VERSION ""

NS_ :

BS_:

BU_: PC PUMPOT DC_DC2 DC_DC1 TTC_30 IMU CANoeSpy MBMS VCU VCVCCU CBCU TMS

BO_ 3221225472 VECTOR__INDEPENDENT_SIG_MSG: 0 Vector__XXX
 SG_ VCVCCU_ChargeUnit_Mode : 0|3@1+ (1,0) [0|0] "" Vector__XXX
 SG_ VCVCCU_Vehicle_ChargeSelection : 0|2@1+ (1,0) [0|3] "" Vector__XXX
 SG_ Year : 0|8@1+ (1,1985) [1985|2235] "Years" Vector__XXX
 SG_ Seconds : 0|8@1+ (0.25,0) [0|59.75] "s" Vector__XXX
 SG_ Month : 0|8@1+ (1,0) [1|12] "months" Vector__XXX
 SG_ Minutes : 0|32@1- (1,0) [0|59] "min" Vector__XXX
 SG_ LocalMinuteOffset : 0|8@1+ (1,-125) [-59|59] "min" Vector__XXX
 SG_ LocalHourOffset : 0|8@1+ (1,-125) [-23|23] "h" Vector__XXX
 SG_ Hours : 0|8@1+ (1,0) [0|23] "h" Vector__XXX
 SG_ Day : 0|8@1+ (0.25,0) [0.25|31.75] "" Vector__XXX
 SG_ SAE_J1587 : 0|2@1+ (1,0) [0|3] "" Vector__XXX
 SG_ DIAG_REQ_VCCU : 0|64@1+ (1,0) [0|1.84467440737096E+019] "" Vector__XXX
 SG_ VCVCCU_data_resp : 0|64@1+ (1,0) [0|0] "" Vector__XXX
 SG_ VCVCCU_data_cmd : 0|64@1+ (1,0) [0|0] "" Vector__XXX
 SG_ tx_error_count_Copy_1 : 0|8@1+ (1,0) [0|0] "" Vector__XXX
 SG_ motor_state : 0|3@1+ (1,0) [0|0] "" Vector__XXX
 SG_ inv_state : 0|3@1+ (1,0) [0|0] "" Vector__XXX
 SG_ spal_control_motor : 0|5@1+ (1,0) [0|0] "" Vector__XXX
 SG_ conclusion_state : 0|3@1+ (1,0) [0|0] "" Vector__XXX
 SG_ ATM_DAT7 : 0|8@1+ (1,0) [255|255] "" Vector__XXX
 SG_ ATM_DAT6 : 0|8@1+ (1,0) [255|255] "" Vector__XXX
 SG_ NewSignal_0018 : 0|8@1+ (1,0) [0|0] "" Vector__XXX
 SG_ Dashboard_Chart7 : 0|2@1+ (1,0) [0|3] "" Vector__XXX
 SG_ Dashboard_Chart6 : 0|2@1+ (1,0) [0|3] "" Vector__XXX
 SG_ Dashboard_Chart5 : 0|2@1+ (1,0) [0|3] "" Vector__XXX
 SG_ Dashboard_Chart4 : 0|2@1+ (1,0) [0|3] "" Vector__XXX
 SG_ Dashboard_Chart3 : 0|2@1+ (1,0) [0|3] "" Vector__XXX
 SG_ Dashboard_Chart2 : 0|2@1+ (1,0) [0|3] "" Vector__XXX
 SG_ Acc_Pedal_Chart2 : 0|3@1+ (1,0) [0|7] "" Vector__XXX
 SG_ Acc_Pedal_Chart3 : 0|2@1+ (1,0) [0|3] "" Vector__XXX
 SG_ Acc_Pedal_Chart1 : 0|2@1+ (1,0) [0|3] "" Vector__XXX
 SG_ TireLocation : 0|8@1+ (1,0) [0|0] "" Vector__XXX
 SG_ DataDictionaryRow : 0|4@1+ (1,0) [0|0] "" Vector__XXX
 SG_ DataDictionaryColumn : 0|4@1+ (1,0) [0|0] "" Vector__XXX
 SG_ ImplementPos : 0|4@1+ (1,0) [0|0] "" Vector__XXX
 SG_ DataFormat_ErrorCondition : 0|2@1+ (1,0) [0|0] "" Vector__XXX
 SG_ ProcessDataType : 0|2@1+ (1,0) [0|0] "" Vector__XXX
 SG_ ProcessDataModifier : 0|3@1+ (1,0) [0|0] "" Vector__XXX
 SG_ VehicleSystemInstanceQualifierFl : 0|1@1+ (1,0) [0|1] "" Vector__XXX
 SG_ VehicleRoll : 0|16@1+ (0.0078125,-200) [-90|90] "deg" Vector__XXX
 SG_ VehicleRetarderCtrlActive : 0|2@1+ (1,0) [0|3] "" Vector__XXX
 SG_ NOxConvertingCatalystAdsorberCom : 0|1@1+ (1,0) [0|1] "" Vector__XXX
 SG_ NOxConvertingCatalystAdsorberEna : 0|1@1+ (1,0) [0|1] "" Vector__XXX
 SG_ BoostPressureControlSystemComple : 0|1@1+ (1,0) [0|1] "" Vector__XXX
 SG_ BoostPressureControlSystemEnable : 0|1@1- (1,0) [0|0] "" Vector__XXX
 SG_ ExtlAccelerationDemand : 0|16@1+ (0.00048828125,-15.687) [-10|10] "m/s²" Vector__XXX
 SG_ IndustryGroup : 0|3@1+ (1,0) [0|7] "" Vector__XXX
 SG_ TestIdentifier : 0|8@1+ (1,0) [0|255] "" Vector__XXX
 SG_ NOxConvertingCatalystAdsorberSta : 0|1@1- (1,0) [0|0] "" Vector__XXX
 SG_ BoostPressureControlSystemSuppor : 0|1@1- (1,0) [0|0] "" Vector__XXX
 SG_ NOxConvertingCatalystAdsorberSup : 0|1@1- (1,0) [0|0] "" Vector__XXX
 SG_ AddressBusy : 0|8@1+ (1,0) [0|255] "" Vector__XXX
 SG_ ParameterGroupNumber : 0|24@1+ (1,0) [0|16777215] "" Vector__XXX
 SG_ GroupFunctionValue : 0|8@1+ (1,0) [0|255] "" Vector__XXX
 SG_ AddressAccessDenied : 0|8@1+ (1,0) [0|255] "" Vector__XXX
 SG_ AddressNegativeAcknowledgement : 0|8@1+ (1,0) [0|255] "" Vector__XXX
 SG_ AddressAcknowledged : 0|8@1+ (1,0) [0|255] "" Vector__XXX
 SG_ ControlByte : 0|8@1+ (1,0) [0|255] "" Vector__XXX
 SG_ AZG_RX_Byte_7 : 0|8@1+ (1,0) [0|0] "" Vector__XXX
 SG_ AZG_RX_Byte_6 : 0|8@1+ (1,0) [0|0] "" Vector__XXX
 SG_ AZG_RX_Byte_5 : 0|8@1+ (1,0) [0|0] "" Vector__XXX
 SG_ AZG_RX_Byte_4 : 0|8@1+ (1,0) [0|0] "" Vector__XXX
 SG_ AZG_RX_Byte_3 : 0|8@1+ (1,0) [0|0] "" Vector__XXX
 SG_ AZG_RX_Byte_2 : 0|8@1+ (1,0) [0|0] "" Vector__XXX
 SG_ AZG_RX_Byte_1 : 0|8@1+ (1,0) [0|0] "" Vector__XXX
 SG_ AZG_RX_Byte_0 : 0|8@1+ (1,0) [0|0] "" Vector__XXX
 SG_ AZG_TX_Byte_7 : 0|8@1+ (1,0) [0|0] "" Vector__XXX
 SG_ AZG_TX_Byte_6 : 0|8@1+ (1,0) [0|0] "" Vector__XXX
 SG_ AZG_TX_Byte_5 : 0|8@1+ (1,0) [0|0] "" Vector__XXX
 SG_ AZG_TX_Byte_4 : 0|8@1+ (1,0) [0|0] "" Vector__XXX
 SG_ AZG_TX_Byte_3 : 0|8@1+ (1,0) [0|0] "" Vector__XXX
 SG_ AZG_TX_Byte_2 : 0|8@1+ (1,0) [0|0] "" Vector__XXX
 SG_ AZG_TX_Byte_1 : 0|8@1+ (1,0) [0|0] "" Vector__XXX
 SG_ AZG_TX_Byte_0 : 0|8@1+ (1,0) [0|0] "" Vector__XXX
 SG_ EcuMeas_3_Byte_7 : 0|8@1+ (1,0) [0|0] "" Vector__XXX
 SG_ EcuMeas_3_Byte_6 : 0|8@1+ (1,0) [0|0] "" Vector__XXX
 SG_ EcuMeas_3_Byte_5 : 0|8@1+ (1,0) [0|0] "" Vector__XXX
 SG_ EcuMeas_3_Byte_4 : 0|8@1+ (1,0) [0|0] "" Vector__XXX
 SG_ EcuMeas_3_Byte_3 : 0|8@1+ (1,0) [0|0] "" Vector__XXX
 SG_ EcuMeas_3_Byte_2 : 0|8@1+ (1,0) [0|0] "" Vector__XXX
 SG_ EcuMeas_3_Byte_1 : 0|8@1+ (1,0) [0|0] "" Vector__XXX
 SG_ EcuMeas_3_Byte_0 : 0|8@1+ (1,0) [0|0] "" Vector__XXX
 SG_ EcuMeas_2_Byte_7 : 0|8@1+ (1,0) [0|0] "" Vector__XXX
 SG_ EcuMeas_2_Byte_6 : 0|8@1+ (1,0) [0|0] "" Vector__XXX
 SG_ EcuMeas_2_Byte_5 : 0|8@1+ (1,0) [0|0] "" Vector__XXX
 SG_ EcuMeas_2_Byte_4 : 0|8@1+ (1,0) [0|0] "" Vector__XXX
 SG_ EcuMeas_2_Byte_3 : 0|8@1+ (1,0) [0|0] "" Vector__XXX
 SG_ EcuMeas_2_Byte_2 : 0|8@1+ (1,0) [0|0] "" Vector__XXX
 SG_ EcuMeas_2_Byte_1 : 0|8@1+ (1,0) [0|0] "" Vector__XXX
 SG_ EcuMeas_2_Byte_0 : 0|8@1+ (1,0) [0|0] "" Vector__XXX
 SG_ EcuMeas_1_Byte_7 : 0|8@1+ (1,0) [0|0] "" Vector__XXX
 SG_ EcuMeas_1_Byte_6 : 0|8@1+ (1,0) [0|0] "" Vector__XXX
 SG_ EcuMeas_1_Byte_5 : 0|8@1+ (1,0) [0|0] "" Vector__XXX
 SG_ EcuMeas_1_Byte_4 : 0|8@1+ (1,0) [0|0] "" Vector__XXX
 SG_ EcuMeas_1_Byte_3 : 0|8@1+ (1,0) [0|0] "" Vector__XXX
 SG_ EcuMeas_1_Byte_2 : 0|8@1+ (1,0) [0|0] "" Vector__XXX
 SG_ EcuMeas_1_Byte_1 : 0|8@1+ (1,0) [0|0] "" Vector__XXX
 SG_ EcuMeas_1_Byte_0 : 0|8@1+ (1,0) [0|0] "" Vector__XXX
 SG_ EcuMeas_0_Byte_7 : 0|8@1+ (1,0) [0|0] "" Vector__XXX
 SG_ EcuMeas_0_Byte_6 : 0|8@1+ (1,0) [0|0] "" Vector__XXX
 SG_ EcuMeas_0_Byte_5 : 0|8@1+ (1,0) [0|0] "" Vector__XXX
 SG_ EcuMeas_0_Byte_4 : 0|8@1+ (1,0) [0|0] "" Vector__XXX
 SG_ EcuMeas_0_Byte_3 : 0|8@1+ (1,0) [0|0] "" Vector__XXX
 SG_ EcuMeas_0_Byte_2 : 0|8@1+ (1,0) [0|0] "" Vector__XXX
 SG_ EcuMeas_0_Byte_1 : 0|8@1+ (1,0) [0|0] "" Vector__XXX
 SG_ EcuMeas_0_Byte_0 : 0|8@1+ (1,0) [0|0] "" Vector__XXX
 SG_ CCP_TX_Byte_7 : 0|8@1+ (1,0) [0|0] "" Vector__XXX
 SG_ CCP_TX_Byte_6 : 0|8@1+ (1,0) [0|0] "" Vector__XXX
 SG_ CCP_TX_Byte_5 : 0|8@1+ (1,0) [0|0] "" Vector__XXX
 SG_ CCP_TX_Byte_4 : 0|8@1+ (1,0) [0|0] "" Vector__XXX
 SG_ CCP_TX_Byte_3 : 0|8@1+ (1,0) [0|0] "" Vector__XXX
 SG_ CCP_TX_Byte_2 : 0|8@1+ (1,0) [0|0] "" Vector__XXX
 SG_ CCP_TX_Byte_1 : 0|8@1+ (1,0) [0|0] "" Vector__XXX
 SG_ CCP_TX_Byte_0 : 0|8@1+ (1,0) [0|0] "" Vector__XXX
 SG_ CCP_RX_Byte_7 : 0|8@1+ (1,0) [0|0] "" Vector__XXX
 SG_ CCP_RX_Byte_6 : 0|8@1+ (1,0) [0|0] "" Vector__XXX
 SG_ CCP_RX_Byte_5 : 0|8@1+ (1,0) [0|0] "" Vector__XXX
 SG_ CCP_RX_Byte_4 : 0|8@1+ (1,0) [0|0] "" Vector__XXX
 SG_ CCP_RX_Byte_3 : 0|8@1+ (1,0) [0|0] "" Vector__XXX
 SG_ CCP_RX_Byte_2 : 0|8@1+ (1,0) [0|0] "" Vector__XXX
 SG_ CCP_RX_Byte_1 : 0|8@1+ (1,0) [0|0] "" Vector__XXX
 SG_ CCP_RX_Byte_0 : 0|8@1+ (1,0) [0|0] "" Vector__XXX
 SG_ YawRate_ISig_3 : 0|16@1+ (0.000122,-3.92) [-3.92|4.07527] "Rad_per_s" Vector__XXX
 SG_ LateralAcceleration_ISig_3 : 0|16@1+ (0.00048828125,-15.687) [-15.687|16.312511719] "m_per_s_squared" Vector__XXX
 SG_ SteeringWheelTurnCounter_ISig_3 : 0|6@1+ (1,-32) [-32|31] "turns" Vector__XXX
 SG_ SteeringWheelAngleSensorType : 0|2@1+ (1,0) [0|0] "" Vector__XXX
 SG_ SteeringWheelAngle_ISig_3 : 0|16@1+ (0.0009765625,-31.374) [-31.374|32.625023437] "rad" Vector__XXX
 SG_ MessageChecksum : 0|4@1+ (1,0) [0|15] "" Vector__XXX
 SG_ MessageCounter : 0|4@1+ (1,0) [0|15] "" Vector__XXX
 SG_ SteerAngleSensorCalibrated : 0|2@1+ (1,0) [0|3] "" Vector__XXX
 SG_ SteerAngleSensorActiveMode : 0|2@1+ (1,0) [0|3] "" Vector__XXX
 SG_ SteerWheelAngleRange : 0|16@1+ (0.0009765625,-31.374) [0|31.374] "rad" Vector__XXX
 SG_ SteerWheelAngleRangeCounterType : 0|2@1+ (1,0) [0|3] "" Vector__XXX
 SG_ SteerWheelAngleRangeCounter : 0|6@1+ (1,-32) [-32|29] "ranges" Vector__XXX
 SG_ SteerWheelAngle : 0|16@1+ (0.0009765625,-31.374) [-31.374|31.374] "rad" Vector__XXX
 SG_ EHPS_DesPumpSpeed : 0|16@1+ (1,0) [0|8000] "rpm" Vector__XXX
 SG_ TachographVehicleSpeed : 0|16@1+ (0.00390625,0) [0|250.996] "km/h" Vector__XXX
 SG_ TachographOutputShaftSpeed : 0|16@1+ (0.125,0) [0|8031.875] "rpm" Vector__XXX
 SG_ DirectionIndicator : 0|2@1+ (1,0) [0|3] "" Vector__XXX
 SG_ TachographPerformance : 0|2@1+ (1,0) [0|3] "" Vector__XXX
 SG_ HandlingInformation : 0|2@1+ (1,0) [0|3] "" Vector__XXX
 SG_ SystemEvent : 0|2@1+ (1,0) [0|3] "" Vector__XXX
 SG_ DriverCardDriver2 : 0|2@1+ (1,0) [0|3] "" Vector__XXX
 SG_ Driver2TimeRelatedStates : 0|4@1+ (1,0) [0|15] "" Vector__XXX
 SG_ VehicleOverspeed : 0|2@1+ (1,0) [0|3] "" Vector__XXX
 SG_ DriverCardDriver1 : 0|2@1+ (1,0) [0|3] "" Vector__XXX
 SG_ Driver1TimeRelatedStates : 0|4@1+ (1,0) [0|15] "" Vector__XXX
 SG_ Driver1WorkingState : 0|3@1+ (1,0) [0|7] "" Vector__XXX
 SG_ VehicleMotion : 0|2@1+ (1,0) [0|3] "" Vector__XXX
 SG_ Driver2WorkingState : 0|3@1+ (1,0) [0|7] "" Vector__XXX
 SG_ RelativeSpeedRearAxle2RightWhel : 0|8@1+ (0.06025,-7.8125) [-7.8125|7.8125] "km/h" Vector__XXX
 SG_ RelativeSpeedRearAxle2LeftWhel : 0|8@1+ (0.0625,-7.8125) [-7.8125|7.8125] "km/h" Vector__XXX
 SG_ RelativeSpeedRearAxle1LeftWhel : 0|8@1+ (0.0625,-7.8125) [-7.8125|7.8125] "km/h" Vector__XXX
 SG_ RelativeSpeedRearAxle1RightWhel : 0|8@1+ (0.0625,-7.8125) [-7.8125|7.8125] "km/h" Vector__XXX
 SG_ RelativeSpeedFrontAxleRightWheel : 0|8@1+ (0.0625,-7.8125) [-7.8125|7.8125] "km/h" Vector__XXX
 SG_ RelativeSpeedFrontAxleLeftWheel : 0|8@1+ (0.0625,-7.8125) [-7.8125|7.8125] "km/h" Vector__XXX
 SG_ FrontAxleSpeed : 0|16@1+ (0.00390625,0) [0|250.996] "km/h" Vector__XXX
 SG_ MotorTorque : 0|16@1+ (1,-31.374) [-31.374|31.374] "Nm" Vector__XXX
 SG_ HandsOffProbability : 0|8@1+ (1,0) [0|100] "%" Vector__XXX
 SG_ ExtControlMode : 0|4@1+ (1,0) [0|0] "" Vector__XXX
 SG_ DriverTorque : 0|16@1+ (0.0009765625,-31.374) [-31.374|31.374] "Nm" Vector__XXX
 SG_ CRC : 0|8@1+ (1,0) [0|0] "" Vector__XXX
 SG_ MC : 0|4@1+ (1,0) [0|0] "" Vector__XXX
 SG_ SysState : 0|4@1+ (1,0) [0|0] "" Vector__XXX
 SG_ SteeringAngleSpeed : 0|16@1+ (0.1,-3212.7) [-3212.7|3212.8] "°/s" Vector__XXX
 SG_ SteeringAngle : 0|16@1+ (0.1,-3212.7) [-3212.7|3212.8] "°" Vector__XXX
 SG_ EngDemandPercentTorque : 0|8@1+ (1,-125) [-125|125] "%" Vector__XXX
 SG_ SrcAddrssOfCntrllngDvcForEngCtrl : 0|8@1+ (1,0) [0|253] "" Vector__XXX
 SG_ ActlEngPrcntTorqueHighResolution : 0|4@1+ (0.125,0) [0|1.875] "%" Vector__XXX
 SG_ EngStarterMode : 0|4@1+ (1,0) [0|15] "" Vector__XXX
 SG_ EngSpeed : 0|16@1+ (0.125,0) [0|8031.875] "rpm" Vector__XXX
 SG_ ActualEngPercentTorque : 0|8@1+ (1,-125) [0|125] "%" Vector__XXX
 SG_ DriversDemandEngPercentTorque : 0|8@1+ (1,-125) [0|125] "%" Vector__XXX
 SG_ EngTorqueMode : 0|4@1+ (1,0) [0|15] "" Vector__XXX
 SG_ Ph_H : 0|8@1+ (100,0) [0|201326492] "Wh" Vector__XXX
 SG_ Ph_HM : 0|8@1+ (100,0) [0|201326492] "Wh" Vector__XXX
 SG_ Ph_LM : 0|8@1+ (100,0) [0|201326492] "Wh" Vector__XXX
 SG_ Ph_L : 0|8@1+ (100,0) [0|201326492] "Wh" Vector__XXX
 SG_ Ih_H : 0|8@1+ (100,0) [0|201326492] "Ah" Vector__XXX
 SG_ Ih_HM : 0|8@1+ (100,0) [0|201326492] "Ah" Vector__XXX
 SG_ ACDC_Temperature : 0|8@1+ (1,-40) [-40|210] "°C" Vector__XXX
 SG_ SG_StatusFeedBack : 0|1@1+ (1,0) [0|71] "" Vector__XXX
 SG_ DTC5 : 0|32@1+ (1,0) [-1|0] "" Vector__XXX
 SG_ DTC4 : 0|32@1+ (1,0) [-1|0] "" Vector__XXX
 SG_ DTC3 : 0|32@1+ (1,0) [-1|0] "" Vector__XXX
 SG_ DTC2 : 0|32@1+ (1,0) [-1|0] "" Vector__XXX
 SG_ DTC1 : 0|32@1+ (1,0) [-1|0] "" Vector__XXX
 SG_ AnswerMode2 : 0|8@1+ (1,0) [0|0] "" Vector__XXX
 SG_ VersionSoftRequest : 0|8@1+ (1,0) [0|255] "" Vector__XXX
 SG_ FlashRedStoplamp : 0|8@1+ (1,0) [0|0] "" Vector__XXX
 SG_ Irbis_TurnOff : 0|1@1+ (1,0) [0|0] "" Vector__XXX
 SG_ BTMDemandPowerHighLowBytes_Copy_ : 0|16@1+ (0.1,0) [0|6553.5] "kW" Vector__XXX
 SG_ Datchick_toka : 0|16@1+ (1,0) [0|65535] "" Vector__XXX
 SG_ PropulsionSystemActive : 0|2@1+ (1,0) [0|0] "" Vector__XXX
 SG_ HybridSystemWarningIndicator : 0|2@1+ (1,0) [0|0] "" Vector__XXX
 SG_ HybridSystemStopIndicator : 0|2@1+ (1,0) [0|0] "" Vector__XXX
 SG_ HybridSystemServiceIndicator : 0|2@1+ (1,0) [0|0] "" Vector__XXX
 SG_ HybridSystemRegenerativeBrakingI : 0|2@1+ (1,0) [0|0] "" Vector__XXX
 SG_ HybridSystemOverheatIndicator : 0|2@1+ (1,0) [0|0] "" Vector__XXX
 SG_ HybridSystemOBDRelatedDTCStatus : 0|2@1+ (1,0) [0|0] "" Vector__XXX
 SG_ HybridSystemMotorOverspeedIndica : 0|2@1+ (1,0) [0|0] "" Vector__XXX
 SG_ HybridSystemMotorOverspeedAlarm : 0|2@1+ (1,0) [0|0] "" Vector__XXX
 SG_ HybridSystemInitialisationIndica : 0|2@1+ (1,0) [0|0] "" Vector__XXX
 SG_ HybridSystemHighVoltageExposureI : 0|2@1+ (1,0) [0|0] "" Vector__XXX
 SG_ HybridSystemEngineAssistStatus : 0|2@1+ (1,0) [0|0] "" Vector__XXX
 SG_ HybridSystemElectricAlternatorIn : 0|2@1+ (1,0) [0|0] "" Vector__XXX
 SG_ HybridPropulsionModeTransitionSt : 0|4@1+ (1,0) [0|0] "" Vector__XXX
 SG_ HybridPropulsionModeStatus : 0|4@1+ (1,0) [0|0] "" Vector__XXX
 SG_ ExternalEnergySourceConnectionSt : 0|4@1+ (1,0) [0|0] "" Vector__XXX
 SG_ StoredEnergyLevel : 0|8@1+ (1,0) [0|100] "%" Vector__XXX
 SG_ PowerOnSignal : 0|2@1+ (1,0) [0|0] "" Vector__XXX
 SG_ DestinationMode : 0|3@1+ (1,0) [0|0] "" Vector__XXX
 SG_ CurrentVehicleMode : 0|3@1+ (1,0) [0|0] "" Vector__XXX
 SG_ SIM100_vb : 0|16@1+ (1,0) [0|0] "" Vector__XXX
 SG_ var6_Copy_1 : 0|24@1+ (1,0) [0|0] "" Vector__XXX
 SG_ saturation2_min_variable_Copy_1 : 0|8@1+ (1,0) [0|0] "" Vector__XXX
 SG_ saturation2_max_variable_Copy_1 : 0|8@1+ (1,0) [0|0] "" Vector__XXX
 SG_ saturation1_min_variable_Copy_1 : 0|8@1+ (1,0) [0|0] "" Vector__XXX
 SG_ saturation1_max_variable_Copy_1 : 0|8@1+ (1,0) [0|0] "" Vector__XXX
 SG_ IBS_looses_recalibration_SOC : 0|2@1+ (1,0) [0|0] "" Vector__XXX
 SG_ Battery_Defect_Detected : 0|2@1+ (1,0) [0|0] "" Vector__XXX
 SG_ Battery_Acid_Stratification : 0|2@1+ (1,0) [0|0] "" Vector__XXX
 SG_ Battery_Sulfation : 0|2@1+ (1,0) [0|0] "" Vector__XXX
 SG_ CentreTapDifference : 0|8@1+ (1,0) [0|0] "" Vector__XXX
 SG_ SOH_CCA : 0|8@1+ (0.5,0) [0|100] "" Vector__XXX
 SG_ CapacityLossBottom : 0|8@1+ (0.5,0) [0|0] "" Vector__XXX
 SG_ CapacityLossTop : 0|8@1+ (0.5,0) [0|0] "" Vector__XXX
 SG_ SOH : 0|8@1+ (0.5,0) [0|100] "" Vector__XXX
 SG_ NumberOfMembersInWorkingSet : 0|8@1+ (1,0) [0|0] "" Vector__XXX
 SG_ SourceAddress : 0|8@1+ (1,0) [0|0] "" Vector__XXX
 SG_ NncntnuslyMonitoredSystemsStatus : 0|16@1+ (1,0) [0|0] "" Vector__XXX
 SG_ NncntnslyMonitoredSystemsSupport : 0|16@1+ (1,0) [0|0] "" Vector__XXX
 SG_ CntnslyMntrdSystmsSupport_Status : 0|8@1+ (1,0) [0|0] "" Vector__XXX
 SG_ AETCTorqueValue : 0|16@1+ (1,0) [0|64255] "Nm" Vector__XXX
 SG_ TrailerWeight : 0|16@1+ (2,0) [0|128510] "kg" Vector__XXX
 SG_ ReferenceTirePressSetting : 0|8@1+ (8,0) [0|2000] "kPa" Vector__XXX
 SG_ ReferenceTirePress : 0|8@1+ (8,0) [0|2000] "kPa" Vector__XXX
 SG_ TirePressThresholdDetection : 0|3@1+ (1,0) [0|7] "" Vector__XXX
 SG_ TireAirLeakageRate : 0|16@1+ (0.1,0) [0|6425.5] "Pa/s" Vector__XXX
 SG_ CTIWheelEndElectricalFault : 0|2@1+ (1,0) [0|3] "" Vector__XXX
 SG_ CTITireStatus : 0|2@1+ (1,0) [0|3] "" Vector__XXX
 SG_ CTIWheelSensorStatus : 0|2@1+ (1,0) [0|3] "" Vector__XXX
 SG_ TireTemp : 0|16@1+ (0.03125,-273) [-273|1734.96875] "deg C" Vector__XXX
 SG_ TirePress : 0|8@1+ (4,0) [0|1000] "kPa" Vector__XXX
 SG_ EngTurningGearEngaged : 0|2@1+ (1,0) [0|3] "" Vector__XXX
 SG_ AETCSpeedValue : 0|16@1+ (0.125,0) [0|8031.875] "rpm" Vector__XXX
 SG_ SWfirst_B : 0|8@0+ (1,0) [0|255] "" Vector__XXX
 SG_ SWsecond_B : 0|8@0+ (1,0) [0|255] "" Vector__XXX
 SG_ SWThird_B : 0|8@0+ (1,0) [0|1] "" Vector__XXX
 SG_ SWFourth_B : 0|8@0+ (1,0) [0|255] "" Vector__XXX
 SG_ SWFifth_B : 0|8@0+ (1,0) [0|255] "" Vector__XXX
 SG_ SWsixth_B : 0|8@0+ (1,0) [0|1] "" Vector__XXX
 SG_ SWseventh_B : 0|8@0+ (1,0) [0|1] "" Vector__XXX
 SG_ SWeight_B : 0|8@0+ (1,0) [0|1] "" Vector__XXX
 SG_ SWfirst_C : 0|8@0+ (1,0) [0|255] "" Vector__XXX
 SG_ SWsecond_C : 0|8@0+ (1,0) [0|255] "" Vector__XXX
 SG_ SWThird_C : 0|8@0+ (1,0) [0|1] "" Vector__XXX
 SG_ SWFourth_C : 0|8@0+ (1,0) [0|255] "" Vector__XXX
 SG_ SWFifth_C : 0|8@0+ (1,0) [0|255] "" Vector__XXX
 SG_ SWsixth_C : 0|8@0+ (1,0) [0|1] "" Vector__XXX
 SG_ SWseventh_C : 0|8@0+ (1,0) [0|1] "" Vector__XXX
 SG_ SWeight_C : 0|8@0+ (1,0) [0|1] "" Vector__XXX
 SG_ SWfirst_D : 0|8@0+ (1,0) [0|255] "" Vector__XXX
 SG_ SWsecond_D : 0|8@0+ (1,0) [0|255] "" Vector__XXX
 SG_ SWThird_D : 0|8@0+ (1,0) [0|1] "" Vector__XXX
 SG_ SWFourth_D : 0|8@0+ (1,0) [0|255] "" Vector__XXX
 SG_ SWFifth_D : 0|8@0+ (1,0) [0|255] "" Vector__XXX
 SG_ SWsixth_D : 0|8@0+ (1,0) [0|1] "" Vector__XXX
 SG_ SWseventh_D : 0|8@0+ (1,0) [0|1] "" Vector__XXX
 SG_ SWeight_D : 0|8@0+ (1,0) [0|1] "" Vector__XXX
 SG_ SWfirst_E : 0|8@0+ (1,0) [0|255] "" Vector__XXX
 SG_ SWsecond_E : 0|8@0+ (1,0) [0|255] "" Vector__XXX
 SG_ SWThird_E : 0|8@0+ (1,0) [0|1] "" Vector__XXX
 SG_ SWFourth_E : 0|8@0+ (1,0) [0|255] "" Vector__XXX
 SG_ SWFifth_E : 0|8@0+ (1,0) [0|255] "" Vector__XXX
 SG_ SWsixth_E : 0|8@0+ (1,0) [0|1] "" Vector__XXX
 SG_ SWseventh_E : 0|8@0+ (1,0) [0|1] "" Vector__XXX
 SG_ SWeight_E : 0|8@0+ (1,0) [0|1] "" Vector__XXX
 SG_ SWfirst_F : 0|8@0+ (1,0) [0|255] "" Vector__XXX
 SG_ SWsecond_F : 0|8@0+ (1,0) [0|255] "" Vector__XXX
 SG_ SWThird_F : 0|8@0+ (1,0) [0|1] "" Vector__XXX
 SG_ SWFourth_F : 0|8@0+ (1,0) [0|255] "" Vector__XXX
 SG_ SWFifth_F : 0|8@0+ (1,0) [0|255] "" Vector__XXX
 SG_ SWsixth_F : 0|8@0+ (1,0) [0|1] "" Vector__XXX
 SG_ SWseventh_F : 0|8@0+ (1,0) [0|1] "" Vector__XXX
 SG_ SWeight_F : 0|8@0+ (1,0) [0|1] "" Vector__XXX
 SG_ SWfirst_G : 0|8@0+ (1,0) [0|255] "" Vector__XXX
 SG_ SWsecond_G : 0|8@0+ (1,0) [0|255] "" Vector__XXX
 SG_ SWThird_G : 0|8@0+ (1,0) [0|1] "" Vector__XXX
 SG_ SWFourth_G : 0|8@0+ (1,0) [0|255] "" Vector__XXX
 SG_ SWFifth_G : 0|8@0+ (1,0) [0|255] "" Vector__XXX
 SG_ SWsixth_G : 0|8@0+ (1,0) [0|1] "" Vector__XXX
 SG_ SWseventh_G : 0|8@0+ (1,0) [0|1] "" Vector__XXX
 SG_ SWeight_G : 0|8@0+ (1,0) [0|1] "" Vector__XXX
 SG_ SWfirst_H : 0|8@0+ (1,0) [0|255] "" Vector__XXX
 SG_ SWsecond_H : 0|8@0+ (1,0) [0|255] "" Vector__XXX
 SG_ SWThird_H : 0|8@0+ (1,0) [0|1] "" Vector__XXX
 SG_ SWFourth_H : 0|8@0+ (1,0) [0|255] "" Vector__XXX
 SG_ SWFifth_H : 0|8@0+ (1,0) [0|255] "" Vector__XXX
 SG_ SWsixth_H : 0|8@0+ (1,0) [0|1] "" Vector__XXX
 SG_ SWseventh_H : 0|8@0+ (1,0) [0|1] "" Vector__XXX
 SG_ SWeight_H : 0|8@0+ (1,0) [0|1] "" Vector__XXX
 SG_ SWfirst_I : 0|8@0+ (1,0) [0|255] "" Vector__XXX
 SG_ SWsecond_I : 0|8@0+ (1,0) [0|255] "" Vector__XXX
 SG_ SWThird_I : 0|8@0+ (1,0) [0|1] "" Vector__XXX
 SG_ SWFourth_I : 0|8@0+ (1,0) [0|255] "" Vector__XXX
 SG_ SWFifth_I : 0|8@0+ (1,0) [0|255] "" Vector__XXX
 SG_ SWsixth_I : 0|8@0+ (1,0) [0|1] "" Vector__XXX
 SG_ SWseventh_I : 0|8@0+ (1,0) [0|1] "" Vector__XXX
 SG_ SWeight_I : 0|8@0+ (1,0) [0|1] "" Vector__XXX
 SG_ SWfirst_L : 0|8@0+ (1,0) [0|255] "" Vector__XXX
 SG_ SWsecond_L : 0|8@0+ (1,0) [0|255] "" Vector__XXX
 SG_ SWThird_L : 0|8@0+ (1,0) [0|1] "" Vector__XXX
 SG_ SWFourth_L : 0|8@0+ (1,0) [0|255] "" Vector__XXX
 SG_ SWFifth_L : 0|8@0+ (1,0) [0|255] "" Vector__XXX
 SG_ SWsixth_L : 0|8@0+ (1,0) [0|1] "" Vector__XXX
 SG_ SWseventh_L : 0|8@0+ (1,0) [0|1] "" Vector__XXX
 SG_ SWeight_L : 0|8@0+ (1,0) [0|1] "" Vector__XXX
 SG_ SWfirst_M : 0|8@0+ (1,0) [0|255] "" Vector__XXX
 SG_ SWsecond_M : 0|8@0+ (1,0) [0|255] "" Vector__XXX
 SG_ SWThird_M : 0|8@0+ (1,0) [0|1] "" Vector__XXX
 SG_ SWFourth_M : 0|8@0+ (1,0) [0|255] "" Vector__XXX
 SG_ SWFifth_M : 0|8@0+ (1,0) [0|255] "" Vector__XXX
 SG_ SWsixth_M : 0|8@0+ (1,0) [0|1] "" Vector__XXX
 SG_ SWseventh_M : 0|8@0+ (1,0) [0|1] "" Vector__XXX
 SG_ SWeight_M : 0|8@0+ (1,0) [0|1] "" Vector__XXX
 SG_ SWfirst_N : 0|8@0+ (1,0) [0|255] "" Vector__XXX
 SG_ SWsecond_N : 0|8@0+ (1,0) [0|255] "" Vector__XXX
 SG_ SWThird_N : 0|8@0+ (1,0) [0|1] "" Vector__XXX
 SG_ SWFourth_N : 0|8@0+ (1,0) [0|255] "" Vector__XXX
 SG_ SWFifth_N : 0|8@0+ (1,0) [0|255] "" Vector__XXX
 SG_ SWsixth_N : 0|8@0+ (1,0) [0|1] "" Vector__XXX
 SG_ SWseventh_N : 0|8@0+ (1,0) [0|1] "" Vector__XXX
 SG_ SWeight_N : 0|8@0+ (1,0) [0|1] "" Vector__XXX
 SG_ SWfirst_Q : 0|8@0+ (1,0) [0|255] "" Vector__XXX
 SG_ SWsecond_Q : 0|8@0+ (1,0) [0|255] "" Vector__XXX
 SG_ SWThird_Q : 0|8@0+ (1,0) [0|1] "" Vector__XXX
 SG_ SWFourth_Q : 0|8@0+ (1,0) [0|255] "" Vector__XXX
 SG_ SWFifth_Q : 0|8@0+ (1,0) [0|255] "" Vector__XXX
 SG_ SWsixth_Q : 0|8@0+ (1,0) [0|1] "" Vector__XXX
 SG_ SWseventh_Q : 0|8@0+ (1,0) [0|1] "" Vector__XXX
 SG_ SWeight_Q : 0|8@0+ (1,0) [0|1] "" Vector__XXX
 SG_ SWfirst_R : 0|8@0+ (1,0) [0|255] "" Vector__XXX
 SG_ SWsecond_R : 0|8@0+ (1,0) [0|255] "" Vector__XXX
 SG_ SWThird_R : 0|8@0+ (1,0) [0|1] "" Vector__XXX
 SG_ SWFourth_R : 0|8@0+ (1,0) [0|255] "" Vector__XXX
 SG_ SWFifth_R : 0|8@0+ (1,0) [0|255] "" Vector__XXX
 SG_ SWsixth_R : 0|8@0+ (1,0) [0|1] "" Vector__XXX
 SG_ SWseventh_R : 0|8@0+ (1,0) [0|1] "" Vector__XXX
 SG_ SWeight_R : 0|8@0+ (1,0) [0|1] "" Vector__XXX
 SG_ Tst2_3Pconfig_C : 0|1@0+ (1,0) [0|1] "" Vector__XXX
 SG_ Tst2Slave_C : 0|1@1+ (1,0) [0|1] "" Vector__XXX
 SG_ IMU_Check : 0|1@1+ (1,0) [0|0] "" Vector__XXX
 SG_ Reserved2 : 0|8@1+ (1,0) [0|0] "" Vector__XXX
 SG_ Reserved1 : 0|2@1+ (1,0) [0|0] "" Vector__XXX
 SG_ Reserved : 0|2@1+ (1,0) [0|0] "" Vector__XXX
 SG_ BMSCurrentVoltageLowByte : 0|8@1+ (1,0) [0|1000] "" Vector__XXX
 SG_ BMSHighVoltageRelayStatus : 0|2@1+ (1,0) [0|3] "" Vector__XXX
 SG_ Isolation_measur_req_by_vcvccu : 0|2@1+ (1,0) [0|0] "" Vector__XXX
 SG_ Voltage_sensor_PDU1 : 0|16@1+ (1,0) [0|65535] "" Vector__XXX
 SG_ Voltage_sensor_PDU2 : 0|16@1+ (1,0) [0|65535] "" Vector__XXX
 SG_ VCUSendsBusVoltHighLowBytes : 0|16@0+ (1,0) [0|1000] "V" Vector__XXX
 SG_ BTMDemandPowerHighLowBytes : 0|16@1+ (0.1,0) [0|6553.5] "kW" Vector__XXX
 SG_ L_byte_offset : 0|8@1+ (1,0) [0|255] "" Vector__XXX
 SG_ H_bye_Offset : 0|8@1+ (1,0) [0|255] "" Vector__XXX
 SG_ VCVCCU_seconds_variable : 0|8@1+ (1,0) [0|0] "" Vector__XXX
 SG_ EVErrorCode : 0|8@1+ (1,0) [0|0] "" Vector__XXX
 SG_ Link_voltage : 0|16@1+ (1,0) [0|0] "" Vector__XXX
 SG_ EVRSSSOC : 0|8@1+ (1,0) [0|0] "" Vector__XXX
 SG_ EVTargetVoltage_Multiplier : 0|8@1+ (1,0) [0|0] "" Vector__XXX
 SG_ EVTargetCurrent_Multiplier : 0|8@1+ (1,0) [0|0] "" Vector__XXX
 SG_ EVMaximumVoltageLimit_Multiplier : 0|8@1+ (1,0) [0|0] "" Vector__XXX
 SG_ HL_byte : 0|16@0+ (1,0) [0|65535] "" Vector__XXX
 SG_ Pantograph_heating : 0|1@1+ (1,0) [0|0] "" Vector__XXX
 SG_ MainContactorState : 0|2@1+ (1,0) [0|0] "" Vector__XXX
 SG_ ActualBatterySystemVoltage : 0|8@1+ (3.4,0) [0|867] "V" Vector__XXX
 SG_ ActualBatterySystemCurrent : 0|8@1- (4,0) [-512|508] "A" Vector__XXX
 SG_ MaximumBatterySystemVoltage : 0|8@1+ (3.4,0) [0|850] "V" Vector__XXX
 SG_ MaximumBatterySystemChargeCurren : 0|8@1+ (2,0) [0|510] "A" Vector__XXX
 SG_ Byte2 : 0|8@1+ (1,0) [0|0] "" Vector__XXX
 SG_ Byte1 : 0|8@1+ (1,0) [0|0] "" Vector__XXX
 SG_ diag_state : 0|16@1+ (1,0) [0|0] "" Vector__XXX
 SG_ k15_status : 0|1@1+ (1,0) [0|0] "" Vector__XXX
 SG_ usability_check : 0|1@1+ (1,0) [0|0] "" Vector__XXX
 SG_ unsuccessful_session : 0|8@1+ (1,0) [0|0] "" Vector__XXX
 SG_ aborted_session : 0|8@1+ (1,0) [0|0] "" Vector__XXX
 SG_ success_session : 0|8@1+ (1,0) [0|0] "" Vector__XXX

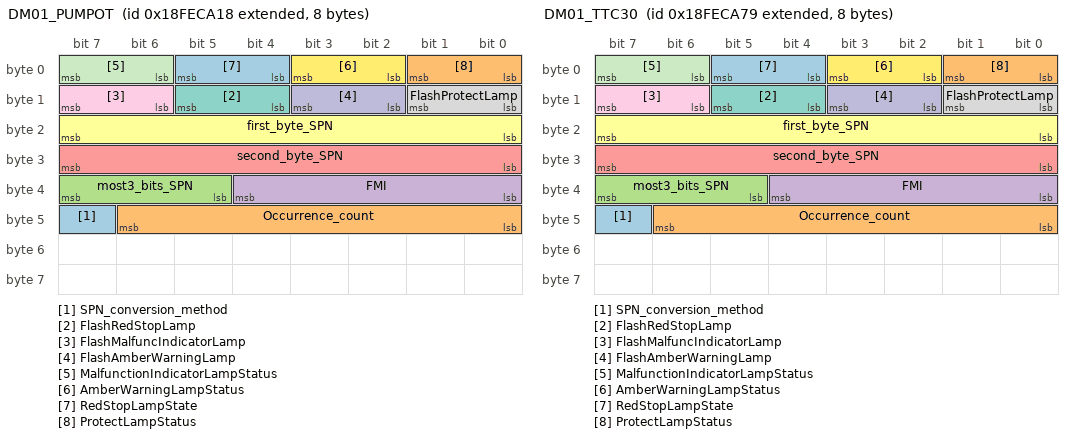
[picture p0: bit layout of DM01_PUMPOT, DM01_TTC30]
BO_ 2566834712 DM01_PUMPOT: 8 Vector__XXX
 SG_ SPN_conversion_method : 47|1@1+ (1,0) [0|0] "" Vector__XXX
 SG_ Occurrence_count : 40|7@1+ (1,0) [0|0] "" Vector__XXX
 SG_ most3_bits_SPN : 37|3@1+ (1,0) [0|0] "" Vector__XXX
 SG_ FMI : 32|5@1+ (1,0) [0|31] "" Vector__XXX
 SG_ second_byte_SPN : 24|8@1+ (1,0) [0|0] "" Vector__XXX
 SG_ first_byte_SPN : 16|8@1+ (1,0) [0|255] "" Vector__XXX
 SG_ FlashRedStopLamp : 12|2@1+ (1,0) [0|3] "" Vector__XXX
 SG_ FlashProtectLamp : 8|2@1+ (1,0) [0|3] "" Vector__XXX
 SG_ FlashMalfuncIndicatorLamp : 14|2@1+ (1,0) [0|3] "" Vector__XXX
 SG_ FlashAmberWarningLamp : 10|2@1+ (1,0) [0|3] "" Vector__XXX
 SG_ MalfunctionIndicatorLampStatus : 6|2@1+ (1,0) [0|3] "" Vector__XXX
 SG_ AmberWarningLampStatus : 2|2@1+ (1,0) [0|3] "" Vector__XXX
 SG_ RedStopLampState : 4|2@1+ (1,0) [0|3] "" Vector__XXX
 SG_ ProtectLampStatus : 0|2@1+ (1,0) [0|3] "" Vector__XXX

BO_ 2566834809 DM01_TTC30: 8 Vector__XXX
 SG_ SPN_conversion_method : 47|1@1+ (1,0) [0|0] "" Vector__XXX
 SG_ Occurrence_count : 40|7@1+ (1,0) [0|0] "" Vector__XXX
 SG_ most3_bits_SPN : 37|3@1+ (1,0) [0|0] "" Vector__XXX
 SG_ FMI : 32|5@1+ (1,0) [0|31] "" Vector__XXX
 SG_ second_byte_SPN : 24|8@1+ (1,0) [0|0] "" Vector__XXX
 SG_ first_byte_SPN : 16|8@1+ (1,0) [0|255] "" Vector__XXX
 SG_ FlashRedStopLamp : 12|2@1+ (1,0) [0|3] "" Vector__XXX
 SG_ FlashProtectLamp : 8|2@1+ (1,0) [0|3] "" Vector__XXX
 SG_ FlashMalfuncIndicatorLamp : 14|2@1+ (1,0) [0|3] "" Vector__XXX
 SG_ FlashAmberWarningLamp : 10|2@1+ (1,0) [0|3] "" Vector__XXX
 SG_ MalfunctionIndicatorLampStatus : 6|2@1+ (1,0) [0|3] "" Vector__XXX
 SG_ AmberWarningLampStatus : 2|2@1+ (1,0) [0|3] "" Vector__XXX
 SG_ RedStopLampState : 4|2@1+ (1,0) [0|3] "" Vector__XXX
 SG_ ProtectLampStatus : 0|2@1+ (1,0) [0|3] "" Vector__XXX

BO_ 2566891047 TTC540_MSG_3: 8 Vector__XXX
 SG_ Act1Vout_C : 23|16@0+ (0.1,0) [0|65535] "" Vector__XXX
 SG_ SG_DCSideV : 0|16@1+ (0.05,0) [0|3276.75] "" Vector__XXX
 SG_ Average_DC_voltage : 32|12@1+ (0.25,0) [0|1023.75] "" Vector__XXX

BO_ 2566890791 TTC540_MSG_2: 8 Vector__XXX
 SG_ KL15_MAIN : 1|1@1+ (1,0) [0|0] ""  VCU
 SG_ BTM_Current : 32|16@1+ (1,0) [0|0] "" Vector__XXX
 SG_ Atmos_Current : 24|8@1+ (1,0) [0|0] "" Vector__XXX
 SG_ TK_Current : 8|16@1+ (1,0) [0|0] "" Vector__XXX
 SG_ no_need_resistor_turn_on : 0|1@1+ (1,0) [0|1] "" Vector__XXX

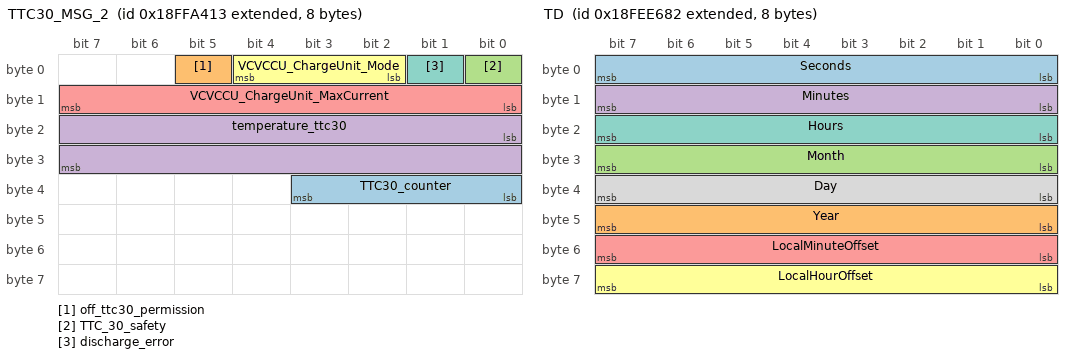
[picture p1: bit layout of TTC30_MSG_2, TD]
BO_ 2566890515 TTC30_MSG_2: 8 Vector__XXX
 SG_ TTC30_counter : 32|4@1+ (1,0) [0|15] "" Vector__XXX
 SG_ off_ttc30_permission : 5|1@1+ (1,0) [0|1] "" Vector__XXX
 SG_ TTC_30_safety : 0|1@1+ (1,0) [0|1] "" Vector__XXX
 SG_ temperature_ttc30 : 16|16@1- (1,0) [-32768|32767] "" Vector__XXX
 SG_ VCVCCU_ChargeUnit_MaxCurrent : 8|8@1+ (1,0) [0|255] "A" Vector__XXX
 SG_ VCVCCU_ChargeUnit_Mode : 2|3@1+ (1,0) [0|7] "" Vector__XXX
 SG_ discharge_error : 1|1@1+ (1,0) [0|1] "" Vector__XXX

BO_ 2566840450 VD: 8 Vector__XXX
 SG_ TripDistance : 0|32@1+ (0.125,0) [0|536870911.875] "km"  VCVCCU
 SG_ TotalVehicleDistance : 32|32@1+ (0.125,0) [0|536870911.875] "km"  VCVCCU

BO_ 2566857346 VCVCCU_V2ICP_VehicleToBackend: 8 Vector__XXX
 SG_ VCVCCU_V2ICP_RequDurationToBatt : 0|8@1+ (1,0) [0|250] "min"  VCVCCU
 SG_ VCVCCU_VICP_ReqToPrecondVeh : 8|8@1+ (1,0) [0|250] "min"  VCVCCU
 SG_ VCVCCU_VICP_ReqEnergyToPrecVeh : 32|16@1+ (1,0) [0|1000] "kWh"  VCVCCU
 SG_ VCVCCU_VICP_ReqEnergyToChargeBat : 16|16@1+ (1,0) [0|1000] "kWh"  VCVCCU

BO_ 2566841986 TD: 8 Vector__XXX
 SG_ Seconds : 0|8@1+ (0.25,0) [0|63.75] "s" Vector__XXX
 SG_ Year : 40|8@1+ (1,1985) [1985|2240] "years"  VCVCCU
 SG_ Month : 24|8@1+ (1,0) [0|255] "months"  VCVCCU
 SG_ Minutes : 8|8@1+ (1,0) [0|255] "min"  VCVCCU
 SG_ LocalMinuteOffset : 48|8@1- (1,0) [-128|127] "min"  VCVCCU
 SG_ LocalHourOffset : 56|8@1- (1,0) [-128|127] "h"  VCVCCU
 SG_ Hours : 16|8@1+ (1,0) [0|255] "h"  VCVCCU
 SG_ Day : 32|8@1+ (0.25,0) [0|63.75] "days"  VCVCCU

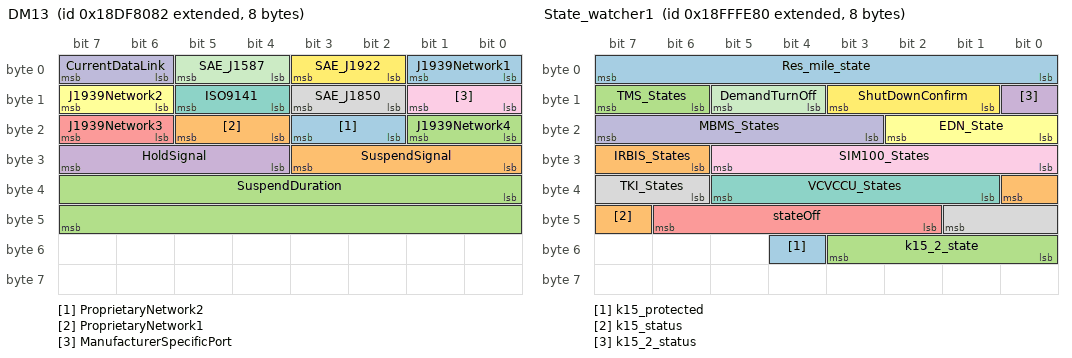
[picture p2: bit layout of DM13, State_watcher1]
BO_ 2564784258 DM13: 8 Vector__XXX
 SG_ ProprietaryNetwork2 : 18|2@1+ (1,0) [0|3] ""  VCVCCU
 SG_ ProprietaryNetwork1 : 20|2@1+ (1,0) [0|3] ""  VCVCCU
 SG_ J1939Network4 : 16|2@1+ (1,0) [0|3] ""  VCVCCU
 SG_ HoldSignal : 28|4@1+ (1,0) [0|15] ""  VCVCCU
 SG_ J1939Network3 : 22|2@1+ (1,0) [0|3] ""  VCVCCU
 SG_ J1939Network2 : 14|2@1+ (1,0) [0|3] ""  VCVCCU
 SG_ ISO9141 : 12|2@1+ (1,0) [0|3] ""  VCVCCU
 SG_ SAE_J1850 : 10|2@1+ (1,0) [0|3] ""  VCVCCU
 SG_ ManufacturerSpecificPort : 8|2@1+ (1,0) [0|3] ""  VCVCCU
 SG_ CurrentDataLink : 6|2@1+ (1,0) [0|3] ""  VCVCCU
 SG_ SAE_J1587 : 4|2@1+ (1,0) [0|3] ""  VCVCCU
 SG_ SAE_J1922 : 2|2@1+ (1,0) [0|3] ""  VCVCCU
 SG_ J1939Network1 : 0|2@1+ (1,0) [0|3] ""  VCVCCU
 SG_ SuspendSignal : 24|4@1+ (1,0) [0|15] ""  VCVCCU
 SG_ SuspendDuration : 32|16@1+ (1,0) [0|64255] "s"  VCVCCU

BO_ 2363129986 DIAG_REQ_VCVCCU: 8 Vector__XXX
 SG_ DIAG_RESP_VCCU : 0|64@1+ (1,0) [0|0] ""  VCVCCU

BO_ 2147485202 VCVCCU_Config_resp: 8 VCVCCU
 SG_ Byte0 : 0|8@1+ (1,0) [0|0] "" Vector__XXX
 SG_ Byte7 : 56|8@1+ (1,0) [0|0] "" Vector__XXX
 SG_ Byte1 : 8|8@1+ (1,0) [0|0] "" Vector__XXX
 SG_ Byte6 : 48|8@1+ (1,0) [0|0] "" Vector__XXX
 SG_ Byte5 : 40|8@1+ (1,0) [0|0] "" Vector__XXX
 SG_ Byte4 : 32|8@1+ (1,0) [0|0] "" Vector__XXX
 SG_ Byte3 : 24|8@1+ (1,0) [0|0] "" Vector__XXX
 SG_ Byte2 : 16|8@1+ (1,0) [0|0] "" Vector__XXX

BO_ 2147485200 VCVCCU_Config_cmd: 8 VCU
 SG_ Byte7 : 56|8@1+ (1,0) [0|0] "" Vector__XXX
 SG_ Byte6 : 48|8@1+ (1,0) [0|0] "" Vector__XXX
 SG_ Byte5 : 40|8@1+ (1,0) [0|0] "" Vector__XXX
 SG_ Byte4 : 32|8@1+ (1,0) [0|0] "" Vector__XXX
 SG_ Byte3 : 24|8@1+ (1,0) [0|0] "" Vector__XXX
 SG_ Byte2 : 16|8@1+ (1,0) [0|0] "" Vector__XXX
 SG_ Byte1 : 8|8@1+ (1,0) [0|0] "" Vector__XXX
 SG_ Byte0 : 0|8@1+ (1,0) [0|0] "" Vector__XXX

BO_ 2566872615 Get_Diagnostic_540_4: 8 VCU
 SG_ error_value : 16|8@1+ (1,0) [0|0] "" Vector__XXX
 SG_ tx_error_count : 8|8@1+ (1,0) [0|0] "" Vector__XXX
 SG_ rx_error_count : 0|8@1+ (1,0) [0|0] "" Vector__XXX

BO_ 2566872871 Get_Diagnostic_540_3: 8 VCU
 SG_ watchdog_state : 56|8@1+ (1,0) [0|0] "" Vector__XXX
 SG_ error_count : 48|8@1+ (1,0) [0|0] "" Vector__XXX
 SG_ diag_state : 32|16@1+ (1,0) [0|0] "" Vector__XXX
 SG_ diag_error_code : 16|16@1+ (1,0) [0|0] "" Vector__XXX
 SG_ diag_device_num : 0|16@1+ (1,0) [0|0] "" Vector__XXX

BO_ 2566913665 State_watcher2: 8 VCU
 SG_ DemandPowerBytes : 25|20@1+ (1,0) [0|0] "" Vector__XXX
 SG_ KL15_2_state : 24|1@1+ (1,0) [0|0] "" Vector__XXX
 SG_ Res_mile : 16|8@1+ (0.1,0) [0|0] "" Vector__XXX
 SG_ Spal_control_main : 8|8@1+ (1,0) [0|0] "" Vector__XXX
 SG_ Spal_control_reserve : 0|8@1+ (1,0) [0|0] "" Vector__XXX

BO_ 2566913664 State_watcher1: 8 VCU
 SG_ k15_protected : 52|1@1+ (1,0) [0|0] "" Vector__XXX
 SG_ k15_status : 47|1@1+ (1,0) [0|0] "" Vector__XXX
 SG_ k15_2_state : 48|4@1+ (1,0) [0|0] "" Vector__XXX
 SG_ k15_2_status : 8|1@1+ (1,0) [0|0] "" Vector__XXX
 SG_ stateOff : 42|5@1+ (1,0) [0|0] "" Vector__XXX
 SG_ EDN_State : 16|3@1+ (1,0) [0|0] "" Vector__XXX
 SG_ VCVCCU_States : 33|5@1+ (1,0) [0|31] "" Vector__XXX
 SG_ TKI_States : 38|4@1+ (1,0) [0|15] "" Vector__XXX
 SG_ SIM100_States : 24|6@1+ (1,0) [0|63] "" Vector__XXX
 SG_ MBMS_States : 19|5@1+ (1,0) [0|31] "" Vector__XXX
 SG_ DemandTurnOff : 12|2@1+ (1,0) [0|3] "" Vector__XXX
 SG_ ShutDownConfirm : 9|3@1+ (1,0) [0|7] "" Vector__XXX
 SG_ Res_mile_state : 0|8@1+ (1,0) [0|255] "" Vector__XXX
 SG_ IRBIS_States : 30|3@1+ (1,0) [0|6] "" Vector__XXX
 SG_ TMS_States : 14|2@1+ (1,0) [0|0] "" Vector__XXX

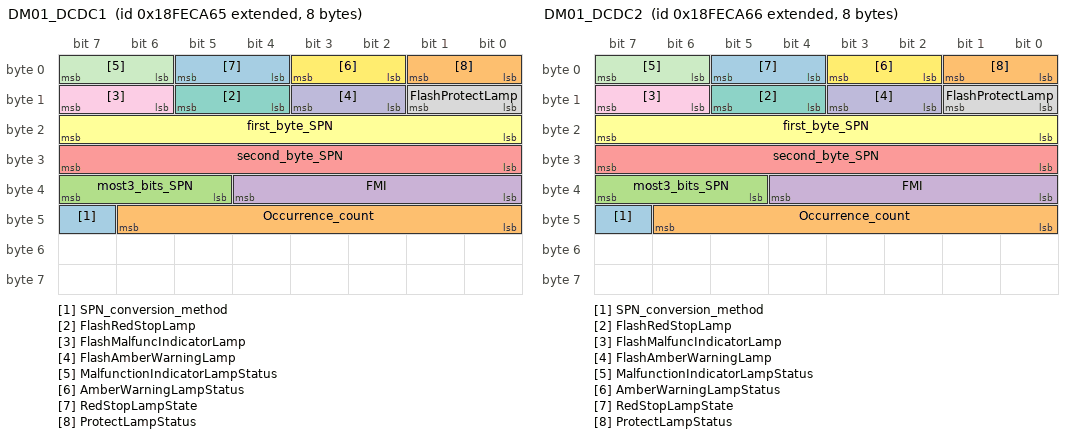
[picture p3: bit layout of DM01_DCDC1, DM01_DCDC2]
BO_ 2566834789 DM01_DCDC1: 8 DC_DC1
 SG_ SPN_conversion_method : 47|1@1+ (1,0) [0|0] "" Vector__XXX
 SG_ Occurrence_count : 40|7@1+ (1,0) [0|0] "" Vector__XXX
 SG_ most3_bits_SPN : 37|3@1+ (1,0) [0|0] "" Vector__XXX
 SG_ FMI : 32|5@1+ (1,0) [0|31] "" Vector__XXX
 SG_ second_byte_SPN : 24|8@1+ (1,0) [0|0] "" Vector__XXX
 SG_ first_byte_SPN : 16|8@1+ (1,0) [0|255] "" Vector__XXX
 SG_ FlashRedStopLamp : 12|2@1+ (1,0) [0|3] "" Vector__XXX
 SG_ FlashProtectLamp : 8|2@1+ (1,0) [0|3] "" Vector__XXX
 SG_ FlashMalfuncIndicatorLamp : 14|2@1+ (1,0) [0|3] "" Vector__XXX
 SG_ FlashAmberWarningLamp : 10|2@1+ (1,0) [0|3] "" Vector__XXX
 SG_ MalfunctionIndicatorLampStatus : 6|2@1+ (1,0) [0|3] "" Vector__XXX
 SG_ AmberWarningLampStatus : 2|2@1+ (1,0) [0|3] "" Vector__XXX
 SG_ RedStopLampState : 4|2@1+ (1,0) [0|3] "" Vector__XXX
 SG_ ProtectLampStatus : 0|2@1+ (1,0) [0|3] "" Vector__XXX

BO_ 2566834790 DM01_DCDC2: 8 DC_DC2
 SG_ SPN_conversion_method : 47|1@1+ (1,0) [0|0] "" Vector__XXX
 SG_ Occurrence_count : 40|7@1+ (1,0) [0|0] "" Vector__XXX
 SG_ most3_bits_SPN : 37|3@1+ (1,0) [0|0] "" Vector__XXX
 SG_ FMI : 32|5@1+ (1,0) [0|31] "" Vector__XXX
 SG_ second_byte_SPN : 24|8@1+ (1,0) [0|0] "" Vector__XXX
 SG_ first_byte_SPN : 16|8@1+ (1,0) [0|255] "" Vector__XXX
 SG_ FlashRedStopLamp : 12|2@1+ (1,0) [0|3] "" Vector__XXX
 SG_ FlashProtectLamp : 8|2@1+ (1,0) [0|3] "" Vector__XXX
 SG_ FlashMalfuncIndicatorLamp : 14|2@1+ (1,0) [0|3] "" Vector__XXX
 SG_ FlashAmberWarningLamp : 10|2@1+ (1,0) [0|3] "" Vector__XXX
 SG_ MalfunctionIndicatorLampStatus : 6|2@1+ (1,0) [0|3] "" Vector__XXX
 SG_ AmberWarningLampStatus : 2|2@1+ (1,0) [0|3] "" Vector__XXX
 SG_ RedStopLampState : 4|2@1+ (1,0) [0|3] "" Vector__XXX
 SG_ ProtectLampStatus : 0|2@1+ (1,0) [0|3] "" Vector__XXX

BO_ 2566871096 Get_Diagnostic_32: 8 TTC_30
 SG_ diag_device_num : 32|16@1+ (1,0) [0|0] "" Vector__XXX
 SG_ diag_error_code : 16|16@1+ (1,0) [0|0] "" Vector__XXX
 SG_ diag_state : 0|16@1+ (1,0) [0|0] "" Vector__XXX

BO_ 2566871591 Get_Diagnostic_540_2: 8 VCU
 SG_ watchdog_device_num : 16|16@1+ (1,0) [0|0] "" Vector__XXX
 SG_ watchdog_error_code : 0|16@1+ (1,0) [0|0] "" Vector__XXX

BO_ 2566871079 Get_Diagnostic_540_1: 8 VCU
 SG_ diag_252_pin : 16|16@1+ (1,0) [0|0] "" Vector__XXX
 SG_ diag_173_pin : 0|16@1+ (1,0) [0|0] "" Vector__XXX

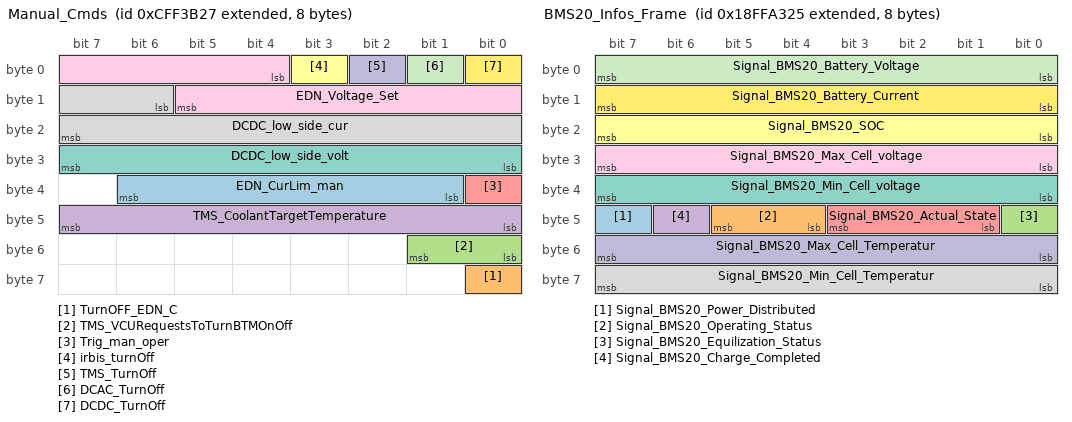
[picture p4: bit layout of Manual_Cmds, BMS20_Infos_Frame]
BO_ 2365537063 Manual_Cmds: 8 Vector__XXX
 SG_ EDN_CurLim_man : 33|6@1+ (1,0) [0|0] "" Vector__XXX
 SG_ TurnOFF_EDN_C : 56|1@1+ (1,0) [0|0] "" Vector__XXX
 SG_ TMS_VCURequestsToTurnBTMOnOff : 48|2@1+ (1,0) [0|3] "" Vector__XXX
 SG_ TMS_CoolantTargetTemperature : 40|8@1+ (1,0) [0|0] "" Vector__XXX
 SG_ Trig_man_oper : 32|1@1+ (1,0) [0|0] "" Vector__XXX
 SG_ irbis_turnOff : 3|1@1+ (1,0) [0|0] "" Vector__XXX
 SG_ DCDC_low_side_volt : 24|8@1+ (1,0) [0|100] "" Vector__XXX
 SG_ DCDC_low_side_cur : 14|10@1+ (1,0) [0|200] "" Vector__XXX
 SG_ EDN_Voltage_Set : 4|10@1+ (1,0) [0|750] "" Vector__XXX
 SG_ TMS_TurnOff : 2|1@1+ (1,0) [0|0] "" Vector__XXX
 SG_ DCAC_TurnOff : 1|1@1+ (1,0) [0|0] "" Vector__XXX
 SG_ DCDC_TurnOff : 0|1@1+ (1,0) [0|0] "" Vector__XXX

BO_ 2566874489 E_Write_CMD_TTC30: 8 PC
 SG_ cmd_2write_value : 16|16@1+ (1,0) [0|65535] "" Vector__XXX
 SG_ cmd_2write_offset : 0|16@1+ (1,0) [0|65535] "" Vector__XXX

BO_ 2349006590 New_Message_146: 8 Vector__XXX
 SG_ New_Signal_1222 : 8|8@1+ (1,0) [0|0] "" Vector__XXX

BO_ 2566851111 Request_speed: 8 Vector__XXX
 SG_ RequestSpeed : 0|8@1- (1,-127) [-128|127] "%"  PUMPOT

BO_ 2566850840 Status: 8 PUMPOT
 SG_ InputVoltage : 24|16@1+ (0.1,0) [0|6425.5] "V" Vector__XXX
 SG_ DriveMotor_Voltage : 8|16@1+ (0.1,0) [0|6425.5] "V" Vector__XXX
 SG_ DriveMotor_Cur : 0|8@1+ (0.1,0) [0|250] "A" Vector__XXX

BO_ 2566858881 Custom_signal_uint16: 2 Vector__XXX
 SG_ Custom_signal_uint16 : 0|16@1+ (1,0) [0|65535] "" Vector__XXX

BO_ 2566870567 States_VCVCCU: 8 Vector__XXX
 SG_ DIB3_Error : 16|16@1+ (1,0) [0|65535] "" Vector__XXX
 SG_ States_VCVCCU : 0|16@1+ (1,0) [0|65535] "" Vector__XXX

BO_ 2566834725 MBMS_DTC: 6 Vector__XXX
 SG_ Signal_MBMS_DM1_OccurCount : 40|7@1+ (1,0) [0|127] "" Vector__XXX
 SG_ Signal_MBMS_DM1_LampStatus : 0|8@1+ (1,0) [0|255] "" Vector__XXX
 SG_ Signal_MBMS_DM1_FlashStatus : 8|8@1+ (1,0) [0|255] "" Vector__XXX
 SG_ Signal_MBMS_DM1_DTCValue : 16|24@1+ (1,0) [0|16777215] "" Vector__XXX
 SG_ Signal_MBMS_DM1_CM : 47|1@1+ (1,0) [0|1] "" Vector__XXX

BO_ 2566890277 BMS20_Infos_Frame: 8 Vector__XXX
 SG_ Signal_BMS20_Power_Distributed : 47|1@1+ (1,0) [0|1] "" Vector__XXX
 SG_ Signal_BMS20_Operating_Status : 44|2@1+ (1,0) [0|0] "" Vector__XXX
 SG_ Signal_BMS20_Equilization_Status : 40|1@1+ (1,0) [0|1] "" Vector__XXX
 SG_ Signal_BMS20_Charge_Completed : 46|1@1+ (1,0) [0|1] "" Vector__XXX
 SG_ Signal_BMS20_Actual_State : 41|3@1+ (1,0) [0|0] "" Vector__XXX
 SG_ Signal_BMS20_SOC : 16|8@1+ (0.4,0) [0|100] "%" Vector__XXX
 SG_ Signal_BMS20_Min_Cell_voltage : 32|8@1+ (20,0) [0|5000] "mV" Vector__XXX
 SG_ Signal_BMS20_Min_Cell_Temperatur : 56|8@1+ (1,-40) [-40|210] "°C" Vector__XXX
 SG_ Signal_BMS20_Max_Cell_voltage : 24|8@1+ (20,0) [0|5000] "mV" Vector__XXX
 SG_ Signal_BMS20_Max_Cell_Temperatur : 48|8@1+ (1,-40) [-40|210] "°C" Vector__XXX
 SG_ Signal_BMS20_Battery_Voltage : 0|8@1+ (3.4,0) [0|850] "V" Vector__XXX
 SG_ Signal_BMS20_Battery_Current : 8|8@1+ (4,-500) [-500|500] "A" Vector__XXX

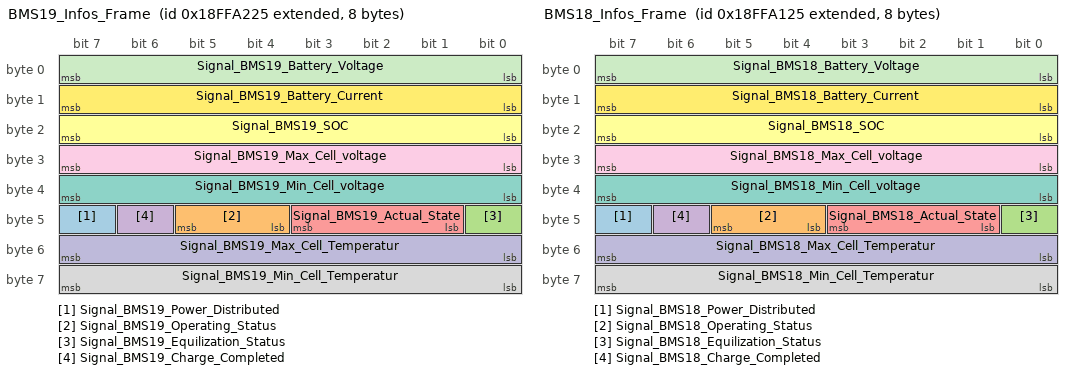
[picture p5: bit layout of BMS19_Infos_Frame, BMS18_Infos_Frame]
BO_ 2566890021 BMS19_Infos_Frame: 8 Vector__XXX
 SG_ Signal_BMS19_Power_Distributed : 47|1@1+ (1,0) [0|1] "" Vector__XXX
 SG_ Signal_BMS19_Operating_Status : 44|2@1+ (1,0) [0|0] "" Vector__XXX
 SG_ Signal_BMS19_Equilization_Status : 40|1@1+ (1,0) [0|1] "" Vector__XXX
 SG_ Signal_BMS19_Charge_Completed : 46|1@1+ (1,0) [0|1] "" Vector__XXX
 SG_ Signal_BMS19_Actual_State : 41|3@1+ (1,0) [0|0] "" Vector__XXX
 SG_ Signal_BMS19_SOC : 16|8@1+ (0.4,0) [0|100] "%" Vector__XXX
 SG_ Signal_BMS19_Min_Cell_voltage : 32|8@1+ (20,0) [0|5000] "mV" Vector__XXX
 SG_ Signal_BMS19_Min_Cell_Temperatur : 56|8@1+ (1,-40) [-40|210] "°C" Vector__XXX
 SG_ Signal_BMS19_Max_Cell_voltage : 24|8@1+ (20,0) [0|5000] "mV" Vector__XXX
 SG_ Signal_BMS19_Max_Cell_Temperatur : 48|8@1+ (1,-40) [-40|210] "°C" Vector__XXX
 SG_ Signal_BMS19_Battery_Voltage : 0|8@1+ (3.4,0) [0|850] "V" Vector__XXX
 SG_ Signal_BMS19_Battery_Current : 8|8@1+ (4,-500) [-500|500] "A" Vector__XXX

BO_ 2566889765 BMS18_Infos_Frame: 8 Vector__XXX
 SG_ Signal_BMS18_Power_Distributed : 47|1@1+ (1,0) [0|1] "" Vector__XXX
 SG_ Signal_BMS18_Operating_Status : 44|2@1+ (1,0) [0|0] "" Vector__XXX
 SG_ Signal_BMS18_Equilization_Status : 40|1@1+ (1,0) [0|1] "" Vector__XXX
 SG_ Signal_BMS18_Charge_Completed : 46|1@1+ (1,0) [0|1] "" Vector__XXX
 SG_ Signal_BMS18_Actual_State : 41|3@1+ (1,0) [0|0] "" Vector__XXX
 SG_ Signal_BMS18_SOC : 16|8@1+ (0.4,0) [0|100] "%" Vector__XXX
 SG_ Signal_BMS18_Min_Cell_voltage : 32|8@1+ (20,0) [0|5000] "mV" Vector__XXX
 SG_ Signal_BMS18_Min_Cell_Temperatur : 56|8@1+ (1,-40) [-40|210] "°C" Vector__XXX
 SG_ Signal_BMS18_Max_Cell_voltage : 24|8@1+ (20,0) [0|5000] "mV" Vector__XXX
 SG_ Signal_BMS18_Max_Cell_Temperatur : 48|8@1+ (1,-40) [-40|210] "°C" Vector__XXX
 SG_ Signal_BMS18_Battery_Voltage : 0|8@1+ (3.4,0) [0|850] "V" Vector__XXX
 SG_ Signal_BMS18_Battery_Current : 8|8@1+ (4,-500) [-500|500] "A" Vector__XXX

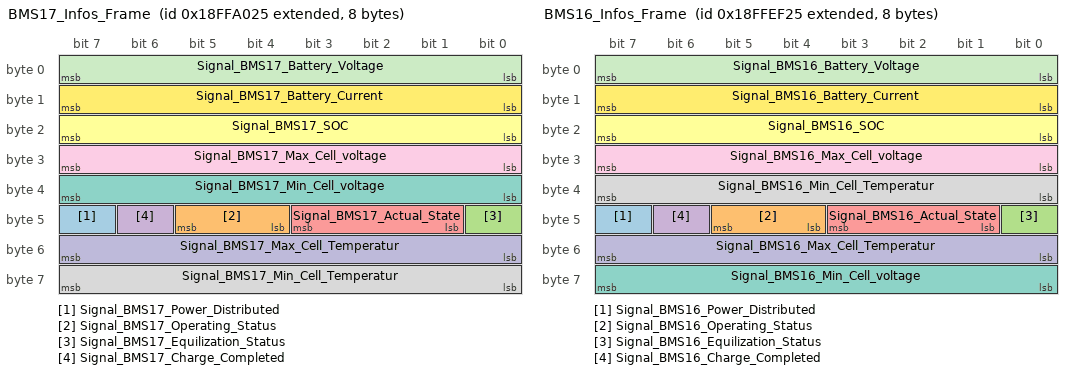
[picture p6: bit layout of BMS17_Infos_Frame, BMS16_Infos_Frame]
BO_ 2566889509 BMS17_Infos_Frame: 8 Vector__XXX
 SG_ Signal_BMS17_Power_Distributed : 47|1@1+ (1,0) [0|1] "" Vector__XXX
 SG_ Signal_BMS17_Operating_Status : 44|2@1+ (1,0) [0|0] "" Vector__XXX
 SG_ Signal_BMS17_Equilization_Status : 40|1@1+ (1,0) [0|1] "" Vector__XXX
 SG_ Signal_BMS17_Charge_Completed : 46|1@1+ (1,0) [0|1] "" Vector__XXX
 SG_ Signal_BMS17_Actual_State : 41|3@1+ (1,0) [0|0] "" Vector__XXX
 SG_ Signal_BMS17_SOC : 16|8@1+ (0.4,0) [0|100] "%" Vector__XXX
 SG_ Signal_BMS17_Min_Cell_voltage : 32|8@1+ (20,0) [0|5000] "mV" Vector__XXX
 SG_ Signal_BMS17_Min_Cell_Temperatur : 56|8@1+ (1,-40) [-40|210] "°C" Vector__XXX
 SG_ Signal_BMS17_Max_Cell_voltage : 24|8@1+ (20,0) [0|5000] "mV" Vector__XXX
 SG_ Signal_BMS17_Max_Cell_Temperatur : 48|8@1+ (1,-40) [-40|210] "°C" Vector__XXX
 SG_ Signal_BMS17_Battery_Voltage : 0|8@1+ (3.4,0) [0|850] "V" Vector__XXX
 SG_ Signal_BMS17_Battery_Current : 8|8@1+ (4,-500) [-500|500] "A" Vector__XXX

BO_ 2566909733 BMS16_Infos_Frame: 8 Vector__XXX
 SG_ Signal_BMS16_Power_Distributed : 47|1@1+ (1,0) [0|1] "" Vector__XXX
 SG_ Signal_BMS16_Operating_Status : 44|2@1+ (1,0) [0|0] "" Vector__XXX
 SG_ Signal_BMS16_Equilization_Status : 40|1@1+ (1,0) [0|1] "" Vector__XXX
 SG_ Signal_BMS16_Charge_Completed : 46|1@1+ (1,0) [0|1] "" Vector__XXX
 SG_ Signal_BMS16_Actual_State : 41|3@1+ (1,0) [0|0] "" Vector__XXX
 SG_ Signal_BMS16_SOC : 16|8@1+ (0.4,0) [0|100] "%" Vector__XXX
 SG_ Signal_BMS16_Min_Cell_voltage : 56|8@1+ (20,0) [0|5000] "mV" Vector__XXX
 SG_ Signal_BMS16_Min_Cell_Temperatur : 32|8@1+ (1,-40) [-40|210] "°C" Vector__XXX
 SG_ Signal_BMS16_Max_Cell_voltage : 24|8@1+ (20,0) [0|5000] "mV" Vector__XXX
 SG_ Signal_BMS16_Max_Cell_Temperatur : 48|8@1+ (1,-40) [-40|210] "°C" Vector__XXX
 SG_ Signal_BMS16_Battery_Voltage : 0|8@1+ (3.4,0) [0|850] "V" Vector__XXX
 SG_ Signal_BMS16_Battery_Current : 8|8@1+ (4,-500) [-500|520] "A" Vector__XXX

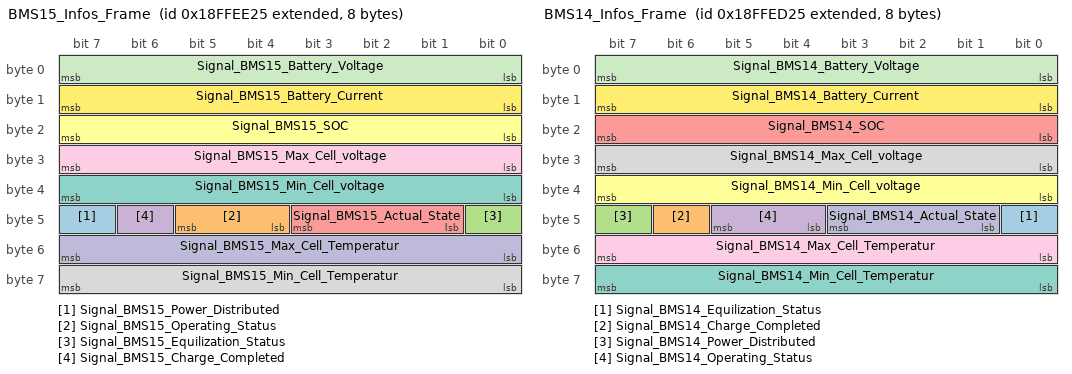
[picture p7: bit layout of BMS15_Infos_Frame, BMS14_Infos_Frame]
BO_ 2566909477 BMS15_Infos_Frame: 8 Vector__XXX
 SG_ Signal_BMS15_Power_Distributed : 47|1@1+ (1,0) [0|1] "" Vector__XXX
 SG_ Signal_BMS15_Operating_Status : 44|2@1+ (1,0) [0|0] "" Vector__XXX
 SG_ Signal_BMS15_Equilization_Status : 40|1@1+ (1,0) [0|1] "" Vector__XXX
 SG_ Signal_BMS15_Charge_Completed : 46|1@1+ (1,0) [0|1] "" Vector__XXX
 SG_ Signal_BMS15_Actual_State : 41|3@1+ (1,0) [0|0] "" Vector__XXX
 SG_ Signal_BMS15_SOC : 16|8@1+ (0.4,0) [0|100] "%" Vector__XXX
 SG_ Signal_BMS15_Min_Cell_voltage : 32|8@1+ (20,0) [0|5000] "mV" Vector__XXX
 SG_ Signal_BMS15_Min_Cell_Temperatur : 56|8@1+ (1,-40) [-40|210] "°C" Vector__XXX
 SG_ Signal_BMS15_Max_Cell_voltage : 24|8@1+ (20,0) [0|5000] "mV" Vector__XXX
 SG_ Signal_BMS15_Max_Cell_Temperatur : 48|8@1+ (1,-40) [-40|210] "°C" Vector__XXX
 SG_ Signal_BMS15_Battery_Voltage : 0|8@1+ (3.4,0) [0|850] "V" Vector__XXX
 SG_ Signal_BMS15_Battery_Current : 8|8@1+ (4,-500) [-500|500] "A" Vector__XXX

BO_ 2566909221 BMS14_Infos_Frame: 8 Vector__XXX
 SG_ Signal_BMS14_Equilization_Status : 40|1@1+ (1,0) [0|1] "" Vector__XXX
 SG_ Signal_BMS14_Charge_Completed : 46|1@1+ (1,0) [0|1] "" Vector__XXX
 SG_ Signal_BMS14_Power_Distributed : 47|1@1+ (1,0) [0|1] "" Vector__XXX
 SG_ Signal_BMS14_Operating_Status : 44|2@1+ (1,0) [0|0] "" Vector__XXX
 SG_ Signal_BMS14_SOC : 16|8@1+ (0.4,0) [0|100] "%" Vector__XXX
 SG_ Signal_BMS14_Min_Cell_voltage : 32|8@1+ (20,0) [0|5000] "mV" Vector__XXX
 SG_ Signal_BMS14_Min_Cell_Temperatur : 56|8@1+ (1,-40) [-40|210] "°C" Vector__XXX
 SG_ Signal_BMS14_Max_Cell_voltage : 24|8@1+ (20,0) [0|5000] "mV" Vector__XXX
 SG_ Signal_BMS14_Max_Cell_Temperatur : 48|8@1+ (1,-40) [-40|210] "°C" Vector__XXX
 SG_ Signal_BMS14_Actual_State : 41|3@1+ (1,0) [0|0] "" Vector__XXX
 SG_ Signal_BMS14_Battery_Voltage : 0|8@1+ (3.4,0) [0|850] "V" Vector__XXX
 SG_ Signal_BMS14_Battery_Current : 8|8@1+ (4,-500) [-500|500] "A" Vector__XXX

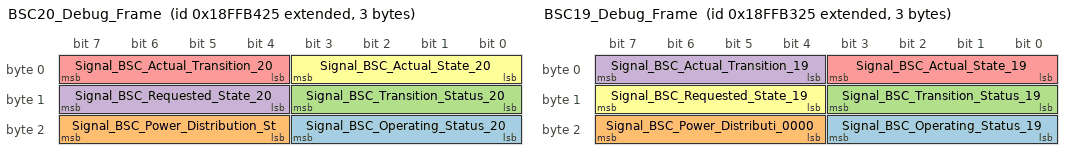
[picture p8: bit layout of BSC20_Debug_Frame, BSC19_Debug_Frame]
BO_ 2566894629 BSC20_Debug_Frame: 3 Vector__XXX
 SG_ Signal_BSC_Operating_Status_20 : 16|4@1+ (1,0) [0|0] "" Vector__XXX
 SG_ Signal_BSC_Power_Distribution_St : 20|4@1+ (1,0) [0|0] "" Vector__XXX
 SG_ Signal_BSC_Transition_Status_20 : 8|4@1+ (1,0) [0|0] "" Vector__XXX
 SG_ Signal_BSC_Requested_State_20 : 12|4@1+ (1,0) [0|0] "" Vector__XXX
 SG_ Signal_BSC_Actual_Transition_20 : 4|4@1+ (1,0) [0|0] "" Vector__XXX
 SG_ Signal_BSC_Actual_State_20 : 0|4@1+ (1,0) [0|0] "" Vector__XXX

BO_ 2566894373 BSC19_Debug_Frame: 3 Vector__XXX
 SG_ Signal_BSC_Operating_Status_19 : 16|4@1+ (1,0) [0|0] "" Vector__XXX
 SG_ Signal_BSC_Power_Distributi_0000 : 20|4@1+ (1,0) [0|0] "" Vector__XXX
 SG_ Signal_BSC_Transition_Status_19 : 8|4@1+ (1,0) [0|0] "" Vector__XXX
 SG_ Signal_BSC_Actual_Transition_19 : 4|4@1+ (1,0) [0|0] "" Vector__XXX
 SG_ Signal_BSC_Actual_State_19 : 0|4@1+ (1,0) [0|0] "" Vector__XXX
 SG_ Signal_BSC_Requested_State_19 : 12|4@1+ (1,0) [0|0] "" Vector__XXX

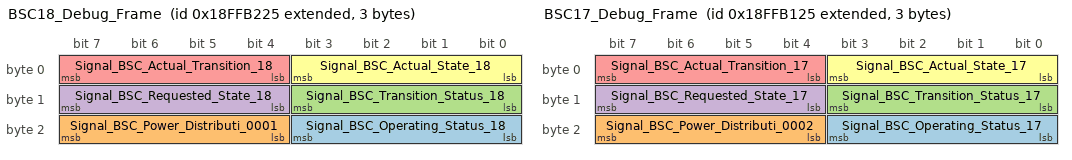
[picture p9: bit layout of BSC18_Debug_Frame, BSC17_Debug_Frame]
BO_ 2566894117 BSC18_Debug_Frame: 3 Vector__XXX
 SG_ Signal_BSC_Operating_Status_18 : 16|4@1+ (1,0) [0|0] "" Vector__XXX
 SG_ Signal_BSC_Power_Distributi_0001 : 20|4@1+ (1,0) [0|0] "" Vector__XXX
 SG_ Signal_BSC_Transition_Status_18 : 8|4@1+ (1,0) [0|0] "" Vector__XXX
 SG_ Signal_BSC_Requested_State_18 : 12|4@1+ (1,0) [0|0] "" Vector__XXX
 SG_ Signal_BSC_Actual_Transition_18 : 4|4@1+ (1,0) [0|0] "" Vector__XXX
 SG_ Signal_BSC_Actual_State_18 : 0|4@1+ (1,0) [0|0] "" Vector__XXX

BO_ 2566893861 BSC17_Debug_Frame: 3 Vector__XXX
 SG_ Signal_BSC_Operating_Status_17 : 16|4@1+ (1,0) [0|0] "" Vector__XXX
 SG_ Signal_BSC_Power_Distributi_0002 : 20|4@1+ (1,0) [0|0] "" Vector__XXX
 SG_ Signal_BSC_Transition_Status_17 : 8|4@1+ (1,0) [0|0] "" Vector__XXX
 SG_ Signal_BSC_Requested_State_17 : 12|4@1+ (1,0) [0|0] "" Vector__XXX
 SG_ Signal_BSC_Actual_Transition_17 : 4|4@1+ (1,0) [0|0] "" Vector__XXX
 SG_ Signal_BSC_Actual_State_17 : 0|4@1+ (1,0) [0|0] "" Vector__XXX

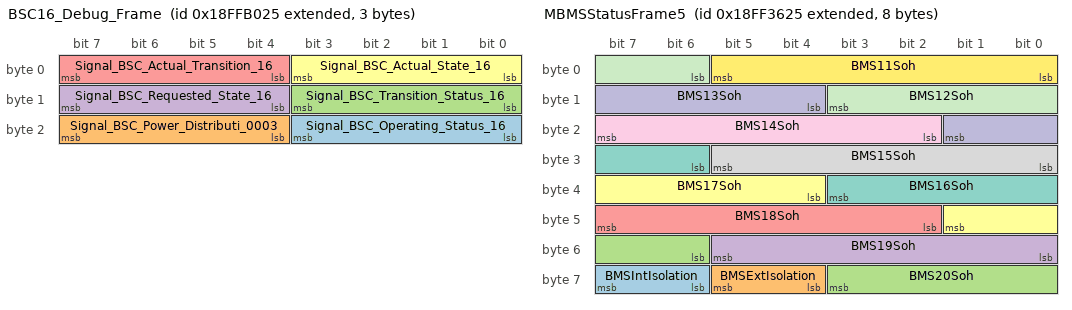
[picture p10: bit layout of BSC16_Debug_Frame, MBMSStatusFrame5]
BO_ 2566893605 BSC16_Debug_Frame: 3 Vector__XXX
 SG_ Signal_BSC_Operating_Status_16 : 16|4@1+ (1,0) [0|0] "" Vector__XXX
 SG_ Signal_BSC_Power_Distributi_0003 : 20|4@1+ (1,0) [0|0] "" Vector__XXX
 SG_ Signal_BSC_Transition_Status_16 : 8|4@1+ (1,0) [0|0] "" Vector__XXX
 SG_ Signal_BSC_Requested_State_16 : 12|4@1+ (1,0) [0|0] "" Vector__XXX
 SG_ Signal_BSC_Actual_Transition_16 : 4|4@1+ (1,0) [0|0] "" Vector__XXX
 SG_ Signal_BSC_Actual_State_16 : 0|4@1+ (1,0) [0|0] "" Vector__XXX

BO_ 2566864933 CLIM_LTO_STATUS: 8 MBMS
 SG_ Signal_ChillerTempSensFlowDefect : 36|1@1+ (1,0) [0|0] "" Vector__XXX
 SG_ Signal_ChillerSoftSTBHeater : 33|1@1+ (1,0) [0|0] "" Vector__XXX
 SG_ Signal_ChillerSoftHighPresSwitch : 38|1@1+ (1,0) [0|0] "" Vector__XXX
 SG_ Signal_ChillerPumpCircuitBreaker : 46|1@1+ (1,0) [0|0] "" Vector__XXX
 SG_ Signal_ChillerLowWaterLevelWar : 39|1@1+ (1,0) [0|0] "" Vector__XXX
 SG_ Signal_ChillerLowWaterLevel : 37|1@1+ (1,0) [0|0] "" Vector__XXX
 SG_ Signal_ChillerHighPressSensDef : 35|1@1+ (1,0) [0|0] "" Vector__XXX
 SG_ Signal_ChillerHighLevelCooling : 40|1@1+ (1,0) [0|0] "" Vector__XXX
 SG_ Signal_ChillerHardSTBHeater : 32|1@1+ (1,0) [0|0] "" Vector__XXX
 SG_ Signal_ChillerFanFault : 47|1@1+ (1,0) [0|0] "" Vector__XXX
 SG_ Signal_ChillerCoolingState : 0|4@1+ (1,0) [0|0] "" Vector__XXX
 SG_ Signal_ChillerComFaultWithBat : 45|1@1+ (1,0) [0|0] "" Vector__XXX
 SG_ Signal_ChillerAllTempSensDefect : 34|1@1+ (1,0) [0|0] "" Vector__XXX
 SG_ Signal_Chiller1FanSpeed : 24|8@1+ (1,0) [0|0] "" Vector__XXX
 SG_ Signal_Chiller1ErrorType : 4|4@1+ (1,0) [0|0] "" Vector__XXX
 SG_ Signal_Chiller1CompressorSpeed : 16|8@1+ (1,0) [0|0] "" Vector__XXX
 SG_ Signal_Chiller1_MedTemp : 8|8@1- (1,-40) [0|0] "" Vector__XXX

BO_ 2566902565 CLEANBAT_MBMS04_DM1: 6 Vector__XXX
 SG_ Signal_Battery_DM1_OccurCoun_004 : 41|7@1+ (1,0) [0|127] "" Vector__XXX
 SG_ Signal_Battery_DM1_LampStatus_00 : 0|8@1+ (1,0) [0|255] "" Vector__XXX
 SG_ Signal_Battery_DM1_FlashStatus_0 : 8|8@1+ (1,0) [0|255] "" Vector__XXX
 SG_ Signal_Battery_DM1_DTCValue_004 : 16|24@1+ (1,0) [0|16777215] "" Vector__XXX
 SG_ Signal_Battery_DM1_CM_004 : 40|1@1+ (1,0) [0|1] "" Vector__XXX

BO_ 2566902309 CLEANBAT_MBMS03_DM1: 6 Vector__XXX
 SG_ Signal_Battery_DM1_OccurCoun_003 : 41|7@1+ (1,0) [0|127] "" Vector__XXX
 SG_ Signal_Battery_DM1_LampStat_0000 : 0|8@1+ (1,0) [0|255] "" Vector__XXX
 SG_ Signal_Battery_DM1_FlashSta_0000 : 8|8@1+ (1,0) [0|255] "" Vector__XXX
 SG_ Signal_Battery_DM1_DTCValue_003 : 16|24@1+ (1,0) [0|16777215] "" Vector__XXX
 SG_ Signal_Battery_DM1_CM_003 : 40|1@1+ (1,0) [0|1] "" Vector__XXX

BO_ 2566902053 CLEANBAT_MBMS02_DM1: 6 Vector__XXX
 SG_ Signal_Battery_DM1_OccurCoun_002 : 41|7@1+ (1,0) [0|127] "" Vector__XXX
 SG_ Signal_Battery_DM1_LampStat_0001 : 0|8@1+ (1,0) [0|255] "" Vector__XXX
 SG_ Signal_Battery_DM1_FlashSta_0001 : 8|8@1+ (1,0) [0|255] "" Vector__XXX
 SG_ Signal_Battery_DM1_DTCValue_002 : 16|24@1+ (1,0) [0|16777215] "" Vector__XXX
 SG_ Signal_Battery_DM1_CM_002 : 40|1@1+ (1,0) [0|1] "" Vector__XXX

BO_ 2566901797 CLEANBAT_MBMS01_DM1: 6 MBMS
 SG_ Signal_Battery_DM1_OccurCoun_001 : 40|7@1+ (1,0) [0|127] "" Vector__XXX
 SG_ Signal_Battery_DM1_LampStat_0002 : 0|8@1+ (1,0) [0|255] "" Vector__XXX
 SG_ Signal_Battery_DM1_FlashSta_0002 : 8|8@1+ (1,0) [0|255] "" Vector__XXX
 SG_ Signal_Battery_DM1_DTCValue_001 : 16|24@1+ (1,0) [0|16777215] "" Vector__XXX
 SG_ Signal_Battery_DM1_CM_001 : 47|1@1+ (1,0) [0|1] "" Vector__XXX

BO_ 2566862373 MBMSStatusFrame5: 8 MBMS
 SG_ BMSIntIsolation : 62|2@1+ (1,0) [0|3] "" Vector__XXX
 SG_ BMSExtIsolation : 60|2@1+ (1,0) [0|3] "" Vector__XXX
 SG_ BMS20Soh : 54|6@1+ (1,39) [39|100] "" Vector__XXX
 SG_ BMS19Soh : 48|6@1+ (1,39) [39|100] "" Vector__XXX
 SG_ BMS18Soh : 42|6@1+ (1,39) [39|100] "" Vector__XXX
 SG_ BMS17Soh : 36|6@1+ (1,39) [39|100] "" Vector__XXX
 SG_ BMS16Soh : 30|6@1+ (1,39) [39|100] "" Vector__XXX
 SG_ BMS15Soh : 24|6@1+ (1,39) [39|100] "" Vector__XXX
 SG_ BMS14Soh : 18|6@1+ (1,39) [39|100] "" Vector__XXX
 SG_ BMS13Soh : 12|6@1+ (1,39) [39|100] "" Vector__XXX
 SG_ BMS12Soh : 6|6@1+ (1,39) [39|100] "" Vector__XXX
 SG_ BMS11Soh : 0|6@1+ (1,39) [39|100] "" Vector__XXX

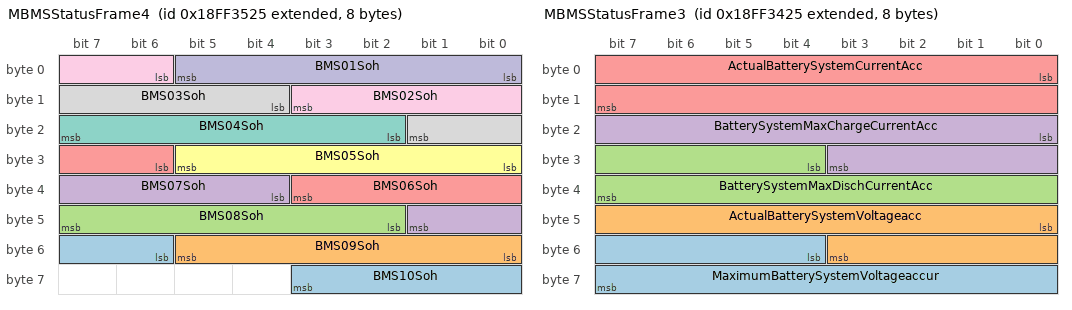
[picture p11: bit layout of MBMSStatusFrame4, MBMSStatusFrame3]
BO_ 2566862117 MBMSStatusFrame4: 8 MBMS
 SG_ BMS10Soh : 54|6@1+ (1,39) [39|100] "" Vector__XXX
 SG_ BMS09Soh : 48|6@1+ (1,39) [39|100] "" Vector__XXX
 SG_ BMS08Soh : 42|6@1+ (1,39) [39|100] "" Vector__XXX
 SG_ BMS07Soh : 36|6@1+ (1,39) [39|100] "" Vector__XXX
 SG_ BMS06Soh : 30|6@1+ (1,39) [39|100] "" Vector__XXX
 SG_ BMS05Soh : 24|6@1+ (1,39) [39|100] "" Vector__XXX
 SG_ BMS04Soh : 18|6@1+ (1,39) [39|100] "" Vector__XXX
 SG_ BMS03Soh : 12|6@1+ (1,39) [39|100] "" Vector__XXX
 SG_ BMS02Soh : 6|6@1+ (1,39) [39|100] "" Vector__XXX
 SG_ BMS01Soh : 0|6@1+ (1,39) [39|100] "" Vector__XXX

BO_ 2566861861 MBMSStatusFrame3: 8 MBMS
 SG_ MaximumBatterySystemVoltageaccur : 52|12@1- (1,0) [0|1100] "" Vector__XXX
 SG_ ActualBatterySystemVoltageacc : 40|12@1+ (1,0) [0|1100] "" Vector__XXX
 SG_ BatterySystemMaxDischCurrentAcc : 28|12@1+ (1,0) [0|4000] "" Vector__XXX
 SG_ BatterySystemMaxChargeCurrentAcc : 16|12@1+ (1,0) [0|4000] "" Vector__XXX
 SG_ ActualBatterySystemCurrentAcc : 0|16@1+ (0.5,-8000) [-8000|24767.5] "" Vector__XXX

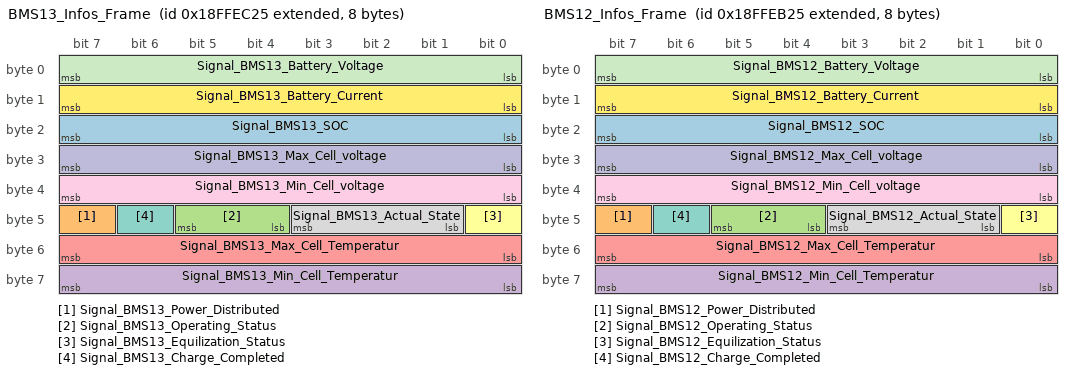
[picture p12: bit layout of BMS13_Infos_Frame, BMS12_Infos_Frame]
BO_ 2566908965 BMS13_Infos_Frame: 8 MBMS
 SG_ Signal_BMS13_SOC : 16|8@1+ (0.4,0) [0|100] "%" Vector__XXX
 SG_ Signal_BMS13_Power_Distributed : 47|1@1+ (1,0) [0|1] "" Vector__XXX
 SG_ Signal_BMS13_Operating_Status : 44|2@1+ (1,0) [0|0] "" Vector__XXX
 SG_ Signal_BMS13_Min_Cell_Temperatur : 56|8@1+ (1,-40) [-40|210] "°C" Vector__XXX
 SG_ Signal_BMS13_Max_Cell_Temperatur : 48|8@1+ (1,-40) [-40|210] "°C" Vector__XXX
 SG_ Signal_BMS13_Equilization_Status : 40|1@1+ (1,0) [0|1] "" Vector__XXX
 SG_ Signal_BMS13_Charge_Completed : 46|1@1+ (1,0) [0|1] "" Vector__XXX
 SG_ Signal_BMS13_Actual_State : 41|3@1+ (1,0) [0|0] "" Vector__XXX
 SG_ Signal_BMS13_Min_Cell_voltage : 32|8@1+ (20,0) [0|5000] "mV" Vector__XXX
 SG_ Signal_BMS13_Max_Cell_voltage : 24|8@1+ (20,0) [0|5000] "mV" Vector__XXX
 SG_ Signal_BMS13_Battery_Voltage : 0|8@1+ (3.4,0) [0|850] "V" Vector__XXX
 SG_ Signal_BMS13_Battery_Current : 8|8@1+ (4,-500) [-500|500] "A" Vector__XXX

BO_ 2566908709 BMS12_Infos_Frame: 8 MBMS
 SG_ Signal_BMS12_SOC : 16|8@1+ (0.4,0) [0|100] "%" Vector__XXX
 SG_ Signal_BMS12_Power_Distributed : 47|1@1+ (1,0) [0|1] "" Vector__XXX
 SG_ Signal_BMS12_Operating_Status : 44|2@1+ (1,0) [0|0] "" Vector__XXX
 SG_ Signal_BMS12_Min_Cell_Temperatur : 56|8@1+ (1,-40) [-40|210] "°C" Vector__XXX
 SG_ Signal_BMS12_Max_Cell_Temperatur : 48|8@1+ (1,-40) [-40|210] "°C" Vector__XXX
 SG_ Signal_BMS12_Equilization_Status : 40|1@1+ (1,0) [0|1] "" Vector__XXX
 SG_ Signal_BMS12_Charge_Completed : 46|1@1+ (1,0) [0|1] "" Vector__XXX
 SG_ Signal_BMS12_Actual_State : 41|3@1+ (1,0) [0|0] "" Vector__XXX
 SG_ Signal_BMS12_Min_Cell_voltage : 32|8@1+ (20,0) [0|5000] "mV" Vector__XXX
 SG_ Signal_BMS12_Max_Cell_voltage : 24|8@1+ (20,0) [0|5000] "mV" Vector__XXX
 SG_ Signal_BMS12_Battery_Voltage : 0|8@1+ (3.4,0) [0|850] "V" Vector__XXX
 SG_ Signal_BMS12_Battery_Current : 8|8@1+ (4,-500) [-500|500] "A" Vector__XXX

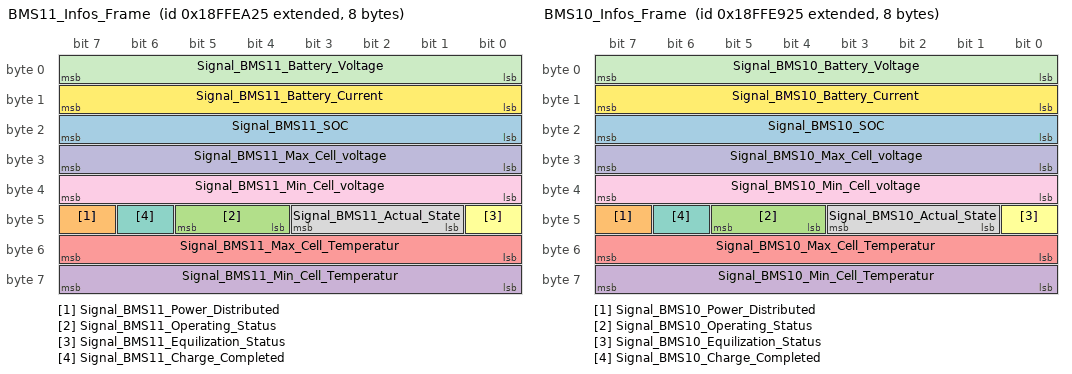
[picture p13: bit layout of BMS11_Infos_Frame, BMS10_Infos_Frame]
BO_ 2566908453 BMS11_Infos_Frame: 8 MBMS
 SG_ Signal_BMS11_SOC : 16|8@1+ (0.4,0) [0|100] "%" Vector__XXX
 SG_ Signal_BMS11_Power_Distributed : 47|1@1+ (1,0) [0|1] "" Vector__XXX
 SG_ Signal_BMS11_Operating_Status : 44|2@1+ (1,0) [0|0] "" Vector__XXX
 SG_ Signal_BMS11_Min_Cell_Temperatur : 56|8@1+ (1,-40) [-40|210] "°C" Vector__XXX
 SG_ Signal_BMS11_Max_Cell_Temperatur : 48|8@1+ (1,-40) [-40|210] "°C" Vector__XXX
 SG_ Signal_BMS11_Equilization_Status : 40|1@1+ (1,0) [0|1] "" Vector__XXX
 SG_ Signal_BMS11_Charge_Completed : 46|1@1+ (1,0) [0|1] "" Vector__XXX
 SG_ Signal_BMS11_Actual_State : 41|3@1+ (1,0) [0|0] "" Vector__XXX
 SG_ Signal_BMS11_Min_Cell_voltage : 32|8@1+ (20,0) [0|5000] "mV" Vector__XXX
 SG_ Signal_BMS11_Max_Cell_voltage : 24|8@1+ (20,0) [0|5000] "mV" Vector__XXX
 SG_ Signal_BMS11_Battery_Voltage : 0|8@1+ (3.4,0) [0|850] "V" Vector__XXX
 SG_ Signal_BMS11_Battery_Current : 8|8@1+ (4,-500) [-500|500] "A" Vector__XXX

BO_ 2566908197 BMS10_Infos_Frame: 8 MBMS
 SG_ Signal_BMS10_SOC : 16|8@1+ (0.4,0) [0|100] "%" Vector__XXX
 SG_ Signal_BMS10_Power_Distributed : 47|1@1+ (1,0) [0|1] "" Vector__XXX
 SG_ Signal_BMS10_Operating_Status : 44|2@1+ (1,0) [0|0] "" Vector__XXX
 SG_ Signal_BMS10_Min_Cell_Temperatur : 56|8@1+ (1,-40) [-40|210] "°C" Vector__XXX
 SG_ Signal_BMS10_Max_Cell_Temperatur : 48|8@1+ (1,-40) [-40|210] "°C" Vector__XXX
 SG_ Signal_BMS10_Equilization_Status : 40|1@1+ (1,0) [0|1] "" Vector__XXX
 SG_ Signal_BMS10_Charge_Completed : 46|1@1+ (1,0) [0|1] "" Vector__XXX
 SG_ Signal_BMS10_Actual_State : 41|3@1+ (1,0) [0|0] "" Vector__XXX
 SG_ Signal_BMS10_Min_Cell_voltage : 32|8@1+ (20,0) [0|5000] "mV" Vector__XXX
 SG_ Signal_BMS10_Max_Cell_voltage : 24|8@1+ (20,0) [0|5000] "mV" Vector__XXX
 SG_ Signal_BMS10_Battery_Voltage : 0|8@1+ (3.4,0) [0|850] "V" Vector__XXX
 SG_ Signal_BMS10_Battery_Current : 8|8@1+ (4,-500) [-500|500] "A" Vector__XXX

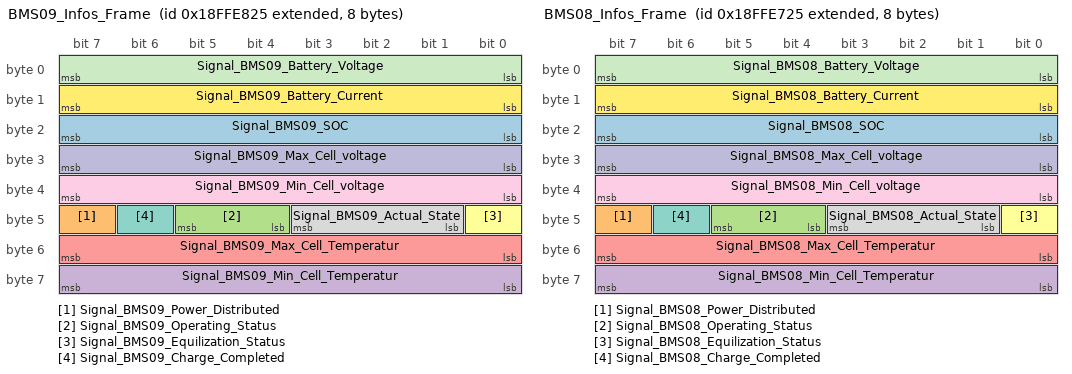
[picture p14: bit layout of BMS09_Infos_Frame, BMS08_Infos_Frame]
BO_ 2566907941 BMS09_Infos_Frame: 8 MBMS
 SG_ Signal_BMS09_SOC : 16|8@1+ (0.4,0) [0|100] "%" Vector__XXX
 SG_ Signal_BMS09_Power_Distributed : 47|1@1+ (1,0) [0|1] "" Vector__XXX
 SG_ Signal_BMS09_Operating_Status : 44|2@1+ (1,0) [0|0] "" Vector__XXX
 SG_ Signal_BMS09_Min_Cell_Temperatur : 56|8@1+ (1,-40) [-40|210] "°C" Vector__XXX
 SG_ Signal_BMS09_Max_Cell_Temperatur : 48|8@1+ (1,-40) [-40|210] "°C" Vector__XXX
 SG_ Signal_BMS09_Equilization_Status : 40|1@1+ (1,0) [0|1] "" Vector__XXX
 SG_ Signal_BMS09_Charge_Completed : 46|1@1+ (1,0) [0|1] "" Vector__XXX
 SG_ Signal_BMS09_Actual_State : 41|3@1+ (1,0) [0|0] "" Vector__XXX
 SG_ Signal_BMS09_Min_Cell_voltage : 32|8@1+ (20,0) [0|5000] "mV" Vector__XXX
 SG_ Signal_BMS09_Max_Cell_voltage : 24|8@1+ (20,0) [0|5000] "mV" Vector__XXX
 SG_ Signal_BMS09_Battery_Voltage : 0|8@1+ (3.4,0) [0|850] "V" Vector__XXX
 SG_ Signal_BMS09_Battery_Current : 8|8@1+ (4,-500) [-500|500] "A" Vector__XXX

BO_ 2566907685 BMS08_Infos_Frame: 8 MBMS
 SG_ Signal_BMS08_SOC : 16|8@1+ (0.4,0) [0|100] "%" Vector__XXX
 SG_ Signal_BMS08_Power_Distributed : 47|1@1+ (1,0) [0|1] "" Vector__XXX
 SG_ Signal_BMS08_Operating_Status : 44|2@1+ (1,0) [0|0] "" Vector__XXX
 SG_ Signal_BMS08_Min_Cell_Temperatur : 56|8@1+ (1,-40) [-40|210] "°C" Vector__XXX
 SG_ Signal_BMS08_Max_Cell_Temperatur : 48|8@1+ (1,-40) [-40|210] "°C" Vector__XXX
 SG_ Signal_BMS08_Equilization_Status : 40|1@1+ (1,0) [0|1] "" Vector__XXX
 SG_ Signal_BMS08_Charge_Completed : 46|1@1+ (1,0) [0|1] "" Vector__XXX
 SG_ Signal_BMS08_Actual_State : 41|3@1+ (1,0) [0|0] "" Vector__XXX
 SG_ Signal_BMS08_Min_Cell_voltage : 32|8@1+ (20,0) [0|5000] "mV" Vector__XXX
 SG_ Signal_BMS08_Max_Cell_voltage : 24|8@1+ (20,0) [0|5000] "mV" Vector__XXX
 SG_ Signal_BMS08_Battery_Voltage : 0|8@1+ (3.4,0) [0|850] "V" Vector__XXX
 SG_ Signal_BMS08_Battery_Current : 8|8@1+ (4,-500) [-500|500] "A" Vector__XXX

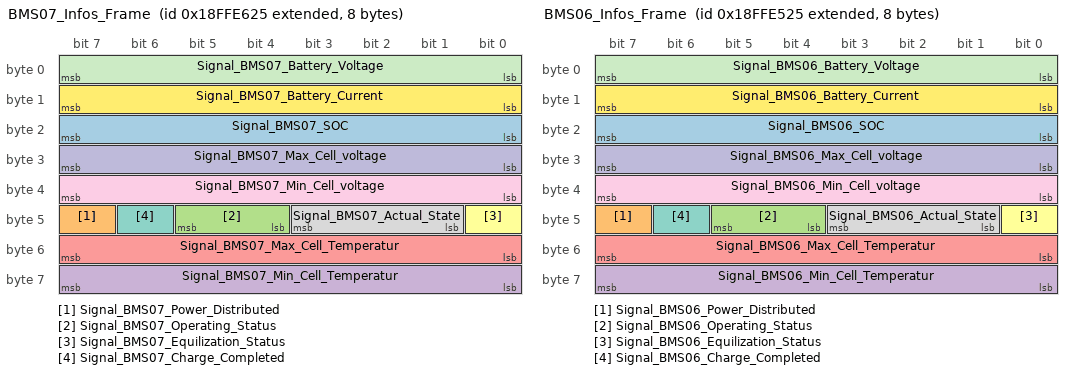
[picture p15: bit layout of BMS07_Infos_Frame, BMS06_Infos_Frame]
BO_ 2566907429 BMS07_Infos_Frame: 8 MBMS
 SG_ Signal_BMS07_SOC : 16|8@1+ (0.4,0) [0|100] "%" Vector__XXX
 SG_ Signal_BMS07_Power_Distributed : 47|1@1+ (1,0) [0|1] "" Vector__XXX
 SG_ Signal_BMS07_Operating_Status : 44|2@1+ (1,0) [0|0] "" Vector__XXX
 SG_ Signal_BMS07_Min_Cell_Temperatur : 56|8@1+ (1,-40) [-40|210] "°C" Vector__XXX
 SG_ Signal_BMS07_Max_Cell_Temperatur : 48|8@1+ (1,-40) [-40|210] "°C" Vector__XXX
 SG_ Signal_BMS07_Equilization_Status : 40|1@1+ (1,0) [0|1] "" Vector__XXX
 SG_ Signal_BMS07_Charge_Completed : 46|1@1+ (1,0) [0|1] "" Vector__XXX
 SG_ Signal_BMS07_Actual_State : 41|3@1+ (1,0) [0|0] "" Vector__XXX
 SG_ Signal_BMS07_Min_Cell_voltage : 32|8@1+ (20,0) [0|5000] "mV" Vector__XXX
 SG_ Signal_BMS07_Max_Cell_voltage : 24|8@1+ (20,0) [0|5000] "mV" Vector__XXX
 SG_ Signal_BMS07_Battery_Voltage : 0|8@1+ (3.4,0) [0|850] "V" Vector__XXX
 SG_ Signal_BMS07_Battery_Current : 8|8@1+ (4,-500) [-500|500] "A" Vector__XXX

BO_ 2566907173 BMS06_Infos_Frame: 8 MBMS
 SG_ Signal_BMS06_SOC : 16|8@1+ (0.4,0) [0|100] "%" Vector__XXX
 SG_ Signal_BMS06_Power_Distributed : 47|1@1+ (1,0) [0|1] "" Vector__XXX
 SG_ Signal_BMS06_Operating_Status : 44|2@1+ (1,0) [0|0] "" Vector__XXX
 SG_ Signal_BMS06_Min_Cell_Temperatur : 56|8@1+ (1,-40) [-40|210] "°C" Vector__XXX
 SG_ Signal_BMS06_Max_Cell_Temperatur : 48|8@1+ (1,-40) [-40|210] "°C" Vector__XXX
 SG_ Signal_BMS06_Equilization_Status : 40|1@1+ (1,0) [0|1] "" Vector__XXX
 SG_ Signal_BMS06_Charge_Completed : 46|1@1+ (1,0) [0|1] "" Vector__XXX
 SG_ Signal_BMS06_Actual_State : 41|3@1+ (1,0) [0|0] "" Vector__XXX
 SG_ Signal_BMS06_Min_Cell_voltage : 32|8@1+ (20,0) [0|5000] "mV" Vector__XXX
 SG_ Signal_BMS06_Max_Cell_voltage : 24|8@1+ (20,0) [0|5000] "mV" Vector__XXX
 SG_ Signal_BMS06_Battery_Voltage : 0|8@1+ (3.4,0) [0|850] "V" Vector__XXX
 SG_ Signal_BMS06_Battery_Current : 8|8@1+ (4,-500) [-500|500] "A" Vector__XXX

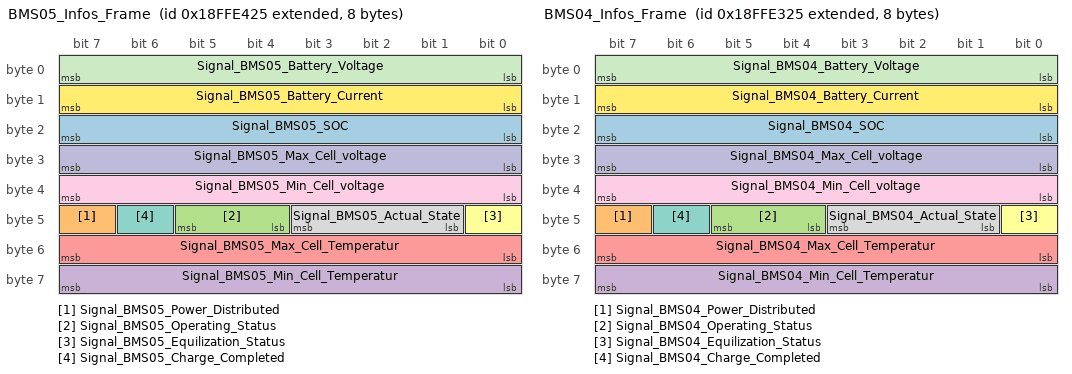
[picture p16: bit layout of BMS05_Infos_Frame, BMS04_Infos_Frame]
BO_ 2566906917 BMS05_Infos_Frame: 8 MBMS
 SG_ Signal_BMS05_SOC : 16|8@1+ (0.4,0) [0|100] "%" Vector__XXX
 SG_ Signal_BMS05_Power_Distributed : 47|1@1+ (1,0) [0|1] "" Vector__XXX
 SG_ Signal_BMS05_Operating_Status : 44|2@1+ (1,0) [0|0] "" Vector__XXX
 SG_ Signal_BMS05_Min_Cell_Temperatur : 56|8@1+ (1,-40) [-40|210] "°C" Vector__XXX
 SG_ Signal_BMS05_Max_Cell_Temperatur : 48|8@1+ (1,-40) [-40|210] "°C" Vector__XXX
 SG_ Signal_BMS05_Equilization_Status : 40|1@1+ (1,0) [0|1] "" Vector__XXX
 SG_ Signal_BMS05_Charge_Completed : 46|1@1+ (1,0) [0|1] "" Vector__XXX
 SG_ Signal_BMS05_Actual_State : 41|3@1+ (1,0) [0|0] "" Vector__XXX
 SG_ Signal_BMS05_Min_Cell_voltage : 32|8@1+ (20,0) [0|5000] "mV" Vector__XXX
 SG_ Signal_BMS05_Max_Cell_voltage : 24|8@1+ (20,0) [0|5000] "mV" Vector__XXX
 SG_ Signal_BMS05_Battery_Voltage : 0|8@1+ (3.4,0) [0|850] "V" Vector__XXX
 SG_ Signal_BMS05_Battery_Current : 8|8@1+ (4,-500) [-500|500] "A" Vector__XXX

BO_ 2566906661 BMS04_Infos_Frame: 8 MBMS
 SG_ Signal_BMS04_SOC : 16|8@1+ (0.4,0) [0|100] "%" Vector__XXX
 SG_ Signal_BMS04_Power_Distributed : 47|1@1+ (1,0) [0|1] "" Vector__XXX
 SG_ Signal_BMS04_Operating_Status : 44|2@1+ (1,0) [0|0] "" Vector__XXX
 SG_ Signal_BMS04_Min_Cell_Temperatur : 56|8@1+ (1,-40) [-40|210] "°C" Vector__XXX
 SG_ Signal_BMS04_Max_Cell_Temperatur : 48|8@1+ (1,-40) [-40|210] "°C" Vector__XXX
 SG_ Signal_BMS04_Equilization_Status : 40|1@1+ (1,0) [0|1] "" Vector__XXX
 SG_ Signal_BMS04_Charge_Completed : 46|1@1+ (1,0) [0|1] "" Vector__XXX
 SG_ Signal_BMS04_Actual_State : 41|3@1+ (1,0) [0|0] "" Vector__XXX
 SG_ Signal_BMS04_Min_Cell_voltage : 32|8@1+ (20,0) [0|5000] "mV" Vector__XXX
 SG_ Signal_BMS04_Max_Cell_voltage : 24|8@1+ (20,0) [0|5000] "mV" Vector__XXX
 SG_ Signal_BMS04_Battery_Voltage : 0|8@1+ (3.4,0) [0|850] "V" Vector__XXX
 SG_ Signal_BMS04_Battery_Current : 8|8@1+ (4,-500) [-500|500] "A" Vector__XXX

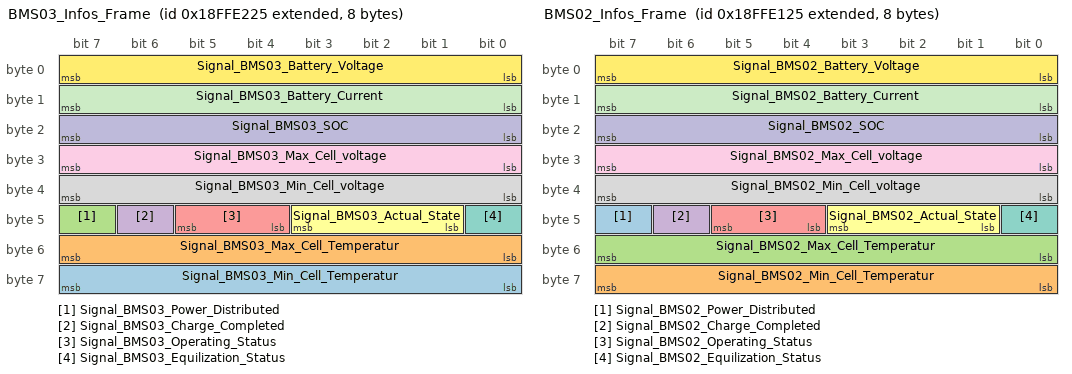
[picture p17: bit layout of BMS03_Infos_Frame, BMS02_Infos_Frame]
BO_ 2566906405 BMS03_Infos_Frame: 8 MBMS
 SG_ Signal_BMS03_Min_Cell_Temperatur : 56|8@1+ (1,-40) [-40|210] "°C" Vector__XXX
 SG_ Signal_BMS03_Max_Cell_Temperatur : 48|8@1+ (1,-40) [-40|210] "°C" Vector__XXX
 SG_ Signal_BMS03_Power_Distributed : 47|1@1+ (1,0) [0|1] "" Vector__XXX
 SG_ Signal_BMS03_Charge_Completed : 46|1@1+ (1,0) [0|1] "" Vector__XXX
 SG_ Signal_BMS03_Operating_Status : 44|2@1+ (1,0) [0|0] "" Vector__XXX
 SG_ Signal_BMS03_Actual_State : 41|3@1+ (1,0) [0|0] "" Vector__XXX
 SG_ Signal_BMS03_Equilization_Status : 40|1@1+ (1,0) [0|1] "" Vector__XXX
 SG_ Signal_BMS03_Min_Cell_voltage : 32|8@1+ (20,0) [0|5000] "mV" Vector__XXX
 SG_ Signal_BMS03_Max_Cell_voltage : 24|8@1+ (20,0) [0|5000] "mV" Vector__XXX
 SG_ Signal_BMS03_SOC : 16|8@1+ (0.4,0) [0|100] "%" Vector__XXX
 SG_ Signal_BMS03_Battery_Current : 8|8@1+ (4,-500) [-500|500] "A" Vector__XXX
 SG_ Signal_BMS03_Battery_Voltage : 0|8@1+ (3.4,0) [0|850] "V" Vector__XXX

BO_ 2566906149 BMS02_Infos_Frame: 8 MBMS
 SG_ Signal_BMS02_Power_Distributed : 47|1@1+ (1,0) [0|1] "" Vector__XXX
 SG_ Signal_BMS02_Min_Cell_Temperatur : 56|8@1+ (1,-40) [-40|210] "°C" Vector__XXX
 SG_ Signal_BMS02_Max_Cell_Temperatur : 48|8@1+ (1,-40) [-40|210] "°C" Vector__XXX
 SG_ Signal_BMS02_Charge_Completed : 46|1@1+ (1,0) [0|1] "" Vector__XXX
 SG_ Signal_BMS02_Operating_Status : 44|2@1+ (1,0) [0|0] "" Vector__XXX
 SG_ Signal_BMS02_Actual_State : 41|3@1+ (1,0) [0|0] "" Vector__XXX
 SG_ Signal_BMS02_Equilization_Status : 40|1@1+ (1,0) [0|1] "" Vector__XXX
 SG_ Signal_BMS02_Min_Cell_voltage : 32|8@1+ (20,0) [0|5000] "mV" Vector__XXX
 SG_ Signal_BMS02_Max_Cell_voltage : 24|8@1+ (20,0) [0|5000] "mV" Vector__XXX
 SG_ Signal_BMS02_SOC : 16|8@1+ (0.4,0) [0|100] "%" Vector__XXX
 SG_ Signal_BMS02_Battery_Current : 8|8@1+ (4,-500) [-500|500] "A" Vector__XXX
 SG_ Signal_BMS02_Battery_Voltage : 0|8@1+ (3.4,0) [0|850] "V" Vector__XXX

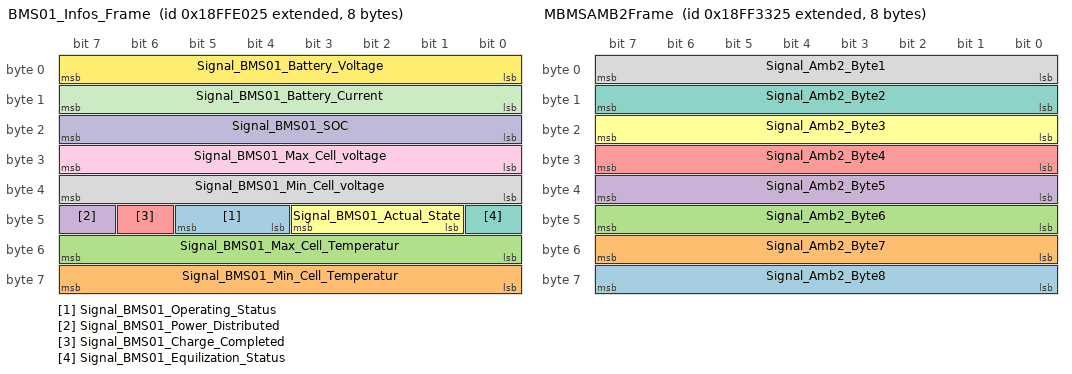
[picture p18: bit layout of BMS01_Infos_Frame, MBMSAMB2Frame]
BO_ 2566905893 BMS01_Infos_Frame: 8 MBMS
 SG_ Signal_BMS01_Operating_Status : 44|2@1+ (1,0) [0|0] "" Vector__XXX
 SG_ Signal_BMS01_Min_Cell_Temperatur : 56|8@1+ (1,-40) [-40|210] "°C" Vector__XXX
 SG_ Signal_BMS01_Max_Cell_Temperatur : 48|8@1+ (1,-40) [-40|210] "°C" Vector__XXX
 SG_ Signal_BMS01_Power_Distributed : 47|1@1+ (1,0) [0|1] "" Vector__XXX
 SG_ Signal_BMS01_Charge_Completed : 46|1@1+ (1,0) [0|1] "" Vector__XXX
 SG_ Signal_BMS01_Actual_State : 41|3@1+ (1,0) [0|0] "" Vector__XXX
 SG_ Signal_BMS01_Equilization_Status : 40|1@1+ (1,0) [0|1] "" Vector__XXX
 SG_ Signal_BMS01_Min_Cell_voltage : 32|8@1+ (20,0) [0|5000] "mV" Vector__XXX
 SG_ Signal_BMS01_Max_Cell_voltage : 24|8@1+ (20,0) [0|5000] "mV" Vector__XXX
 SG_ Signal_BMS01_SOC : 16|8@1+ (0.4,0) [0|100] "%" Vector__XXX
 SG_ Signal_BMS01_Battery_Current : 8|8@1+ (4,-500) [-500|500] "A" Vector__XXX
 SG_ Signal_BMS01_Battery_Voltage : 0|8@1+ (3.4,0) [0|850] "V" Vector__XXX

BO_ 2566861605 MBMSAMB2Frame: 8 MBMS
 SG_ Signal_Amb2_Byte8 : 56|8@1+ (1,0) [0|0] "" Vector__XXX
 SG_ Signal_Amb2_Byte7 : 48|8@1+ (1,0) [0|0] "" Vector__XXX
 SG_ Signal_Amb2_Byte6 : 40|8@1+ (1,0) [0|0] "" Vector__XXX
 SG_ Signal_Amb2_Byte5 : 32|8@1+ (1,0) [0|0] "" Vector__XXX
 SG_ Signal_Amb2_Byte4 : 24|8@1+ (1,0) [0|0] "" Vector__XXX
 SG_ Signal_Amb2_Byte3 : 16|8@1+ (1,0) [0|0] "" Vector__XXX
 SG_ Signal_Amb2_Byte2 : 8|8@1+ (1,0) [0|0] "" Vector__XXX
 SG_ Signal_Amb2_Byte1 : 0|8@1+ (1,0) [0|0] "" Vector__XXX

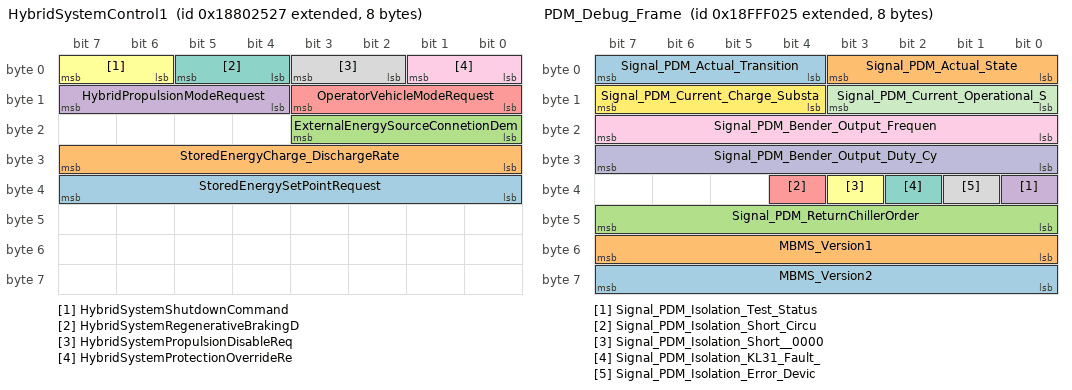
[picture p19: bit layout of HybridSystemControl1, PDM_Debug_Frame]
BO_ 2558534951 HybridSystemControl1: 8 Vector__XXX
 SG_ StoredEnergySetPointRequest : 32|8@1+ (0.4,0) [0|100] "%"  MBMS
 SG_ StoredEnergyCharge_DischargeRate : 24|8@1+ (0.4,0) [0|100] "%"  MBMS
 SG_ ExternalEnergySourceConnetionDem : 16|4@1+ (1,0) [0|0] ""  MBMS
 SG_ HybridPropulsionModeRequest : 12|4@1+ (1,0) [0|0] ""  MBMS
 SG_ OperatorVehicleModeRequest : 8|4@1+ (1,0) [0|0] ""  MBMS
 SG_ HybridSystemShutdownCommand : 6|2@1+ (1,0) [0|0] ""  MBMS
 SG_ HybridSystemRegenerativeBrakingD : 4|2@1+ (1,0) [0|0] ""  MBMS
 SG_ HybridSystemPropulsionDisableReq : 2|2@1+ (1,0) [0|0] ""  MBMS
 SG_ HybridSystemProtectionOverrideRe : 0|2@1+ (1,0) [0|0] ""  MBMS

BO_ 2566909989 PDM_Debug_Frame: 8 MBMS
 SG_ MBMS_Version2 : 56|8@1+ (1,0) [0|65535] "" Vector__XXX
 SG_ MBMS_Version1 : 48|8@1+ (1,0) [0|65535] "" Vector__XXX
 SG_ Signal_PDM_ReturnChillerOrder : 40|8@1+ (1,0) [0|0] "" Vector__XXX
 SG_ Signal_PDM_Isolation_Test_Status : 32|1@1+ (1,0) [0|1] "" Vector__XXX
 SG_ Signal_PDM_Isolation_Short_Circu : 36|1@1+ (1,0) [0|1] "" Vector__XXX
 SG_ Signal_PDM_Isolation_Short__0000 : 35|1@1+ (1,0) [0|1] "" Vector__XXX
 SG_ Signal_PDM_Isolation_KL31_Fault_ : 34|1@1+ (1,0) [0|1] "" Vector__XXX
 SG_ Signal_PDM_Isolation_Error_Devic : 33|1@1+ (1,0) [0|1] "" Vector__XXX
 SG_ Signal_PDM_Bender_Output_Frequen : 16|8@1+ (1,0) [0|0] "" Vector__XXX
 SG_ Signal_PDM_Bender_Output_Duty_Cy : 24|8@1+ (1,0) [0|0] "" Vector__XXX
 SG_ Signal_PDM_Current_Operational_S : 8|4@1+ (1,0) [0|0] "" Vector__XXX
 SG_ Signal_PDM_Current_Charge_Substa : 12|4@1+ (1,0) [0|0] "" Vector__XXX
 SG_ Signal_PDM_Actual_Transition : 4|4@1+ (1,0) [0|0] "" Vector__XXX
 SG_ Signal_PDM_Actual_State : 0|4@1+ (1,0) [0|0] "" Vector__XXX

CM_ BO_ 3221225472 "This is a message for not used signals, created by Vector CANdb++ DBC OLE DB Provider.";
CM_ SG_ 3221225472 VehicleRoll "This parameter indicates the roll in degrees from level.  Facing the direction of travel a tip to the left would be indicated by a negative number and a tip to the right would be indicated by a positive number.";
CM_ SG_ 3221225472 ExtlAccelerationDemand "Parameter provided to the brake system from external sources. This is the acceleration which the brake system is expected to realize. It is specified as an absolute acceleration in reference to the road.  Positive values lead to increasing vehicle ...";
CM_ SG_ 3221225472 ParameterGroupNumber "Whenever it is necessary to identify a Parameter Group in the data field of a CAN data frame, it will be expressed in 24 bits.  The Parameter Group Number is a 24 bit value that has the following constituent components:  Reserved bit, Data Page bit, ...PGN which is requested by the Request message";
CM_ SG_ 3221225472 GroupFunctionValue "Group Function of PGN being acknowledged. This field identifies for a device the specific group function of a PGN being acknowledged or declined.  This field is not used if the PGN being acknowledged or declined is not a group function PGN.";
CM_ SG_ 3221225472 ControlByte "Indicates the acknowledgement response.
0 - Positive Acknowledgment (ACK)
1 - Negative Acknowledgment (NACK)
2 - Access Denied (PGN supported but access denied)
3 - Cannot Respond (PGN supported but ECU cannot respond now) cannot respond with ...";
CM_ SG_ 3221225472 YawRate_ISig_3 "65024 - 65279 Error ; 65280 - 65535 Not available";
CM_ SG_ 3221225472 LateralAcceleration_ISig_3 "65024 - 65279 Error ; 65280 - 65535 Not available";
CM_ SG_ 3221225472 SteeringWheelTurnCounter_ISig_3 "62 Error; 63 Not available";
CM_ SG_ 3221225472 SteeringWheelAngle_ISig_3 "65024 - 65279 Error ; 65280 - 65535 Not available";
CM_ SG_ 3221225472 MessageChecksum "The message checksum is used to verify the signal path from the demanding device to the steering controller.  The support of this parameter is mandatory if PGN 61469 is supported as there is no means to indicate “not available”.
The 4 bit checksum ...";
CM_ SG_ 3221225472 MessageCounter "The message counter is to verify the signal path from the demanding device to the steering controller.  The support of this parameter is mandatory.
Note:  The initial value of the 4 bit message counter for the first message during a driving cycle ...";
CM_ SG_ 3221225472 SteerAngleSensorCalibrated "This signal indicates the calibration status of the steering angle sensor.

00 – SAS not calibrated
01 – SAS calibrated
10 – Reserved
11 – Not available";
CM_ SG_ 3221225472 SteerAngleSensorActiveMode "This signal indicates the operational mode of the steering angle sensor.

00 – Programming mode active
01 – Normal mode active
10 – Reserved
11 – Not available";
CM_ SG_ 3221225472 SteerWheelAngleRange "The signal indicates the range of  the steering wheel angle the sensor element is capable to measure. The steering wheel angle signal ranges between the negative and the positive value of the steering wheel angle range.
For example, a steering ...";
CM_ SG_ 3221225472 SteerWheelAngleRangeCounterType "The signal indicates whether the steering wheel angle sensor is capable of absolute measuring of the number of steering wheel angle ranges or not.  Absolute measuring means that the steering wheel angle range counter signal indicates the real ...";
CM_ SG_ 3221225472 SteerWheelAngleRangeCounter "The signal indicates the number of steering wheel angle range overflows if the operating range of steering wheel is greater than the measuring range of sensor element. Positive values indicate left turns (counterclockwise). If the steering wheel ...";
CM_ SG_ 3221225472 SteerWheelAngle "The main operator`s steering wheel angle (on the steering column, not the actual wheel angle). The vehicle being steered to the left (counterclockwise) results in a positive steering wheel angle.  This is the yaw angle of the steering wheel with the ...";
CM_ SG_ 3221225472 TachographVehicleSpeed "Speed of the vehicle registered by the tachograph.";
CM_ SG_ 3221225472 TachographOutputShaftSpeed "Calculated speed of the transmission output shaft.";
CM_ SG_ 3221225472 DirectionIndicator "Indicates the direction of the vehicle.

00 - Forward
01 - Reverse
10 - Error
11 - Not available";
CM_ SG_ 3221225472 TachographPerformance "Indicates the tachograph performance; including electronic or mechanical analysis, instrument analysis, speed sensor analysis, mass storage analysis, and printer analysis.
00 - Normal performance
01 - Performance analysis
10 - Error
11 - Not ...";
CM_ SG_ 3221225472 HandlingInformation "Indicates that handling information is present.  Information could include “no printer paper”, “no driver card”, etc.

00 - No handling information
01 - Handling information
10 - Error
11 - Not available";
CM_ SG_ 3221225472 SystemEvent "Indicates that a tachograph event has occurred.  This may include power supply interruption, interruption of the speed sensor, incorrect data on the driver card, driving without a driver card, illegal removal of a driver card, insertion of a driver ...";
CM_ SG_ 3221225472 DriverCardDriver2 "Indicates the presence of a driver card

00 - Driver card not present
01 - Driver card present
10 - Error
11 - Not available";
CM_ SG_ 3221225472 Driver2TimeRelatedStates "Indicates if the driver approaches or exceeds working time limits (or other limits).
0000 Normal/No limits reached
0001 Limit #1 – 15 min before 4 ½ h
0010 Limit #2 – 4 ½ h reached
0011 Limit #3 – 15 min before 9 h
0100 Limit #4 – 9 h reached";
CM_ SG_ 3221225472 VehicleOverspeed "Indicates whether the vehicle is exceeding the legal speed limit set in the tachograph.

00 No overspeed
01 Overspeed
10 Error
11 Not available";
CM_ SG_ 3221225472 DriverCardDriver1 "Indicates the presence of a driver card

00 - Driver card not present
01 - Driver card present
10 - Error
11 - Not available";
CM_ SG_ 3221225472 Driver1TimeRelatedStates "Indicates if the driver approaches or exceeds working time limits (or other limits).
0000 Normal/No limits reached
0001 Limit #1 – 15 min before 4 ½ h
0010 Limit #2 – 4 ½ h reached
0011 Limit #3 – 15 min before 9 h
0100 Limit #4 – 9 h reached";
CM_ SG_ 3221225472 Driver1WorkingState "State of work of the driver.  

000 Rest - sleeping
001 Driver available – short break
010 Work – loading, unloading, working in an office
011 Drive – behind wheel 
100-101 Reserved
110 Error
111 Not available";
CM_ SG_ 3221225472 VehicleMotion "Indicates whether motion of the vehicle is detected or not.

00 Vehicle motion not detected
01 Vehicle motion detected
10 - Error
11 - Not available";
CM_ SG_ 3221225472 Driver2WorkingState "State of work of the driver.  

000 Rest - sleeping
001 Driver available – short break
010 Work – loading, unloading, working in an office
011 Drive – behind wheel 
100-101 Reserved
110 Error
111 Not available";
CM_ SG_ 3221225472 RelativeSpeedRearAxle2RightWhel "The speed of the rear axle #2, right wheel relative to the front axle speed, SPN 904.";
CM_ SG_ 3221225472 RelativeSpeedRearAxle2LeftWhel "The speed of the rear axle #2, left wheel relative to the front axle speed, SPN 904.";
CM_ SG_ 3221225472 RelativeSpeedRearAxle1LeftWhel "The speed of the rear axle #1, left wheel relative to the front axle speed, SPN 904.";
CM_ SG_ 3221225472 RelativeSpeedRearAxle1RightWhel "The speed of the rear axle #1, right wheel relative to the front axle speed, SPN 904.";
CM_ SG_ 3221225472 RelativeSpeedFrontAxleRightWheel "The speed of the front axle, right wheel relative to the front axle speed, SPN 904.";
CM_ SG_ 3221225472 RelativeSpeedFrontAxleLeftWheel "The speed of the front axle, left wheel relative to the front axle speed, SPN 904.";
CM_ SG_ 3221225472 FrontAxleSpeed "The average speed of the two front wheels.";
CM_ SG_ 3221225472 MotorTorque "Used by EPSO2::MotorTorque";
CM_ SG_ 3221225472 ExtControlMode "Used by EPSO2::ExtControlMode";
CM_ SG_ 3221225472 DriverTorque "Used by EPSO2::DriverTorque";
CM_ SG_ 3221225472 SysState "Used by EPSO1::SysState";
CM_ SG_ 3221225472 SteeringAngleSpeed "Used by EPSO1::SterringAngleSpeed";
CM_ SG_ 3221225472 SteeringAngle "Uesd by EPSO1::SteeringAngle";
CM_ SG_ 3221225472 EngDemandPercentTorque "The requested torque output of the engine by all dynamic internal inputs, including smoke control, noise control and low and high speed governing.";
CM_ SG_ 3221225472 SrcAddrssOfCntrllngDvcForEngCtrl "The source address of the SAE J1939 device currently controlling the engine.  It is used to expand the torque mode parameter (see SPN 899) in cases where control is in response to an ECU that is not listed in Table SPN899_A.  Its value may be the ...";
CM_ SG_ 3221225472 ActlEngPrcntTorqueHighResolution "This parameter displays an additional torque in percent of the reference engine torque.
When the MSB is set to 1, this parameter is not available.  When the MSB is set to 0, bits 1 to 3 indicate the desired torque with resolution of 0.125%/bit  ...";
CM_ SG_ 3221225472 EngStarterMode "There are several phases in a starting action and different reasons why a start cannot take place.
0000 start not requested
0001 starter active, gear not engaged
0010 starter active, gear engaged
0011 start finished; starter not active after ...";
CM_ SG_ 3221225472 EngSpeed "Actual engine speed which is calculated over a minimum crankshaft angle of 720 degrees divided by the number of cylinders.";
CM_ SG_ 3221225472 ActualEngPercentTorque "The calculated output torque of the engine.  The data is transmitted in indicated torque as a percent of reference engine torque (see the engine configuration message, PGN 65251).  The engine percent torque value will not be less than zero and it ...";
CM_ SG_ 3221225472 DriversDemandEngPercentTorque "The requested torque output of the engine by the driver. It is based on input from the following requestors external to the powertrain: operator (via the accelerator pedal), cruise control and/or road speed limit governor. Dynamic commands from ...";
CM_ SG_ 3221225472 EngTorqueMode "State signal which indicates which engine torque mode is currently generating, limiting, or controlling the torque.  Note that the modes are not in prioritized order. Not all modes may be relevant for a given device.  Some devices may not implement ...";
CM_ SG_ 3221225472 Ph_H "Hight Byte consumed Power";
CM_ SG_ 3221225472 Ph_HM "Hight Middle Byte consumed Power";
CM_ SG_ 3221225472 Ph_LM "Little Middle Byte consumed Power";
CM_ SG_ 3221225472 Ph_L "Little Byte consumed Power";
CM_ SG_ 3221225472 Ih_H "Hight Byte consumed Curren";
CM_ SG_ 3221225472 Ih_HM "Hight Middle Byte consumed Current";
CM_ SG_ 3221225472 ACDC_Temperature "Temperature";
CM_ SG_ 3221225472 DTC5 "Diagnostic Trouble Code";
CM_ SG_ 3221225472 DTC4 "Diagnostic Trouble Code";
CM_ SG_ 3221225472 DTC3 "Diagnostic Trouble Code";
CM_ SG_ 3221225472 DTC2 "Diagnostic Trouble Code";
CM_ SG_ 3221225472 DTC1 "Diagnostic Trouble Code";
CM_ SG_ 3221225472 AnswerMode2 "Answer Mode 2";
CM_ SG_ 3221225472 IBS_looses_recalibration_SOC "IBS looses recalibration of SOC due to no possible OCV measurement

0x0 - Not active
0x1 - Active
0x2 - Error
0x3 - Not Available
";
CM_ SG_ 3221225472 NumberOfMembersInWorkingSet "The number of members in a particular Working Set.";
CM_ SG_ 3221225472 SourceAddress "Instance of a Source Address listed a Network Message data field.";
CM_ SG_ 3221225472 NncntnuslyMonitoredSystemsStatus "Identifies the non-continuously monitored systems status. Each bit identifies whether a particular test is complete for a given controller.
";
CM_ SG_ 3221225472 NncntnslyMonitoredSystemsSupport "Identifies the non-continuously monitored systems support.
";
CM_ SG_ 3221225472 CntnslyMntrdSystmsSupport_Status "Identifies the continuously monitored system support and status.
";
CM_ SG_ 3221225472 AETCTorqueValue "Engine torque value of the data points in PGN 64912 – Advertised Engine Torque Curve (AETC).";
CM_ SG_ 3221225472 TrailerWeight "Total mass of freight-carrying vehicle designed to be pulled by truck, including the weight of the contents.";
CM_ SG_ 3221225472 ReferenceTirePressSetting "Reference value of the tire pressure setting as basis for the tire pressure monitoring ...";
CM_ SG_ 3221225472 ReferenceTirePress "Reference value of the tire pressure as basis for the tire pressure monitoring ...";
CM_ SG_ 3221225472 TirePressThresholdDetection "Signal indicating the pressure level of the tire.  The levels defined represent different pressure conditions of the tire: 000 Extreme over pressure - The tire pressure is at a level where the safety of the vehicle may be jeopardised.";
CM_ SG_ 3221225472 TireAirLeakageRate "The pressure loss rate of a tire.";
CM_ SG_ 3221225472 CTIWheelEndElectricalFault "Indicates the status of electrical fault on CTI wheel interface.";
CM_ SG_ 3221225472 CTITireStatus "Indicates the status of the tire.";
CM_ SG_ 3221225472 CTIWheelSensorStatus "Indicates whether the wheel is being monitored by the CTI controller.";
CM_ SG_ 3221225472 TireTemp "Temperature at the surface of the tire sidewall.";
CM_ SG_ 3221225472 TirePress "Pressure at which air is contained in cavity formed by tire and rim.";
CM_ SG_ 3221225472 EngTurningGearEngaged "Status signal which indicates that the turning gear is engaged.  The turning gear is used to turn the flywheel/crankshaft, ...";
CM_ SG_ 3221225472 AETCSpeedValue "Engine speed value of the data points in PGN 64912 – Advertised Engine Torque Curve (AETC).";
CM_ BO_ 2566834712 "Active Diagnostic Trouble Codes";
CM_ SG_ 2566834712 FlashRedStopLamp "This parameter provides the capability to flash the RSL


00 - Slow Flash (1 Hz, 50 % duty cycle)
01 - Fast Flash (2 Hz or faster, 50% duty cycle)
10 - Reserved
11 - Unavailable / Do Not Flash";
CM_ SG_ 2566834712 FlashProtectLamp "This parameter provides the capability to flash the engine protect lamp


00 - Slow Flash (1 Hz, 50 % duty cycle)
01 - Fast Flash (2 Hz or faster, 50% duty cycle)
10 - Reserved
11 - Unavailable / Do Not Flash";
CM_ SG_ 2566834712 FlashMalfuncIndicatorLamp "This parameter provides the capability to flash the MIL
00 - Slow Flash (1 Hz, 50 % duty cycle)
01 - Fast Flash (2 Hz or faster, 50% duty cycle)
10 - Class C DTC
11 - Unavailable / Do Not Flash
Note:  State 10 is for WWH OBD discriminatory ...";
CM_ SG_ 2566834712 MalfunctionIndicatorLampStatus "A lamp used to relay only emissions-related trouble code information. This lamp is only illuminated when there is an emission-related trouble code active.
00     Lamp Off
01     Lamp On
10     Short MIL for WWH OBD
11     Not available
Note ...";
CM_ SG_ 2566834712 AmberWarningLampStatus "This lamp is used to relay trouble code information that is reporting a problem with the vehicle system but the vehicle need not be immediately stopped. 

00     Lamp Off
01     Lamp On
10     Reserved
11     Not available";
CM_ BO_ 2566834809 "Active Diagnostic Trouble Codes";
CM_ SG_ 2566834809 FlashRedStopLamp "This parameter provides the capability to flash the RSL


00 - Slow Flash (1 Hz, 50 % duty cycle)
01 - Fast Flash (2 Hz or faster, 50% duty cycle)
10 - Reserved
11 - Unavailable / Do Not Flash";
CM_ SG_ 2566834809 FlashProtectLamp "This parameter provides the capability to flash the engine protect lamp


00 - Slow Flash (1 Hz, 50 % duty cycle)
01 - Fast Flash (2 Hz or faster, 50% duty cycle)
10 - Reserved
11 - Unavailable / Do Not Flash";
CM_ SG_ 2566834809 FlashMalfuncIndicatorLamp "This parameter provides the capability to flash the MIL
00 - Slow Flash (1 Hz, 50 % duty cycle)
01 - Fast Flash (2 Hz or faster, 50% duty cycle)
10 - Class C DTC
11 - Unavailable / Do Not Flash
Note:  State 10 is for WWH OBD discriminatory ...";
CM_ SG_ 2566834809 MalfunctionIndicatorLampStatus "A lamp used to relay only emissions-related trouble code information. This lamp is only illuminated when there is an emission-related trouble code active.
00     Lamp Off
01     Lamp On
10     Short MIL for WWH OBD
11     Not available
Note ...";
CM_ SG_ 2566834809 AmberWarningLampStatus "This lamp is used to relay trouble code information that is reporting a problem with the vehicle system but the vehicle need not be immediately stopped. 

00     Lamp Off
01     Lamp On
10     Reserved
11     Not available";
CM_ SG_ 2566890515 VCVCCU_ChargeUnit_MaxCurrent "Max current derived from CP duty cycle";
CM_ SG_ 2566890515 VCVCCU_ChargeUnit_Mode "Requested charging mode from the EVSE, derived from the CP duty cycle";
CM_ SG_ 2566841986 Seconds "The seconds component of the current time of day.  This should be reported as the seconds component of the current time at UTC (Universal Time Coordinate), a.k.a. GMT; however, it may be reported as the seconds component of the current time at a ...";
CM_ SG_ 2566841986 Year "The year component of the current calendar date.  This should be reported as the year component of the current date at UTC (Universal Time Coordinate), a.k.a. GMT; however, it may be reported as the year component of the current date at a local time ...";
CM_ SG_ 2566841986 Month "The month component of the current calendar date.  This should be reported as the month component of the current date at UTC (Universal Time Coordinate), a.k.a. GMT; however, it may be reported as the month component of the current date at a local ...";
CM_ SG_ 2566841986 Minutes "The minutes component of the current time of day.  This should be reported as the minutes component of the current time at UTC (Universal Time Coordinate), a.k.a. GMT; however, it may be reported as the minutes component of the current time at a ...";
CM_ SG_ 2566841986 LocalMinuteOffset "The minute component of the offset between the UTC time and date and a local time zone time and date.  This is the number of minutes to add to UTC (Universal Time Coordinate) time and date to convert to the time and date in the local time zone  ...";
CM_ SG_ 2566841986 LocalHourOffset "The hour component of the offset between the UTC (Universal Time Coordinate) time and date and a local time zone time and date.  This is the number of hours to add to UTC, a.k.a. GMT, time and date to convert to the time and date in the local time ...";
CM_ SG_ 2566841986 Hours "The hour component of the current time of day.  This should be reported as the hour component of the current time at UTC (Universal Time Coordinate), a.k.a. GMT; however, it may be reported as the hour component of the current time at a local time ...";
CM_ SG_ 2566841986 Day "The day component of the current calendar date.  This should be reported as the day component of the current date at UTC (Universal Time Coordinate), a.k.a. GMT; however, it may be reported as the day component of the current date at a local time ...";
CM_ SG_ 2363129986 DIAG_RESP_VCCU "Response message for UDS Diagnostic";
CM_ BO_ 2566834789 "Active Diagnostic Trouble Codes";
CM_ SG_ 2566834789 FlashRedStopLamp "This parameter provides the capability to flash the RSL


00 - Slow Flash (1 Hz, 50 % duty cycle)
01 - Fast Flash (2 Hz or faster, 50% duty cycle)
10 - Reserved
11 - Unavailable / Do Not Flash";
CM_ SG_ 2566834789 FlashProtectLamp "This parameter provides the capability to flash the engine protect lamp


00 - Slow Flash (1 Hz, 50 % duty cycle)
01 - Fast Flash (2 Hz or faster, 50% duty cycle)
10 - Reserved
11 - Unavailable / Do Not Flash";
CM_ SG_ 2566834789 FlashMalfuncIndicatorLamp "This parameter provides the capability to flash the MIL
00 - Slow Flash (1 Hz, 50 % duty cycle)
01 - Fast Flash (2 Hz or faster, 50% duty cycle)
10 - Class C DTC
11 - Unavailable / Do Not Flash
Note:  State 10 is for WWH OBD discriminatory ...";
CM_ SG_ 2566834789 MalfunctionIndicatorLampStatus "A lamp used to relay only emissions-related trouble code information. This lamp is only illuminated when there is an emission-related trouble code active.
00     Lamp Off
01     Lamp On
10     Short MIL for WWH OBD
11     Not available
Note ...";
CM_ SG_ 2566834789 AmberWarningLampStatus "This lamp is used to relay trouble code information that is reporting a problem with the vehicle system but the vehicle need not be immediately stopped. 

00     Lamp Off
01     Lamp On
10     Reserved
11     Not available";
CM_ BO_ 2566834790 "Active Diagnostic Trouble Codes";
CM_ SG_ 2566834790 FlashRedStopLamp "This parameter provides the capability to flash the RSL


00 - Slow Flash (1 Hz, 50 % duty cycle)
01 - Fast Flash (2 Hz or faster, 50% duty cycle)
10 - Reserved
11 - Unavailable / Do Not Flash";
CM_ SG_ 2566834790 FlashProtectLamp "This parameter provides the capability to flash the engine protect lamp


00 - Slow Flash (1 Hz, 50 % duty cycle)
01 - Fast Flash (2 Hz or faster, 50% duty cycle)
10 - Reserved
11 - Unavailable / Do Not Flash";
CM_ SG_ 2566834790 FlashMalfuncIndicatorLamp "This parameter provides the capability to flash the MIL
00 - Slow Flash (1 Hz, 50 % duty cycle)
01 - Fast Flash (2 Hz or faster, 50% duty cycle)
10 - Class C DTC
11 - Unavailable / Do Not Flash
Note:  State 10 is for WWH OBD discriminatory ...";
CM_ SG_ 2566834790 MalfunctionIndicatorLampStatus "A lamp used to relay only emissions-related trouble code information. This lamp is only illuminated when there is an emission-related trouble code active.
00     Lamp Off
01     Lamp On
10     Short MIL for WWH OBD
11     Not available
Note ...";
CM_ SG_ 2566834790 AmberWarningLampStatus "This lamp is used to relay trouble code information that is reporting a problem with the vehicle system but the vehicle need not be immediately stopped. 

00     Lamp Off
01     Lamp On
10     Reserved
11     Not available";
CM_ BO_ 2566851111 "Pantograph upgoinng or downgoing speed reqest";
CM_ BO_ 2566850840 "Actual parameters measured by the controller.";
BA_DEF_  "Manufacturer" STRING ;
BA_DEF_ SG_  "SPN" INT 0 524287;
BA_DEF_ BO_  "VFrameFormat" ENUM  "StandardCAN","ExtendedCAN","reserved","J1939PG";
BA_DEF_  "ProtocolType" STRING ;
BA_DEF_  "BusType" STRING ;
BA_DEF_  "DBName" STRING ;
BA_DEF_ BU_  "NmAsrCanMsgReducedTime" INT 0 65535;
BA_DEF_ BU_  "NmAsrNode" ENUM  "no","yes";
BA_DEF_ BU_  "NmAsrNodeIdentifier" INT 0 255;
BA_DEF_  "NmAsrBaseAddress" HEX 0 536870911;
BA_DEF_  "NmAsrCanMsgCycleTime" INT 0 65535;
BA_DEF_  "NmAsrMessageCount" INT 0 256;
BA_DEF_  "NmAsrRepeatMessageTime" INT 0 65535;
BA_DEF_  "NmAsrTimeoutTime" INT 0 65535;
BA_DEF_  "NmAsrWaitBusSleepTime" INT 0 65535;
BA_DEF_  "Baudrate" INT 0 10000000;
BA_DEF_ SG_  "SigType" ENUM  "Default","Range","RangeSigned","ASCII","Discrete","Control","ReferencePGN","DTC","StringDelimiter","StringLength","StringLengthControl","MessageCounter","MessageChecksum";
BA_DEF_ SG_  "GenSigEVName" STRING ;
BA_DEF_ SG_  "GenSigILSupport" ENUM  "No","Yes";
BA_DEF_ SG_  "GenSigSendType" ENUM  "Cyclic","OnWrite","OnWriteWithRepetition","OnChange","OnChangeWithRepetition","IfActive","IfActiveWithRepetition","NoSigSendType";
BA_DEF_ SG_  "GenSigStartValue" INT 0 10000;
BA_DEF_ BO_  "GenMsgILSupport" ENUM  "No","Yes";
BA_DEF_ BO_  "GenMsgStartDelayTime" INT 0 100000;
BA_DEF_ BU_  "NodeLayerModules" STRING ;
BA_DEF_ BU_  "NmStationAddress" INT 0 255;
BA_DEF_ BO_  "GenMsgSendType" ENUM  "cyclic","NotUsed","NotUsed","NotUsed","NotUsed","NotUsed","NotUsed","IfActive","noMsgSendType";
BA_DEF_ BO_  "GenMsgRequestable" INT 0 1;
BA_DEF_ BO_  "GenMsgCycleTime" INT 0 3600000;
BA_DEF_ SG_  "SystemSignalLongSymbol" STRING ;
BA_DEF_DEF_  "Manufacturer" "Vector";
BA_DEF_DEF_  "SPN" 0;
BA_DEF_DEF_  "VFrameFormat" "J1939PG";
BA_DEF_DEF_  "ProtocolType" "J1939";
BA_DEF_DEF_  "BusType" "CAN";
BA_DEF_DEF_  "DBName" "";
BA_DEF_DEF_  "NmAsrCanMsgReducedTime" 50;
BA_DEF_DEF_  "NmAsrNode" "yes";
BA_DEF_DEF_  "NmAsrNodeIdentifier" 0;
BA_DEF_DEF_  "NmAsrBaseAddress" 486506496;
BA_DEF_DEF_  "NmAsrCanMsgCycleTime" 100;
BA_DEF_DEF_  "NmAsrMessageCount" 64;
BA_DEF_DEF_  "NmAsrRepeatMessageTime" 400;
BA_DEF_DEF_  "NmAsrTimeoutTime" 1000;
BA_DEF_DEF_  "NmAsrWaitBusSleepTime" 750;
BA_DEF_DEF_  "Baudrate" 500000;
BA_DEF_DEF_  "SigType" "Default";
BA_DEF_DEF_  "GenSigEVName" "Env@Nodename_@Signame";
BA_DEF_DEF_  "GenSigILSupport" "Yes";
BA_DEF_DEF_  "GenSigSendType" "NoSigSendType";
BA_DEF_DEF_  "GenSigStartValue" 0;
BA_DEF_DEF_  "GenMsgILSupport" "Yes";
BA_DEF_DEF_  "GenMsgStartDelayTime" 0;
BA_DEF_DEF_  "NodeLayerModules" "";
BA_DEF_DEF_  "NmStationAddress" 56;
BA_DEF_DEF_  "GenMsgSendType" "noMsgSendType";
BA_DEF_DEF_  "GenMsgRequestable" 1;
BA_DEF_DEF_  "GenMsgCycleTime" 0;
BA_DEF_DEF_  "SystemSignalLongSymbol" "";
BA_ "DBName" "HV1CAN";
BA_ "NmStationAddress" BU_ PC 238;
BA_ "NmStationAddress" BU_ PUMPOT 24;
BA_ "NmStationAddress" BU_ DC_DC2 102;
BA_ "NmStationAddress" BU_ DC_DC1 101;
BA_ "NmStationAddress" BU_ MBMS 37;
BA_ "NmStationAddress" BU_ VCU 39;
BA_ "NodeLayerModules" BU_ VCVCCU "J1939_IL.dll, ASRNM33.dll";
BA_ "NmAsrNodeIdentifier" BU_ VCVCCU 128;
BA_ "NmStationAddress" BU_ VCVCCU 128;
BA_ "NmStationAddress" BU_ TMS 254;
BA_ "GenMsgCycleTime" BO_ 2566834712 1000;
BA_ "GenMsgSendType" BO_ 2566834712 0;
BA_ "VFrameFormat" BO_ 2566834712 1;
BA_ "GenMsgSendType" BO_ 2566834809 0;
BA_ "GenMsgCycleTime" BO_ 2566834809 1000;
BA_ "VFrameFormat" BO_ 2566834809 1;
BA_ "VFrameFormat" BO_ 2566891047 1;
BA_ "VFrameFormat" BO_ 2566890791 1;
BA_ "VFrameFormat" BO_ 2566890515 1;
BA_ "VFrameFormat" BO_ 2566840450 1;
BA_ "VFrameFormat" BO_ 2566857346 1;
BA_ "VFrameFormat" BO_ 2566841986 1;
BA_ "VFrameFormat" BO_ 2564784258 1;
BA_ "VFrameFormat" BO_ 2363129986 1;
BA_ "VFrameFormat" BO_ 2147485202 1;
BA_ "VFrameFormat" BO_ 2147485200 1;
BA_ "VFrameFormat" BO_ 2566872615 1;
BA_ "VFrameFormat" BO_ 2566872871 1;
BA_ "VFrameFormat" BO_ 2566913665 1;
BA_ "VFrameFormat" BO_ 2566913664 1;
BA_ "GenMsgSendType" BO_ 2566834789 0;
BA_ "GenMsgCycleTime" BO_ 2566834789 1000;
BA_ "VFrameFormat" BO_ 2566834789 1;
BA_ "GenMsgSendType" BO_ 2566834790 0;
BA_ "GenMsgCycleTime" BO_ 2566834790 1000;
BA_ "VFrameFormat" BO_ 2566834790 1;
BA_ "VFrameFormat" BO_ 2566871096 1;
BA_ "VFrameFormat" BO_ 2566871591 1;
BA_ "VFrameFormat" BO_ 2566871079 1;
BA_ "VFrameFormat" BO_ 2365537063 1;
BA_ "VFrameFormat" BO_ 2566874489 1;
BA_ "VFrameFormat" BO_ 2349006590 1;
BA_ "VFrameFormat" BO_ 2566851111 1;
BA_ "GenMsgCycleTime" BO_ 2566850840 10;
BA_ "VFrameFormat" BO_ 2566850840 1;
BA_ "VFrameFormat" BO_ 2566858881 1;
BA_ "VFrameFormat" BO_ 2566870567 1;
BA_ "VFrameFormat" BO_ 2566834725 1;
BA_ "VFrameFormat" BO_ 2566890277 1;
BA_ "VFrameFormat" BO_ 2566890021 1;
BA_ "VFrameFormat" BO_ 2566889765 1;
BA_ "VFrameFormat" BO_ 2566889509 1;
BA_ "VFrameFormat" BO_ 2566909733 1;
BA_ "VFrameFormat" BO_ 2566909477 1;
BA_ "VFrameFormat" BO_ 2566909221 1;
BA_ "VFrameFormat" BO_ 2566894629 1;
BA_ "VFrameFormat" BO_ 2566894373 1;
BA_ "VFrameFormat" BO_ 2566894117 1;
BA_ "VFrameFormat" BO_ 2566893861 1;
BA_ "VFrameFormat" BO_ 2566893605 1;
BA_ "VFrameFormat" BO_ 2566864933 1;
BA_ "VFrameFormat" BO_ 2566902565 1;
BA_ "VFrameFormat" BO_ 2566902309 1;
BA_ "VFrameFormat" BO_ 2566902053 1;
BA_ "VFrameFormat" BO_ 2566901797 1;
BA_ "VFrameFormat" BO_ 2566862373 1;
BA_ "VFrameFormat" BO_ 2566862117 1;
BA_ "VFrameFormat" BO_ 2566861861 1;
BA_ "VFrameFormat" BO_ 2566908965 1;
BA_ "VFrameFormat" BO_ 2566908709 1;
BA_ "VFrameFormat" BO_ 2566908453 1;
BA_ "VFrameFormat" BO_ 2566908197 1;
BA_ "VFrameFormat" BO_ 2566907941 1;
BA_ "VFrameFormat" BO_ 2566907685 1;
BA_ "VFrameFormat" BO_ 2566907429 1;
BA_ "VFrameFormat" BO_ 2566907173 1;
BA_ "VFrameFormat" BO_ 2566906917 1;
BA_ "VFrameFormat" BO_ 2566906661 1;
BA_ "VFrameFormat" BO_ 2566906405 1;
BA_ "VFrameFormat" BO_ 2566906149 1;
BA_ "VFrameFormat" BO_ 2566905893 1;
BA_ "VFrameFormat" BO_ 2566861605 1;
BA_ "VFrameFormat" BO_ 2558534951 1;
BA_ "VFrameFormat" BO_ 2566909989 1;
BA_ "GenSigStartValue" SG_ 3221225472 VCVCCU_Vehicle_ChargeSelection 3;
BA_ "GenSigStartValue" SG_ 3221225472 Month 1;
BA_ "GenSigStartValue" SG_ 3221225472 LocalMinuteOffset 66;
BA_ "GenSigStartValue" SG_ 3221225472 LocalHourOffset 102;
BA_ "GenSigStartValue" SG_ 3221225472 Day 1;
BA_ "SystemSignalLongSymbol" SG_ 3221225472 BTMDemandPowerHighLowBytes_Copy_ "BTMDemandPowerHighLowBytes_Copy_1";
BA_ "SystemSignalLongSymbol" SG_ 3221225472 HybridSystemRegenerativeBrakingI "HybridSystemRegenerativeBrakingIndicator";
BA_ "SystemSignalLongSymbol" SG_ 3221225472 HybridSystemMotorOverspeedIndica "HybridSystemMotorOverspeedIndicator";
BA_ "SystemSignalLongSymbol" SG_ 3221225472 HybridSystemInitialisationIndica "HybridSystemInitialisationIndicator";
BA_ "SystemSignalLongSymbol" SG_ 3221225472 HybridSystemHighVoltageExposureI "HybridSystemHighVoltageExposureIndicator";
BA_ "SystemSignalLongSymbol" SG_ 3221225472 HybridSystemElectricAlternatorIn "HybridSystemElectricAlternatorIndicator";
BA_ "SystemSignalLongSymbol" SG_ 3221225472 HybridPropulsionModeTransitionSt "HybridPropulsionModeTransitionStatus";
BA_ "SystemSignalLongSymbol" SG_ 3221225472 ExternalEnergySourceConnectionSt "ExternalEnergySourceConnectionStatus";
BA_ "SigType" SG_ 2566834712 first_byte_SPN 7;
BA_ "SigType" SG_ 2566834712 FlashRedStopLamp 5;
BA_ "SPN" SG_ 2566834712 FlashRedStopLamp 3039;
BA_ "SigType" SG_ 2566834712 FlashProtectLamp 5;
BA_ "SPN" SG_ 2566834712 FlashProtectLamp 3041;
BA_ "SigType" SG_ 2566834712 FlashMalfuncIndicatorLamp 5;
BA_ "SPN" SG_ 2566834712 FlashMalfuncIndicatorLamp 3038;
BA_ "SigType" SG_ 2566834712 FlashAmberWarningLamp 5;
BA_ "SPN" SG_ 2566834712 FlashAmberWarningLamp 3040;
BA_ "SigType" SG_ 2566834712 MalfunctionIndicatorLampStatus 5;
BA_ "SPN" SG_ 2566834712 MalfunctionIndicatorLampStatus 1213;
BA_ "SigType" SG_ 2566834712 AmberWarningLampStatus 5;
BA_ "SPN" SG_ 2566834712 AmberWarningLampStatus 624;
BA_ "SigType" SG_ 2566834712 RedStopLampState 4;
BA_ "SPN" SG_ 2566834712 RedStopLampState 623;
BA_ "SigType" SG_ 2566834712 ProtectLampStatus 5;
BA_ "SPN" SG_ 2566834712 ProtectLampStatus 987;
BA_ "SigType" SG_ 2566834809 first_byte_SPN 7;
BA_ "SigType" SG_ 2566834809 FlashRedStopLamp 5;
BA_ "SPN" SG_ 2566834809 FlashRedStopLamp 3039;
BA_ "SigType" SG_ 2566834809 FlashProtectLamp 5;
BA_ "SPN" SG_ 2566834809 FlashProtectLamp 3041;
BA_ "SigType" SG_ 2566834809 FlashMalfuncIndicatorLamp 5;
BA_ "SPN" SG_ 2566834809 FlashMalfuncIndicatorLamp 3038;
BA_ "SigType" SG_ 2566834809 FlashAmberWarningLamp 5;
BA_ "SPN" SG_ 2566834809 FlashAmberWarningLamp 3040;
BA_ "SigType" SG_ 2566834809 MalfunctionIndicatorLampStatus 5;
BA_ "SPN" SG_ 2566834809 MalfunctionIndicatorLampStatus 1213;
BA_ "SigType" SG_ 2566834809 AmberWarningLampStatus 5;
BA_ "SPN" SG_ 2566834809 AmberWarningLampStatus 624;
BA_ "SigType" SG_ 2566834809 RedStopLampState 4;
BA_ "SPN" SG_ 2566834809 RedStopLampState 623;
BA_ "SigType" SG_ 2566834809 ProtectLampStatus 5;
BA_ "SPN" SG_ 2566834809 ProtectLampStatus 987;
BA_ "GenSigStartValue" SG_ 2566890515 VCVCCU_ChargeUnit_MaxCurrent 255;
BA_ "GenSigStartValue" SG_ 2566890515 VCVCCU_ChargeUnit_Mode 7;
BA_ "GenSigStartValue" SG_ 2566857346 VCVCCU_V2ICP_RequDurationToBatt 255;
BA_ "GenSigStartValue" SG_ 2566857346 VCVCCU_VICP_ReqToPrecondVeh 255;
BA_ "SigType" SG_ 2566834789 first_byte_SPN 7;
BA_ "SigType" SG_ 2566834789 FlashRedStopLamp 5;
BA_ "SPN" SG_ 2566834789 FlashRedStopLamp 3039;
BA_ "SigType" SG_ 2566834789 FlashProtectLamp 5;
BA_ "SPN" SG_ 2566834789 FlashProtectLamp 3041;
BA_ "SigType" SG_ 2566834789 FlashMalfuncIndicatorLamp 5;
BA_ "SPN" SG_ 2566834789 FlashMalfuncIndicatorLamp 3038;
BA_ "SigType" SG_ 2566834789 FlashAmberWarningLamp 5;
BA_ "SPN" SG_ 2566834789 FlashAmberWarningLamp 3040;
BA_ "SigType" SG_ 2566834789 MalfunctionIndicatorLampStatus 5;
BA_ "SPN" SG_ 2566834789 MalfunctionIndicatorLampStatus 1213;
BA_ "SigType" SG_ 2566834789 AmberWarningLampStatus 5;
BA_ "SPN" SG_ 2566834789 AmberWarningLampStatus 624;
BA_ "SigType" SG_ 2566834789 RedStopLampState 4;
BA_ "SPN" SG_ 2566834789 RedStopLampState 623;
BA_ "SigType" SG_ 2566834789 ProtectLampStatus 5;
BA_ "SPN" SG_ 2566834789 ProtectLampStatus 987;
BA_ "SigType" SG_ 2566834790 first_byte_SPN 7;
BA_ "SigType" SG_ 2566834790 FlashRedStopLamp 5;
BA_ "SPN" SG_ 2566834790 FlashRedStopLamp 3039;
BA_ "SigType" SG_ 2566834790 FlashProtectLamp 5;
BA_ "SPN" SG_ 2566834790 FlashProtectLamp 3041;
BA_ "SigType" SG_ 2566834790 FlashMalfuncIndicatorLamp 5;
BA_ "SPN" SG_ 2566834790 FlashMalfuncIndicatorLamp 3038;
BA_ "SigType" SG_ 2566834790 FlashAmberWarningLamp 5;
BA_ "SPN" SG_ 2566834790 FlashAmberWarningLamp 3040;
BA_ "SigType" SG_ 2566834790 MalfunctionIndicatorLampStatus 5;
BA_ "SPN" SG_ 2566834790 MalfunctionIndicatorLampStatus 1213;
BA_ "SigType" SG_ 2566834790 AmberWarningLampStatus 5;
BA_ "SPN" SG_ 2566834790 AmberWarningLampStatus 624;
BA_ "SigType" SG_ 2566834790 RedStopLampState 4;
BA_ "SPN" SG_ 2566834790 RedStopLampState 623;
BA_ "SigType" SG_ 2566834790 ProtectLampStatus 5;
BA_ "SPN" SG_ 2566834790 ProtectLampStatus 987;
BA_ "GenSigStartValue" SG_ 2566851111 RequestSpeed 127;
BA_ "SPN" SG_ 2566851111 RequestSpeed 18003;
BA_ "SPN" SG_ 2566850840 InputVoltage 18002;
BA_ "SPN" SG_ 2566850840 DriveMotor_Voltage 18001;
BA_ "SPN" SG_ 2566850840 DriveMotor_Cur 18000;
BA_ "GenSigStartValue" SG_ 2566890277 Signal_BMS20_Min_Cell_Temperatur 40;
BA_ "SystemSignalLongSymbol" SG_ 2566890277 Signal_BMS20_Min_Cell_Temperatur "Signal_BMS20_Min_Cell_Temperature";
BA_ "GenSigStartValue" SG_ 2566890277 Signal_BMS20_Max_Cell_Temperatur 40;
BA_ "SystemSignalLongSymbol" SG_ 2566890277 Signal_BMS20_Max_Cell_Temperatur "Signal_BMS20_Max_Cell_Temperature";
BA_ "GenSigStartValue" SG_ 2566890277 Signal_BMS20_Battery_Current 125;
BA_ "GenSigStartValue" SG_ 2566890021 Signal_BMS19_Min_Cell_Temperatur 40;
BA_ "SystemSignalLongSymbol" SG_ 2566890021 Signal_BMS19_Min_Cell_Temperatur "Signal_BMS19_Min_Cell_Temperature";
BA_ "GenSigStartValue" SG_ 2566890021 Signal_BMS19_Max_Cell_Temperatur 40;
BA_ "SystemSignalLongSymbol" SG_ 2566890021 Signal_BMS19_Max_Cell_Temperatur "Signal_BMS19_Max_Cell_Temperature";
BA_ "GenSigStartValue" SG_ 2566890021 Signal_BMS19_Battery_Current 125;
BA_ "GenSigStartValue" SG_ 2566889765 Signal_BMS18_Min_Cell_Temperatur 40;
BA_ "SystemSignalLongSymbol" SG_ 2566889765 Signal_BMS18_Min_Cell_Temperatur "Signal_BMS18_Min_Cell_Temperature";
BA_ "GenSigStartValue" SG_ 2566889765 Signal_BMS18_Max_Cell_Temperatur 40;
BA_ "SystemSignalLongSymbol" SG_ 2566889765 Signal_BMS18_Max_Cell_Temperatur "Signal_BMS18_Max_Cell_Temperature";
BA_ "GenSigStartValue" SG_ 2566889765 Signal_BMS18_Battery_Current 125;
BA_ "GenSigStartValue" SG_ 2566889509 Signal_BMS17_Min_Cell_Temperatur 40;
BA_ "SystemSignalLongSymbol" SG_ 2566889509 Signal_BMS17_Min_Cell_Temperatur "Signal_BMS17_Min_Cell_Temperature";
BA_ "GenSigStartValue" SG_ 2566889509 Signal_BMS17_Max_Cell_Temperatur 40;
BA_ "SystemSignalLongSymbol" SG_ 2566889509 Signal_BMS17_Max_Cell_Temperatur "Signal_BMS17_Max_Cell_Temperature";
BA_ "GenSigStartValue" SG_ 2566889509 Signal_BMS17_Battery_Current 125;
BA_ "GenSigStartValue" SG_ 2566909733 Signal_BMS16_Min_Cell_Temperatur 40;
BA_ "SystemSignalLongSymbol" SG_ 2566909733 Signal_BMS16_Min_Cell_Temperatur "Signal_BMS16_Min_Cell_Temperature";
BA_ "GenSigStartValue" SG_ 2566909733 Signal_BMS16_Max_Cell_Temperatur 40;
BA_ "SystemSignalLongSymbol" SG_ 2566909733 Signal_BMS16_Max_Cell_Temperatur "Signal_BMS16_Max_Cell_Temperature";
BA_ "GenSigStartValue" SG_ 2566909733 Signal_BMS16_Battery_Current 125;
BA_ "GenSigStartValue" SG_ 2566909477 Signal_BMS15_Min_Cell_Temperatur 40;
BA_ "SystemSignalLongSymbol" SG_ 2566909477 Signal_BMS15_Min_Cell_Temperatur "Signal_BMS15_Min_Cell_Temperature";
BA_ "GenSigStartValue" SG_ 2566909477 Signal_BMS15_Max_Cell_Temperatur 40;
BA_ "SystemSignalLongSymbol" SG_ 2566909477 Signal_BMS15_Max_Cell_Temperatur "Signal_BMS15_Max_Cell_Temperature";
BA_ "GenSigStartValue" SG_ 2566909477 Signal_BMS15_Battery_Current 125;
BA_ "GenSigStartValue" SG_ 2566909221 Signal_BMS14_Min_Cell_Temperatur 40;
BA_ "SystemSignalLongSymbol" SG_ 2566909221 Signal_BMS14_Min_Cell_Temperatur "Signal_BMS14_Min_Cell_Temperature";
BA_ "GenSigStartValue" SG_ 2566909221 Signal_BMS14_Max_Cell_Temperatur 40;
BA_ "SystemSignalLongSymbol" SG_ 2566909221 Signal_BMS14_Max_Cell_Temperatur "Signal_BMS14_Max_Cell_Temperature";
BA_ "GenSigStartValue" SG_ 2566909221 Signal_BMS14_Battery_Current 125;
BA_ "SystemSignalLongSymbol" SG_ 2566894629 Signal_BSC_Power_Distribution_St "Signal_BSC_Power_Distribution_Status_20";
BA_ "SystemSignalLongSymbol" SG_ 2566894373 Signal_BSC_Power_Distributi_0000 "Signal_BSC_Power_Distribution_Status_19";
BA_ "SystemSignalLongSymbol" SG_ 2566894117 Signal_BSC_Power_Distributi_0001 "Signal_BSC_Power_Distribution_Status_18";
BA_ "SystemSignalLongSymbol" SG_ 2566893861 Signal_BSC_Power_Distributi_0002 "Signal_BSC_Power_Distribution_Status_17";
BA_ "SystemSignalLongSymbol" SG_ 2566893605 Signal_BSC_Power_Distributi_0003 "Signal_BSC_Power_Distribution_Status_16";
BA_ "GenSigStartValue" SG_ 2566864933 Signal_Chiller1_MedTemp 40;
BA_ "SystemSignalLongSymbol" SG_ 2566902565 Signal_Battery_DM1_LampStatus_00 "Signal_Battery_DM1_LampStatus_004";
BA_ "SystemSignalLongSymbol" SG_ 2566902565 Signal_Battery_DM1_FlashStatus_0 "Signal_Battery_DM1_FlashStatus_004";
BA_ "SystemSignalLongSymbol" SG_ 2566902309 Signal_Battery_DM1_LampStat_0000 "Signal_Battery_DM1_LampStatus_003";
BA_ "SystemSignalLongSymbol" SG_ 2566902309 Signal_Battery_DM1_FlashSta_0000 "Signal_Battery_DM1_FlashStatus_003";
BA_ "SystemSignalLongSymbol" SG_ 2566902053 Signal_Battery_DM1_LampStat_0001 "Signal_Battery_DM1_LampStatus_002";
BA_ "SystemSignalLongSymbol" SG_ 2566902053 Signal_Battery_DM1_FlashSta_0001 "Signal_Battery_DM1_FlashStatus_002";
BA_ "SystemSignalLongSymbol" SG_ 2566901797 Signal_Battery_DM1_LampStat_0002 "Signal_Battery_DM1_LampStatus_001";
BA_ "SystemSignalLongSymbol" SG_ 2566901797 Signal_Battery_DM1_FlashSta_0002 "Signal_Battery_DM1_FlashStatus_001";
BA_ "SystemSignalLongSymbol" SG_ 2566861861 MaximumBatterySystemVoltageaccur "MaximumBatterySystemVoltageaccuracy";
BA_ "GenSigStartValue" SG_ 2566908965 Signal_BMS13_Min_Cell_Temperatur 40;
BA_ "SystemSignalLongSymbol" SG_ 2566908965 Signal_BMS13_Min_Cell_Temperatur "Signal_BMS13_Min_Cell_Temperature";
BA_ "GenSigStartValue" SG_ 2566908965 Signal_BMS13_Max_Cell_Temperatur 40;
BA_ "SystemSignalLongSymbol" SG_ 2566908965 Signal_BMS13_Max_Cell_Temperatur "Signal_BMS13_Max_Cell_Temperature";
BA_ "GenSigStartValue" SG_ 2566908965 Signal_BMS13_Battery_Current 125;
BA_ "GenSigStartValue" SG_ 2566908709 Signal_BMS12_Min_Cell_Temperatur 40;
BA_ "SystemSignalLongSymbol" SG_ 2566908709 Signal_BMS12_Min_Cell_Temperatur "Signal_BMS12_Min_Cell_Temperature";
BA_ "GenSigStartValue" SG_ 2566908709 Signal_BMS12_Max_Cell_Temperatur 40;
BA_ "SystemSignalLongSymbol" SG_ 2566908709 Signal_BMS12_Max_Cell_Temperatur "Signal_BMS12_Max_Cell_Temperature";
BA_ "GenSigStartValue" SG_ 2566908709 Signal_BMS12_Battery_Current 125;
BA_ "GenSigStartValue" SG_ 2566908453 Signal_BMS11_Min_Cell_Temperatur 40;
BA_ "SystemSignalLongSymbol" SG_ 2566908453 Signal_BMS11_Min_Cell_Temperatur "Signal_BMS11_Min_Cell_Temperature";
BA_ "GenSigStartValue" SG_ 2566908453 Signal_BMS11_Max_Cell_Temperatur 40;
BA_ "SystemSignalLongSymbol" SG_ 2566908453 Signal_BMS11_Max_Cell_Temperatur "Signal_BMS11_Max_Cell_Temperature";
BA_ "GenSigStartValue" SG_ 2566908453 Signal_BMS11_Battery_Current 125;
BA_ "GenSigStartValue" SG_ 2566908197 Signal_BMS10_Min_Cell_Temperatur 40;
BA_ "SystemSignalLongSymbol" SG_ 2566908197 Signal_BMS10_Min_Cell_Temperatur "Signal_BMS10_Min_Cell_Temperature";
BA_ "GenSigStartValue" SG_ 2566908197 Signal_BMS10_Max_Cell_Temperatur 40;
BA_ "SystemSignalLongSymbol" SG_ 2566908197 Signal_BMS10_Max_Cell_Temperatur "Signal_BMS10_Max_Cell_Temperature";
BA_ "GenSigStartValue" SG_ 2566908197 Signal_BMS10_Battery_Current 125;
BA_ "GenSigStartValue" SG_ 2566907941 Signal_BMS09_Min_Cell_Temperatur 40;
BA_ "SystemSignalLongSymbol" SG_ 2566907941 Signal_BMS09_Min_Cell_Temperatur "Signal_BMS09_Min_Cell_Temperature";
BA_ "GenSigStartValue" SG_ 2566907941 Signal_BMS09_Max_Cell_Temperatur 40;
BA_ "SystemSignalLongSymbol" SG_ 2566907941 Signal_BMS09_Max_Cell_Temperatur "Signal_BMS09_Max_Cell_Temperature";
BA_ "GenSigStartValue" SG_ 2566907941 Signal_BMS09_Battery_Current 125;
BA_ "GenSigStartValue" SG_ 2566907685 Signal_BMS08_Min_Cell_Temperatur 40;
BA_ "SystemSignalLongSymbol" SG_ 2566907685 Signal_BMS08_Min_Cell_Temperatur "Signal_BMS08_Min_Cell_Temperature";
BA_ "GenSigStartValue" SG_ 2566907685 Signal_BMS08_Max_Cell_Temperatur 40;
BA_ "SystemSignalLongSymbol" SG_ 2566907685 Signal_BMS08_Max_Cell_Temperatur "Signal_BMS08_Max_Cell_Temperature";
BA_ "GenSigStartValue" SG_ 2566907685 Signal_BMS08_Battery_Current 125;
BA_ "GenSigStartValue" SG_ 2566907429 Signal_BMS07_Min_Cell_Temperatur 40;
BA_ "SystemSignalLongSymbol" SG_ 2566907429 Signal_BMS07_Min_Cell_Temperatur "Signal_BMS07_Min_Cell_Temperature";
BA_ "GenSigStartValue" SG_ 2566907429 Signal_BMS07_Max_Cell_Temperatur 40;
BA_ "SystemSignalLongSymbol" SG_ 2566907429 Signal_BMS07_Max_Cell_Temperatur "Signal_BMS07_Max_Cell_Temperature";
BA_ "GenSigStartValue" SG_ 2566907429 Signal_BMS07_Battery_Current 125;
BA_ "GenSigStartValue" SG_ 2566907173 Signal_BMS06_Min_Cell_Temperatur 40;
BA_ "SystemSignalLongSymbol" SG_ 2566907173 Signal_BMS06_Min_Cell_Temperatur "Signal_BMS06_Min_Cell_Temperature";
BA_ "GenSigStartValue" SG_ 2566907173 Signal_BMS06_Max_Cell_Temperatur 40;
BA_ "SystemSignalLongSymbol" SG_ 2566907173 Signal_BMS06_Max_Cell_Temperatur "Signal_BMS06_Max_Cell_Temperature";
BA_ "GenSigStartValue" SG_ 2566907173 Signal_BMS06_Battery_Current 125;
BA_ "GenSigStartValue" SG_ 2566906917 Signal_BMS05_Min_Cell_Temperatur 40;
BA_ "SystemSignalLongSymbol" SG_ 2566906917 Signal_BMS05_Min_Cell_Temperatur "Signal_BMS05_Min_Cell_Temperature";
BA_ "GenSigStartValue" SG_ 2566906917 Signal_BMS05_Max_Cell_Temperatur 40;
BA_ "SystemSignalLongSymbol" SG_ 2566906917 Signal_BMS05_Max_Cell_Temperatur "Signal_BMS05_Max_Cell_Temperature";
BA_ "GenSigStartValue" SG_ 2566906917 Signal_BMS05_Battery_Current 125;
BA_ "GenSigStartValue" SG_ 2566906661 Signal_BMS04_Min_Cell_Temperatur 40;
BA_ "SystemSignalLongSymbol" SG_ 2566906661 Signal_BMS04_Min_Cell_Temperatur "Signal_BMS04_Min_Cell_Temperature";
BA_ "GenSigStartValue" SG_ 2566906661 Signal_BMS04_Max_Cell_Temperatur 40;
BA_ "SystemSignalLongSymbol" SG_ 2566906661 Signal_BMS04_Max_Cell_Temperatur "Signal_BMS04_Max_Cell_Temperature";
BA_ "GenSigStartValue" SG_ 2566906661 Signal_BMS04_Battery_Current 125;
BA_ "GenSigStartValue" SG_ 2566906405 Signal_BMS03_Min_Cell_Temperatur 40;
BA_ "SystemSignalLongSymbol" SG_ 2566906405 Signal_BMS03_Min_Cell_Temperatur "Signal_BMS03_Min_Cell_Temperature";
BA_ "GenSigStartValue" SG_ 2566906405 Signal_BMS03_Max_Cell_Temperatur 40;
BA_ "SystemSignalLongSymbol" SG_ 2566906405 Signal_BMS03_Max_Cell_Temperatur "Signal_BMS03_Max_Cell_Temperature";
BA_ "GenSigStartValue" SG_ 2566906405 Signal_BMS03_Battery_Current 125;
BA_ "GenSigStartValue" SG_ 2566906149 Signal_BMS02_Min_Cell_Temperatur 40;
BA_ "SystemSignalLongSymbol" SG_ 2566906149 Signal_BMS02_Min_Cell_Temperatur "Signal_BMS02_Min_Cell_Temperature";
BA_ "GenSigStartValue" SG_ 2566906149 Signal_BMS02_Max_Cell_Temperatur 40;
BA_ "SystemSignalLongSymbol" SG_ 2566906149 Signal_BMS02_Max_Cell_Temperatur "Signal_BMS02_Max_Cell_Temperature";
BA_ "GenSigStartValue" SG_ 2566906149 Signal_BMS02_Battery_Current 125;
BA_ "GenSigStartValue" SG_ 2566905893 Signal_BMS01_Min_Cell_Temperatur 40;
BA_ "SystemSignalLongSymbol" SG_ 2566905893 Signal_BMS01_Min_Cell_Temperatur "Signal_BMS01_Min_Cell_Temperature";
BA_ "GenSigStartValue" SG_ 2566905893 Signal_BMS01_Max_Cell_Temperatur 40;
BA_ "SystemSignalLongSymbol" SG_ 2566905893 Signal_BMS01_Max_Cell_Temperatur "Signal_BMS01_Max_Cell_Temperature";
BA_ "GenSigStartValue" SG_ 2566905893 Signal_BMS01_Battery_Current 125;
BA_ "SystemSignalLongSymbol" SG_ 2558534951 StoredEnergyCharge_DischargeRate "StoredEnergyCharge_DischargeRateRequest";
BA_ "SystemSignalLongSymbol" SG_ 2558534951 ExternalEnergySourceConnetionDem "ExternalEnergySourceConnetionDemand";
BA_ "SystemSignalLongSymbol" SG_ 2558534951 HybridSystemRegenerativeBrakingD "HybridSystemRegenerativeBrakingDisableRequest";
BA_ "SystemSignalLongSymbol" SG_ 2558534951 HybridSystemPropulsionDisableReq "HybridSystemPropulsionDisableRequest";
BA_ "SystemSignalLongSymbol" SG_ 2558534951 HybridSystemProtectionOverrideRe "HybridSystemProtectionOverrideRequest";
BA_ "SystemSignalLongSymbol" SG_ 2566909989 Signal_PDM_Isolation_Short_Circu "Signal_PDM_Isolation_Short_Circuit_Vcc_Status";
BA_ "SystemSignalLongSymbol" SG_ 2566909989 Signal_PDM_Isolation_Short__0000 "Signal_PDM_Isolation_Short_Circuit_Gnd_Status";
BA_ "SystemSignalLongSymbol" SG_ 2566909989 Signal_PDM_Isolation_KL31_Fault_ "Signal_PDM_Isolation_KL31_Fault_Status";
BA_ "SystemSignalLongSymbol" SG_ 2566909989 Signal_PDM_Isolation_Error_Devic "Signal_PDM_Isolation_Error_Device_Fault_Status";
BA_ "SystemSignalLongSymbol" SG_ 2566909989 Signal_PDM_Bender_Output_Frequen "Signal_PDM_Bender_Output_Frequency";
BA_ "SystemSignalLongSymbol" SG_ 2566909989 Signal_PDM_Bender_Output_Duty_Cy "Signal_PDM_Bender_Output_Duty_Cycle";
BA_ "SystemSignalLongSymbol" SG_ 2566909989 Signal_PDM_Current_Operational_S "Signal_PDM_Current_Operational_Substate";
BA_ "SystemSignalLongSymbol" SG_ 2566909989 Signal_PDM_Current_Charge_Substa "Signal_PDM_Current_Charge_Substate";
VAL_ 3221225472 BTMDemandPowerHighLowBytes_Copy_ 65535 "Invalid" ;
VAL_ 3221225472 PropulsionSystemActive 3 "Not_available" 2 "SAE_reserved" 1 "Ready_to_move_vehicle" 0 "Not_ready_to_move_vehicle" ;
VAL_ 3221225472 HybridSystemWarningIndicator 3 "Not_available" 2 "Flashing" 1 "On" 0 "Off" ;
VAL_ 3221225472 HybridSystemStopIndicator 3 "Not_available" 2 "Flashing" 1 "On" 0 "Off" ;
VAL_ 3221225472 HybridSystemServiceIndicator 3 "Not_available" 2 "Flashing" 1 "On" 0 "Off" ;
VAL_ 3221225472 HybridSystemRegenerativeBrakingI 3 "Not_available" 2 "Disabled_or_fault" 1 "Active" 0 "Not_active" ;
VAL_ 3221225472 HybridSystemOverheatIndicator 3 "Not_available" 2 "Flashing" 1 "On" 0 "Off" ;
VAL_ 3221225472 HybridSystemOBDRelatedDTCStatus 3 "Not_available" 2 "SAE_reserved" 1 "Active_OBD_related_DTC" 0 "No_active_OBD_related_DTC" ;
VAL_ 3221225472 HybridSystemMotorOverspeedIndica 3 "Not_available" 2 "Flashing" 1 "On" 0 "Off" ;
VAL_ 3221225472 HybridSystemMotorOverspeedAlarm 3 "Not_available" 2 "Error" 1 "On" 0 "Off" ;
VAL_ 3221225472 HybridSystemInitialisationIndica 3 "Not_available" 2 "Error" 1 "Active" 0 "Not_active" ;
VAL_ 3221225472 HybridSystemHighVoltageExposureI 3 "Not_operational" 2 "Error" 1 "A_potential_high_voltage_exposure_has_been_detected" 0 "No_potential_high_voltage_exposure_has_been_detected" ;
VAL_ 3221225472 HybridSystemEngineAssistStatus 3 "Not_available" 2 "Error" 1 "Hybrid_system_may_or_may_not_mechanically_assist_engine_rotation" 0 "Hybrid_system_is_not_mechanically_assisting_engine_rotation" ;
VAL_ 3221225472 HybridSystemElectricAlternatorIn 3 "Not_available" 2 "Flashing" 1 "On" 0 "Off" ;
VAL_ 3221225472 HybridPropulsionModeTransitionSt 15 "Not_available" 14 "Error" 13 "Requested_mode_denied_reason not specified" 12 "Reserved" 11 "Reserved" 10 "Reserved" 9 "Reserved" 8 "Reserved" 7 "Reserved" 6 "Reserved" 5 "Requested_mode_denied_temporary_limit_exceeded" 4 "Requested_mode_denied_HVES_state_of_charge_unacceptable" 3 "Requested_mode_denied_vehicle_speed_unacceptable" 2 "Requested_mode_denied - requested_mode_not_available" 1 "Transistion_requested_and_in_process" 0 "No_transition_requested" ;
VAL_ 3221225472 HybridPropulsionModeStatus 15 "Not_available" 14 "Error" 13 "Reserved" 12 "Reserved" 11 "Reserved" 10 "Reserved" 9 "Reserved" 8 "Reserved" 7 "Reserved" 6 "Reserved" 5 "Stored_energy_source_only" 4 "Stored_energy_source_offline" 3 "Stored_energy_source_depleting" 2 "Stored_energy_source_increasing" 1 "Stored_energy_source_sustaining" 0 "No_mode_requested" ;
VAL_ 3221225472 ExternalEnergySourceConnectionSt 15 "Not_available" 14 "Error" 13 "Reserved" 12 "Reserved" 11 "Reserved" 10 "Reserved" 9 "Connected - energy drain 2" 8 "Connected - energy source 2" 7 "Connected - energy source and drain 2" 6 "Connected - Verification in process 2" 5 "Connected - energy drain 1" 4 "Connected - energy source 1" 3 "Connected - energy source and drain 1" 2 "Connected - Verification in process 1" 1 "Connection - error (verification failed)" 0 "No connection" ;
VAL_ 3221225472 PowerOnSignal 0 "Remain in state" 1 "Powering up" 2 "Error" 3 "Not_available" ;
VAL_ 3221225472 DestinationMode 7 "Not_available" 6 "Error" 5 "Error" 4 "Overnight_Charge" 3 "In_service_Charge" 2 "Drive" 1 "Standby" 0 "Error" ;
VAL_ 3221225472 CurrentVehicleMode 7 "Not_available" 6 "Error" 5 "Error" 4 "Overnight_Charge" 3 "In_service_Charge" 2 "Drive" 1 "Standby" 0 "Off" ;
VAL_ 3221225472 VCUSendsBusVoltHighLowBytes 65535 "Invalid" ;
VAL_ 3221225472 BTMDemandPowerHighLowBytes 65535 "Invalid" ;
VAL_ 3221225472 MainContactorState 3 "Unavailable" 2 "Error" 1 "Closed" 0 "Opened" ;
VAL_ 2566834712 FlashRedStopLamp 3 "Unavailable / Do Not Flash" 2 "Reserved" 1 "Fast Flash" 0 "Slow Flash" ;
VAL_ 2566834712 FlashProtectLamp 3 "Unavailable / Do Not Flash" 2 "Reserved" 1 "Fast Flash" 0 "Slow Flash" ;
VAL_ 2566834712 FlashMalfuncIndicatorLamp 3 "Unavailable / Do Not Flash" 2 "Reserved" 1 "Fast Flash" 0 "Slow Flash" ;
VAL_ 2566834712 FlashAmberWarningLamp 3 "Unavailable / Do Not Flash" 2 "Reserved" 1 "Fast Flash" 0 "Slow Flash" ;
VAL_ 2566834712 MalfunctionIndicatorLampStatus 3 "Not available" 2 "Reserved" 1 "Lamp on" 0 "Lamp off" ;
VAL_ 2566834712 AmberWarningLampStatus 3 "Not available" 2 "Reserved" 1 "Lamp on" 0 "Lamp off" ;
VAL_ 2566834712 RedStopLampState 3 "Not available" 2 "Reserved" 1 "Lamp on" 0 "Lamp off" ;
VAL_ 2566834712 ProtectLampStatus 65280 "SNA" 65024 "ERR" 64512 "RES" 64256 "Parameter Specific Indicator" 3 "Not available" 2 "Reserved" 1 "Lamp on" 0 "Lamp off" ;
VAL_ 2566834809 FlashRedStopLamp 3 "Unavailable / Do Not Flash" 2 "Reserved" 1 "Fast Flash" 0 "Slow Flash" ;
VAL_ 2566834809 FlashProtectLamp 3 "Unavailable / Do Not Flash" 2 "Reserved" 1 "Fast Flash" 0 "Slow Flash" ;
VAL_ 2566834809 FlashMalfuncIndicatorLamp 3 "Unavailable / Do Not Flash" 2 "Reserved" 1 "Fast Flash" 0 "Slow Flash" ;
VAL_ 2566834809 FlashAmberWarningLamp 3 "Unavailable / Do Not Flash" 2 "Reserved" 1 "Fast Flash" 0 "Slow Flash" ;
VAL_ 2566834809 MalfunctionIndicatorLampStatus 3 "Not available" 2 "Reserved" 1 "Lamp on" 0 "Lamp off" ;
VAL_ 2566834809 AmberWarningLampStatus 3 "Not available" 2 "Reserved" 1 "Lamp on" 0 "Lamp off" ;
VAL_ 2566834809 RedStopLampState 3 "Not available" 2 "Reserved" 1 "Lamp on" 0 "Lamp off" ;
VAL_ 2566834809 ProtectLampStatus 65280 "SNA" 65024 "ERR" 64512 "RES" 64256 "Parameter Specific Indicator" 3 "Not available" 2 "Reserved" 1 "Lamp on" 0 "Lamp off" ;
VAL_ 2566913664 IRBIS_States 0 "InverterOff" 1 "IdleMode
" 2 "StandbyMode" 3 "NormalMode" ;
VAL_ 2566913664 TMS_States 0 "Off/Shut Down" 1 "Refrengiration Mode" 2 "Heating Mode" 3 "Water Cycle Mode" ;
VAL_ 2566834789 FlashRedStopLamp 3 "Unavailable / Do Not Flash" 2 "Reserved" 1 "Fast Flash" 0 "Slow Flash" ;
VAL_ 2566834789 FlashProtectLamp 3 "Unavailable / Do Not Flash" 2 "Reserved" 1 "Fast Flash" 0 "Slow Flash" ;
VAL_ 2566834789 FlashMalfuncIndicatorLamp 3 "Unavailable / Do Not Flash" 2 "Reserved" 1 "Fast Flash" 0 "Slow Flash" ;
VAL_ 2566834789 FlashAmberWarningLamp 3 "Unavailable / Do Not Flash" 2 "Reserved" 1 "Fast Flash" 0 "Slow Flash" ;
VAL_ 2566834789 MalfunctionIndicatorLampStatus 3 "Not available" 2 "Reserved" 1 "Lamp on" 0 "Lamp off" ;
VAL_ 2566834789 AmberWarningLampStatus 3 "Not available" 2 "Reserved" 1 "Lamp on" 0 "Lamp off" ;
VAL_ 2566834789 RedStopLampState 3 "Not available" 2 "Reserved" 1 "Lamp on" 0 "Lamp off" ;
VAL_ 2566834789 ProtectLampStatus 65280 "SNA" 65024 "ERR" 64512 "RES" 64256 "Parameter Specific Indicator" 3 "Not available" 2 "Reserved" 1 "Lamp on" 0 "Lamp off" ;
VAL_ 2566834790 FlashRedStopLamp 3 "Unavailable / Do Not Flash" 2 "Reserved" 1 "Fast Flash" 0 "Slow Flash" ;
VAL_ 2566834790 FlashProtectLamp 3 "Unavailable / Do Not Flash" 2 "Reserved" 1 "Fast Flash" 0 "Slow Flash" ;
VAL_ 2566834790 FlashMalfuncIndicatorLamp 3 "Unavailable / Do Not Flash" 2 "Reserved" 1 "Fast Flash" 0 "Slow Flash" ;
VAL_ 2566834790 FlashAmberWarningLamp 3 "Unavailable / Do Not Flash" 2 "Reserved" 1 "Fast Flash" 0 "Slow Flash" ;
VAL_ 2566834790 MalfunctionIndicatorLampStatus 3 "Not available" 2 "Reserved" 1 "Lamp on" 0 "Lamp off" ;
VAL_ 2566834790 AmberWarningLampStatus 3 "Not available" 2 "Reserved" 1 "Lamp on" 0 "Lamp off" ;
VAL_ 2566834790 RedStopLampState 3 "Not available" 2 "Reserved" 1 "Lamp on" 0 "Lamp off" ;
VAL_ 2566834790 ProtectLampStatus 65280 "SNA" 65024 "ERR" 64512 "RES" 64256 "Parameter Specific Indicator" 3 "Not available" 2 "Reserved" 1 "Lamp on" 0 "Lamp off" ;
VAL_ 2566890277 Signal_BMS20_Operating_Status 2 "Failure" 1 "Downgraded" 0 "Normal" ;
VAL_ 2566890277 Signal_BMS20_Actual_State 3 "Charge" 2 "Operational" 1 "Standby" 0 "Off" ;
VAL_ 2566890021 Signal_BMS19_Operating_Status 2 "Failure" 1 "Downgraded" 0 "Normal" ;
VAL_ 2566890021 Signal_BMS19_Actual_State 3 "Charge" 2 "Operational" 1 "Standby" 0 "Off" ;
VAL_ 2566889765 Signal_BMS18_Operating_Status 2 "Failure" 1 "Downgraded" 0 "Normal" ;
VAL_ 2566889765 Signal_BMS18_Actual_State 3 "Charge" 2 "Operational" 1 "Standby" 0 "Off" ;
VAL_ 2566889509 Signal_BMS17_Operating_Status 2 "Failure" 1 "Downgraded" 0 "Normal" ;
VAL_ 2566889509 Signal_BMS17_Actual_State 3 "Charge" 2 "Operational" 1 "Standby" 0 "Off" ;
VAL_ 2566909733 Signal_BMS16_Operating_Status 2 "Failure" 1 "Downgraded" 0 "Normal" ;
VAL_ 2566909733 Signal_BMS16_Actual_State 3 "Charge" 2 "Operational" 1 "Standby" 0 "Off" ;
VAL_ 2566909477 Signal_BMS15_Operating_Status 2 "Failure" 1 "Downgraded" 0 "Normal" ;
VAL_ 2566909477 Signal_BMS15_Actual_State 3 "Charge" 2 "Operational" 1 "Standby" 0 "Off" ;
VAL_ 2566909221 Signal_BMS14_Operating_Status 2 "Failure" 1 "Downgraded" 0 "Normal" ;
VAL_ 2566909221 Signal_BMS14_Actual_State 3 "Charge" 2 "Operational" 1 "Standby" 0 "Off" ;
VAL_ 2566894629 Signal_BSC_Operating_Status_20 2 "Failure" 1 "Downgraded" 0 "Normal" ;
VAL_ 2566894629 Signal_BSC_Power_Distribution_St 2 "Distributed" 1 "Distribution_in_progress" 0 "Not_distributed" ;
VAL_ 2566894629 Signal_BSC_Transition_Status_20 2 "Transition_in_progress" 1 "Transition_failed" 0 "Transition_Ok" ;
VAL_ 2566894629 Signal_BSC_Requested_State_20 3 "Charge" 2 "Operational" 1 "Standby" 0 "Off" ;
VAL_ 2566894629 Signal_BSC_Actual_Transition_20 5 "No_transition" 4 "Disconnection" 3 "Connection_to_charge" 2 "Connection_to_operational" 1 "Shutdown_BMS" 0 "Wakeup_BMS" ;
VAL_ 2566894629 Signal_BSC_Actual_State_20 3 "Charge" 2 "Operational" 1 "Standby" 0 "Off" ;
VAL_ 2566894373 Signal_BSC_Operating_Status_19 2 "Failure" 1 "Downgraded" 0 "Normal" ;
VAL_ 2566894373 Signal_BSC_Power_Distributi_0000 2 "Distributed" 1 "Distribution_in_progress" 0 "Not_distributed" ;
VAL_ 2566894373 Signal_BSC_Transition_Status_19 2 "Transition_in_progress" 1 "Transition_failed" 0 "Transition_Ok" ;
VAL_ 2566894373 Signal_BSC_Actual_Transition_19 5 "No_transition" 4 "Disconnection" 3 "Connection_to_charge" 2 "Connection_to_operational" 1 "Shutdown_BMS" 0 "Wakeup_BMS" ;
VAL_ 2566894373 Signal_BSC_Actual_State_19 3 "Charge" 2 "Operational" 1 "Standby" 0 "Off" ;
VAL_ 2566894373 Signal_BSC_Requested_State_19 3 "Charge" 2 "Operational" 1 "Standby" 0 "Off" ;
VAL_ 2566894117 Signal_BSC_Operating_Status_18 2 "Failure" 1 "Downgraded" 0 "Normal" ;
VAL_ 2566894117 Signal_BSC_Power_Distributi_0001 2 "Distributed" 1 "Distribution_in_progress" 0 "Not_distributed" ;
VAL_ 2566894117 Signal_BSC_Transition_Status_18 2 "Transition_in_progress" 1 "Transition_failed" 0 "Transition_Ok" ;
VAL_ 2566894117 Signal_BSC_Requested_State_18 3 "Charge" 2 "Operational" 1 "Standby" 0 "Off" ;
VAL_ 2566894117 Signal_BSC_Actual_Transition_18 5 "No_transition" 4 "Disconnection" 3 "Connection_to_charge" 2 "Connection_to_operational" 1 "Shutdown_BMS" 0 "Wakeup_BMS" ;
VAL_ 2566894117 Signal_BSC_Actual_State_18 3 "Charge" 2 "Operational" 1 "Standby" 0 "Off" ;
VAL_ 2566893861 Signal_BSC_Operating_Status_17 2 "Failure" 1 "Downgraded" 0 "Normal" ;
VAL_ 2566893861 Signal_BSC_Power_Distributi_0002 2 "Distributed" 1 "Distribution_in_progress" 0 "Not_distributed" ;
VAL_ 2566893861 Signal_BSC_Transition_Status_17 2 "Transition_in_progress" 1 "Transition_failed" 0 "Transition_Ok" ;
VAL_ 2566893861 Signal_BSC_Requested_State_17 3 "Charge" 2 "Operational" 1 "Standby" 0 "Off" ;
VAL_ 2566893861 Signal_BSC_Actual_Transition_17 5 "No_transition" 4 "Disconnection" 3 "Connection_to_charge" 2 "Connection_to_operational" 1 "Shutdown_BMS" 0 "Wakeup_BMS" ;
VAL_ 2566893861 Signal_BSC_Actual_State_17 3 "Charge" 2 "Operational" 1 "Standby" 0 "Off" ;
VAL_ 2566893605 Signal_BSC_Operating_Status_16 2 "Failure" 1 "Downgraded" 0 "Normal" ;
VAL_ 2566893605 Signal_BSC_Power_Distributi_0003 2 "Distributed" 1 "Distribution_in_progress" 0 "Not_distributed" ;
VAL_ 2566893605 Signal_BSC_Transition_Status_16 2 "Transition_in_progress" 1 "Transition_failed" 0 "Transition_Ok" ;
VAL_ 2566893605 Signal_BSC_Requested_State_16 3 "Charge" 2 "Operational" 1 "Standby" 0 "Off" ;
VAL_ 2566893605 Signal_BSC_Actual_Transition_16 5 "No_transition" 4 "Disconnection" 3 "Connection_to_charge" 2 "Connection_to_operational" 1 "Shutdown_BMS" 0 "Wakeup_BMS" ;
VAL_ 2566893605 Signal_BSC_Actual_State_16 3 "Charge" 2 "Operational" 1 "Standby" 0 "Off" ;
VAL_ 2566908965 Signal_BMS13_Operating_Status 2 "Failure" 1 "Downgraded" 0 "Normal" ;
VAL_ 2566908965 Signal_BMS13_Actual_State 3 "Charge" 2 "Operational" 1 "Standby" 0 "Off" ;
VAL_ 2566908709 Signal_BMS12_Operating_Status 2 "Failure" 1 "Downgraded" 0 "Normal" ;
VAL_ 2566908709 Signal_BMS12_Actual_State 3 "Charge" 2 "Operational" 1 "Standby" 0 "Off" ;
VAL_ 2566908453 Signal_BMS11_Operating_Status 2 "Failure" 1 "Downgraded" 0 "Normal" ;
VAL_ 2566908453 Signal_BMS11_Actual_State 3 "Charge" 2 "Operational" 1 "Standby" 0 "Off" ;
VAL_ 2566908197 Signal_BMS10_Operating_Status 2 "Failure" 1 "Downgraded" 0 "Normal" ;
VAL_ 2566908197 Signal_BMS10_Actual_State 3 "Charge" 2 "Operational" 1 "Standby" 0 "Off" ;
VAL_ 2566907941 Signal_BMS09_Operating_Status 2 "Failure" 1 "Downgraded" 0 "Normal" ;
VAL_ 2566907941 Signal_BMS09_Actual_State 3 "Charge" 2 "Operational" 1 "Standby" 0 "Off" ;
VAL_ 2566907685 Signal_BMS08_Operating_Status 2 "Failure" 1 "Downgraded" 0 "Normal" ;
VAL_ 2566907685 Signal_BMS08_Actual_State 3 "Charge" 2 "Operational" 1 "Standby" 0 "Off" ;
VAL_ 2566907429 Signal_BMS07_Operating_Status 2 "Failure" 1 "Downgraded" 0 "Normal" ;
VAL_ 2566907429 Signal_BMS07_Actual_State 3 "Charge" 2 "Operational" 1 "Standby" 0 "Off" ;
VAL_ 2566907173 Signal_BMS06_Operating_Status 2 "Failure" 1 "Downgraded" 0 "Normal" ;
VAL_ 2566907173 Signal_BMS06_Actual_State 3 "Charge" 2 "Operational" 1 "Standby" 0 "Off" ;
VAL_ 2566906917 Signal_BMS05_Operating_Status 2 "Failure" 1 "Downgraded" 0 "Normal" ;
VAL_ 2566906917 Signal_BMS05_Actual_State 3 "Charge" 2 "Operational" 1 "Standby" 0 "Off" ;
VAL_ 2566906661 Signal_BMS04_Operating_Status 2 "Failure" 1 "Downgraded" 0 "Normal" ;
VAL_ 2566906661 Signal_BMS04_Actual_State 3 "Charge" 2 "Operational" 1 "Standby" 0 "Off" ;
VAL_ 2566906405 Signal_BMS03_Operating_Status 2 "Failure" 1 "Downgraded" 0 "Normal" ;
VAL_ 2566906405 Signal_BMS03_Actual_State 3 "Charge" 2 "Operational" 1 "Standby" 0 "Off" ;
VAL_ 2566906149 Signal_BMS02_Operating_Status 2 "Failure" 1 "Downgraded" 0 "Normal" ;
VAL_ 2566906149 Signal_BMS02_Actual_State 3 "Charge" 2 "Operational" 1 "Standby" 0 "Off" ;
VAL_ 2566905893 Signal_BMS01_Operating_Status 2 "Failure" 1 "Downgraded" 0 "Normal" ;
VAL_ 2566905893 Signal_BMS01_Actual_State 3 "Charge" 2 "Operational" 1 "Standby" 0 "Off" ;
VAL_ 2558534951 ExternalEnergySourceConnetionDem 15 "No_Request" 14 "Disconnect_Request" 13 "Reserved" 12 "Reserved" 11 "Reserved" 10 "Reserved" 9 "Reserved" 8 "Energy_Drain2" 7 "Energy_Source2" 6 "Energy_Drain_or_Source2" 5 "Perform_Connection_Verification2" 4 "Energy_Drain1" 3 "Energy_Source1" 2 "Energy_Drain_or_Source1" 1 "Perform_Connection_Verification1" 0 "No_Connection" ;
VAL_ 2558534951 HybridPropulsionModeRequest 15 "Not_Available" 14 "Error" 13 "Reserved" 12 "Reserved" 11 "Reserved" 10 "Reserved" 9 "Reserved" 8 "Reserved" 7 "Reserved" 6 "Reserved" 5 "Stored_Energy_Source_Only" 4 "Stored_Energy_Source_Offline" 3 "Stored_Energy_Source_Depleting" 2 "Stored_Energy_Source_Increasing" 1 "Stored_Energy_Source_Sustaining" 0 "No_Mode_Requested" ;
VAL_ 2558534951 OperatorVehicleModeRequest 15 "Not_Available" 14 "Error" 13 "Reserved" 12 "Reserved" 11 "Reserved" 10 "Reserved" 9 "Reserved" 8 "Reserved" 7 "Reserved" 6 "Reserved" 5 "Reserved" 4 "Reserved" 3 "Propulsion_Active" 2 "Stored_Energy_Source_Active" 1 "Low_Voltage_Accessory" 0 "OFF" ;
VAL_ 2558534951 HybridSystemPropulsionDisableReq 3 "DONT_CARE" 2 "Reserved" 1 "ON" 0 "OFF" ;
VAL_ 2566909989 Signal_PDM_Current_Operational_S 1 "Connect_string" 0 "Find_available_string" ;
VAL_ 2566909989 Signal_PDM_Current_Charge_Substa 1 "Connect_string" 0 "Find_available_string" ;
VAL_ 2566909989 Signal_PDM_Actual_Transition 4 "No_transition" 3 "Disconnection" 2 "Connection" 1 "Shutdown_strings" 0 "Wakeup_strings" ;
VAL_ 2566909989 Signal_PDM_Actual_State 3 "Charge" 2 "Operational" 1 "Standby" 0 "Off" ;
SIG_VALTYPE_ 3221225472 Minutes : 1;
